VERSION ""

NS_ :

BS_:

BU_: CANOE BSM BSM2 CADM CVADAS ECM EPS ORC EVCU2

BO_ 2654552196 Distance_Point_Map_1: 64 CVADAS
 SG_ Point_Map_Cruising_Age_15 : 482|6@1+ (1,0) [0|63] ""  CANOE
 SG_ Point_Map_Cruising_Age_14 : 418|6@1+ (1,0) [0|63] ""  CANOE
 SG_ Point_Map_Cruising_Age_13 : 354|6@1+ (1,0) [0|63] ""  CANOE
 SG_ Point_Map_Cruising_Age_12 : 290|6@1+ (1,0) [0|63] ""  CANOE
 SG_ Point_Map_Cruising_Age_11 : 226|6@1+ (1,0) [0|63] ""  CANOE
 SG_ Point_Map_Cruising_Age_10 : 162|6@1+ (1,0) [0|63] ""  CANOE
 SG_ Point_Map_Cruising_Age_9 : 98|6@1+ (1,0) [0|63] ""  CANOE
 SG_ Point_Map_Cruising_Age_8 : 34|6@1+ (1,0) [0|63] ""  CANOE
 SG_ Point_Map_Reserved_8 : 56|8@1+ (1,0) [0|255] ""  CANOE
 SG_ Point_Map_Age_8 : 48|8@1+ (1,0) [0|255] ""  CANOE
 SG_ Point_Map_Confidence_8 : 40|8@1+ (1,0) [0|255] ""  CANOE
 SG_ Point_Map_Height_8 : 32|2@1+ (1,0) [0|3] ""  CANOE
 SG_ Point_Map_Y_8 : 16|16@1- (1,0) [-32768|32767] ""  CANOE
 SG_ Point_Map_X_8 : 0|16@1- (1,0) [-32768|32767] ""  CANOE
 SG_ Point_Map_Reserved_15 : 504|8@1+ (1,0) [0|255] ""  CANOE
 SG_ Point_Map_Reserved_14 : 440|8@1+ (1,0) [0|255] ""  CANOE
 SG_ Point_Map_Reserved_13 : 376|8@1+ (1,0) [0|255] ""  CANOE
 SG_ Point_Map_Reserved_12 : 312|8@1+ (1,0) [0|255] ""  CANOE
 SG_ Point_Map_Reserved_11 : 248|8@1+ (1,0) [0|255] ""  CANOE
 SG_ Point_Map_Reserved_10 : 184|8@1+ (1,0) [0|255] ""  CANOE
 SG_ Point_Map_Reserved_9 : 120|8@1+ (1,0) [0|255] ""  CANOE
 SG_ Point_Map_Age_15 : 496|8@1+ (1,0) [0|255] ""  CANOE
 SG_ Point_Map_Confidence_15 : 488|8@1+ (1,0) [0|255] ""  CANOE
 SG_ Point_Map_Height_15 : 480|2@1+ (1,0) [0|3] ""  CANOE
 SG_ Point_Map_Y_15 : 464|16@1- (1,0) [-32768|32767] ""  CANOE
 SG_ Point_Map_X_15 : 448|16@1- (1,0) [-32768|32767] ""  CANOE
 SG_ Point_Map_Age_14 : 432|8@1+ (1,0) [0|255] ""  CANOE
 SG_ Point_Map_Confidence_14 : 424|8@1+ (1,0) [0|255] ""  CANOE
 SG_ Point_Map_Height_14 : 416|2@1+ (1,0) [0|3] ""  CANOE
 SG_ Point_Map_Y_14 : 400|16@1- (1,0) [-32768|32767] ""  CANOE
 SG_ Point_Map_X_14 : 384|16@1- (1,0) [-32768|32767] ""  CANOE
 SG_ Point_Map_Age_13 : 368|8@1+ (1,0) [0|255] ""  CANOE
 SG_ Point_Map_Confidence_13 : 360|8@1+ (1,0) [0|255] ""  CANOE
 SG_ Point_Map_Height_13 : 352|2@1+ (1,0) [0|3] ""  CANOE
 SG_ Point_Map_Y_13 : 336|16@1- (1,0) [-32768|32767] ""  CANOE
 SG_ Point_Map_X_13 : 320|16@1- (1,0) [-32768|32767] ""  CANOE
 SG_ Point_Map_Age_12 : 304|8@1+ (1,0) [0|255] ""  CANOE
 SG_ Point_Map_Confidence_12 : 296|8@1+ (1,0) [0|255] ""  CANOE
 SG_ Point_Map_Height_12 : 288|2@1+ (1,0) [0|3] ""  CANOE
 SG_ Point_Map_Y_12 : 272|16@1- (1,0) [-32768|32767] ""  CANOE
 SG_ Point_Map_X_12 : 256|16@1- (1,0) [-32768|32767] ""  CANOE
 SG_ Point_Map_Age_11 : 240|8@1+ (1,0) [0|255] ""  CANOE
 SG_ Point_Map_Confidence_11 : 232|8@1+ (1,0) [0|255] ""  CANOE
 SG_ Point_Map_Height_11 : 224|2@1+ (1,0) [0|3] ""  CANOE
 SG_ Point_Map_Y_11 : 208|16@1- (1,0) [-32768|32767] ""  CANOE
 SG_ Point_Map_X_11 : 192|16@1- (1,0) [-32768|32767] ""  CANOE
 SG_ Point_Map_Age_10 : 176|8@1+ (1,0) [0|255] ""  CANOE
 SG_ Point_Map_Confidence_10 : 168|8@1+ (1,0) [0|255] ""  CANOE
 SG_ Point_Map_Height_10 : 160|2@1+ (1,0) [0|3] ""  CANOE
 SG_ Point_Map_Y_10 : 144|16@1- (1,0) [-32768|32767] ""  CANOE
 SG_ Point_Map_X_10 : 128|16@1- (1,0) [-32768|32767] ""  CANOE
 SG_ Point_Map_Age_9 : 112|8@1+ (1,0) [0|255] ""  CANOE
 SG_ Point_Map_Confidence_9 : 104|8@1+ (1,0) [0|255] ""  CANOE
 SG_ Point_Map_Height_9 : 96|2@1+ (1,0) [0|3] ""  CANOE
 SG_ Point_Map_Y_9 : 80|16@1- (1,0) [-32768|32767] ""  CANOE
 SG_ Point_Map_X_9 : 64|16@1- (1,0) [-32768|32767] ""  CANOE

BO_ 2654552195 Distance_Point_Map_0: 64 CVADAS
 SG_ Point_Map_Cruising_Age_7 : 482|6@1+ (1,0) [0|63] ""  CANOE
 SG_ Point_Map_Cruising_Age_6 : 418|6@1+ (1,0) [0|63] ""  CANOE
 SG_ Point_Map_Cruising_Age_5 : 354|6@1+ (1,0) [0|63] ""  CANOE
 SG_ Point_Map_Cruising_Age_4 : 290|6@1+ (1,0) [0|63] ""  CANOE
 SG_ Point_Map_Cruising_Age_3 : 226|6@1+ (1,0) [0|63] ""  CANOE
 SG_ Point_Map_Cruising_Age_2 : 162|6@1+ (1,0) [0|63] ""  CANOE
 SG_ Point_Map_Cruising_Age_1 : 98|6@1+ (1,0) [0|63] ""  CANOE
 SG_ Point_Map_Cruising_Age_0 : 34|6@1+ (1,0) [0|63] ""  CANOE
 SG_ Point_Map_Reserved_7 : 504|8@1+ (1,0) [0|255] ""  CANOE
 SG_ Point_Map_Reserved_6 : 440|8@1+ (1,0) [0|255] ""  CANOE
 SG_ Point_Map_Reserved_5 : 376|8@1+ (1,0) [0|255] ""  CANOE
 SG_ Point_Map_Reserved_4 : 312|8@1+ (1,0) [0|255] ""  CANOE
 SG_ Point_Map_Reserved_3 : 248|8@1+ (1,0) [0|255] ""  CANOE
 SG_ Point_Map_Reserved_2 : 184|8@1+ (1,0) [0|255] ""  CANOE
 SG_ Point_Map_Reserved_1 : 120|8@1+ (1,0) [0|255] ""  CANOE
 SG_ Point_Map_Reserved_0 : 56|8@1+ (1,0) [0|255] ""  CANOE
 SG_ Point_Map_Age_7 : 496|8@1+ (1,0) [0|255] ""  CANOE
 SG_ Point_Map_Confidence_7 : 488|8@1+ (1,0) [0|255] ""  CANOE
 SG_ Point_Map_Height_7 : 480|2@1+ (1,0) [0|3] ""  CANOE
 SG_ Point_Map_Y_7 : 464|16@1- (1,0) [-32768|32767] ""  CANOE
 SG_ Point_Map_X_7 : 448|16@1- (1,0) [-32768|32767] ""  CANOE
 SG_ Point_Map_Age_6 : 432|8@1+ (1,0) [0|255] ""  CANOE
 SG_ Point_Map_Confidence_6 : 424|8@1+ (1,0) [0|255] ""  CANOE
 SG_ Point_Map_Height_6 : 416|2@1+ (1,0) [0|3] ""  CANOE
 SG_ Point_Map_Y_6 : 400|16@1- (1,0) [-32768|32767] ""  CANOE
 SG_ Point_Map_X_6 : 384|16@1- (1,0) [-32768|32767] ""  CANOE
 SG_ Point_Map_Age_5 : 368|8@1+ (1,0) [0|255] ""  CANOE
 SG_ Point_Map_Confidence_5 : 360|8@1+ (1,0) [0|255] ""  CANOE
 SG_ Point_Map_Height_5 : 352|2@1+ (1,0) [0|3] ""  CANOE
 SG_ Point_Map_Y_5 : 336|16@1- (1,0) [-32768|32767] ""  CANOE
 SG_ Point_Map_X_5 : 320|16@1- (1,0) [-32768|32767] ""  CANOE
 SG_ Point_Map_Age_4 : 304|8@1+ (1,0) [0|255] ""  CANOE
 SG_ Point_Map_Confidence_4 : 296|8@1+ (1,0) [0|255] ""  CANOE
 SG_ Point_Map_Height_4 : 288|2@1+ (1,0) [0|3] ""  CANOE
 SG_ Point_Map_Y_4 : 272|16@1- (1,0) [-32768|32767] ""  CANOE
 SG_ Point_Map_X_4 : 256|16@1- (1,0) [-32768|32767] ""  CANOE
 SG_ Point_Map_Age_3 : 240|8@1+ (1,0) [0|255] ""  CANOE
 SG_ Point_Map_Confidence_3 : 232|8@1+ (1,0) [0|255] ""  CANOE
 SG_ Point_Map_Height_3 : 224|2@1+ (1,0) [0|3] ""  CANOE
 SG_ Point_Map_Y_3 : 208|16@1- (1,0) [-32768|32767] ""  CANOE
 SG_ Point_Map_X_3 : 192|16@1- (1,0) [-32768|32767] ""  CANOE
 SG_ Point_Map_Age_2 : 176|8@1+ (1,0) [0|255] ""  CANOE
 SG_ Point_Map_Confidence_2 : 168|8@1+ (1,0) [0|255] ""  CANOE
 SG_ Point_Map_Height_2 : 160|2@1+ (1,0) [0|3] ""  CANOE
 SG_ Point_Map_Y_2 : 144|16@1- (1,0) [-32768|32767] ""  CANOE
 SG_ Point_Map_X_2 : 128|16@1- (1,0) [-32768|32767] ""  CANOE
 SG_ Point_Map_Age_1 : 112|8@1+ (1,0) [0|255] ""  CANOE
 SG_ Point_Map_Confidence_1 : 104|8@1+ (1,0) [0|255] ""  CANOE
 SG_ Point_Map_Height_1 : 96|2@1+ (1,0) [0|3] ""  CANOE
 SG_ Point_Map_Y_1 : 80|16@1- (1,0) [-32768|32767] ""  CANOE
 SG_ Point_Map_X_1 : 64|16@1- (1,0) [-32768|32767] ""  CANOE
 SG_ Point_Map_Age_0 : 48|8@1+ (1,0) [0|255] ""  CANOE
 SG_ Point_Map_Confidence_0 : 40|8@1+ (1,0) [0|255] ""  CANOE
 SG_ Point_Map_Height_0 : 32|2@1+ (1,0) [0|3] ""  CANOE
 SG_ Point_Map_Y_0 : 16|16@1- (1,0) [-32768|32767] ""  CANOE
 SG_ Point_Map_X_0 : 0|16@1- (1,0) [-32768|32767] ""  CANOE

BO_ 2654552194 DebugModelOutput: 64 CVADAS
 SG_ IeAP_cm_RearRightMinXDist_KPI : 176|12@1+ (1,0) [0|2000] "cm"  CANOE
 SG_ IeAP_cm_RearRightMinXDist : 160|12@1+ (1,0) [0|2000] "cm"  CANOE
 SG_ IeAP_cm_RearLeftMinXDist_KPI : 144|12@1+ (1,0) [0|2000] "cm"  CANOE
 SG_ IeAP_cm_RearLeftMinXDist : 128|12@1+ (1,0) [0|2000] "cm"  CANOE
 SG_ IeAP_cm_RearCenterMinXDist_KPI : 112|12@1+ (1,0) [0|2000] "cm"  CANOE
 SG_ IeAP_cm_RearCenterMinXDist : 96|12@1+ (1,0) [0|2000] "cm"  CANOE
 SG_ IeAP_cm_FrntRightMinXDist_KPI : 80|12@1+ (1,0) [0|2000] "cm"  CANOE
 SG_ IeAP_cm_FrntRightMinXDist : 64|12@1+ (1,0) [0|2000] "cm"  CANOE
 SG_ IeAP_cm_FrntLeftMinXDist_KPI : 48|12@1+ (1,0) [0|2000] "cm"  CANOE
 SG_ IeAP_cm_FrntLeftMinXDist : 32|12@1+ (1,0) [0|2000] "cm"  CANOE
 SG_ IeAP_cm_FrntCenterMinXDist_KPI : 16|12@1+ (1,0) [0|2000] "cm"  CANOE
 SG_ IeAP_cm_FrntCenterMinXDist : 0|12@1+ (1,0) [0|2000] "cm"  CANOE

BO_ 2654814232 DebugModelOutput_Feature_KPI_Tx: 64 CVADAS
 SG_ IeAP_cm_RearRightMinXDist_KPI : 60|12@1+ (1,0) [0|2000] "cm"  CANOE
 SG_ IeAP_cm_RearLeftMinXDist_KPI : 48|12@1+ (1,0) [0|2000] "cm"  CANOE
 SG_ IeAP_cm_RearCenterMinXDist_KPI : 36|12@1+ (1,0) [0|2000] "cm"  CANOE
 SG_ IeAP_cm_FrntRightMinXDist_KPI : 24|12@1+ (1,0) [0|2000] "cm"  CANOE
 SG_ IeAP_cm_FrntLeftMinXDist_KPI : 12|12@1+ (1,0) [0|2000] "cm"  CANOE
 SG_ IeAP_cm_FrntCenterMinXDist_KPI : 0|12@1+ (1,0) [0|2000] "cm"  CANOE

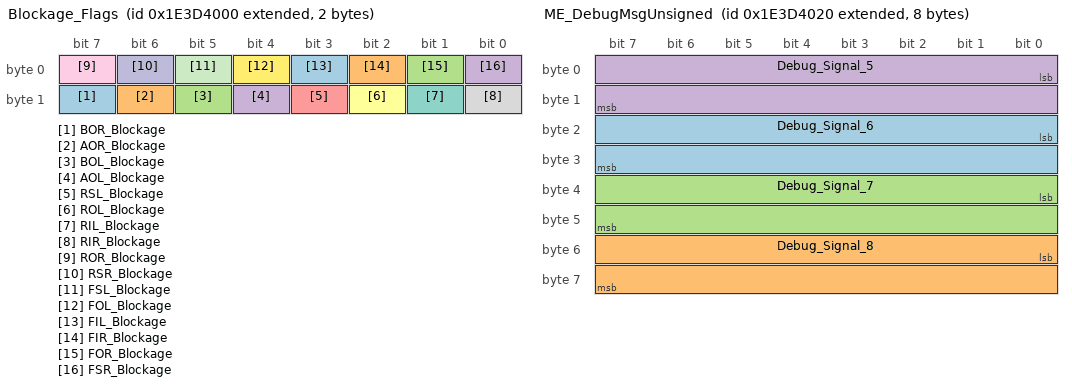
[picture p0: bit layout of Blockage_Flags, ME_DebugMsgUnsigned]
BO_ 2654814208 Blockage_Flags: 2 CVADAS
 SG_ BOR_Blockage : 15|1@1+ (1,0) [0|1] ""  CANOE
 SG_ AOR_Blockage : 14|1@1+ (1,0) [0|1] ""  CANOE
 SG_ BOL_Blockage : 13|1@1+ (1,0) [0|1] ""  CANOE
 SG_ AOL_Blockage : 12|1@1+ (1,0) [0|1] ""  CANOE
 SG_ RSL_Blockage : 11|1@1+ (1,0) [0|1] ""  CANOE
 SG_ ROL_Blockage : 10|1@1+ (1,0) [0|1] ""  CANOE
 SG_ RIL_Blockage : 9|1@1+ (1,0) [0|1] ""  CANOE
 SG_ RIR_Blockage : 8|1@1+ (1,0) [0|1] ""  CANOE
 SG_ ROR_Blockage : 7|1@1+ (1,0) [0|1] ""  CANOE
 SG_ RSR_Blockage : 6|1@1+ (1,0) [0|1] ""  CANOE
 SG_ FSL_Blockage : 5|1@1+ (1,0) [0|1] ""  CANOE
 SG_ FOL_Blockage : 4|1@1+ (1,0) [0|1] ""  CANOE
 SG_ FIL_Blockage : 3|1@1+ (1,0) [0|1] ""  CANOE
 SG_ FIR_Blockage : 2|1@1+ (1,0) [0|1] ""  CANOE
 SG_ FOR_Blockage : 1|1@1+ (1,0) [0|1] ""  CANOE
 SG_ FSR_Blockage : 0|1@1+ (1,0) [0|1] ""  CANOE

BO_ 2654552193 FODDebug: 64 CVADAS
 SG_ cntrCvpamFdData1_u16 : 160|16@1+ (1,0) [0|65535] ""  CANOE
 SG_ crcCvpamFdData1_u8 : 152|8@1+ (1,0) [0|255] ""  CANOE
 SG_ msgcntrCvpamFdData1_u8 : 144|8@1+ (1,0) [0|255] ""  CANOE
 SG_ macCvpamFdData1_u64 : 80|64@1+ (1,0) [0|1.84467440737096E+019] ""  CANOE
 SG_ obj_Pos_Longi : 48|32@1- (1,0) [-3.4E+038|3.4E+038] ""  CANOE
 SG_ obj_Pos_Lat : 16|32@1- (1,0) [-3.4E+038|3.4E+038] ""  CANOE
 SG_ objConf_e : 8|2@1+ (1,0) [0|3] ""  CANOE
 SG_ FrontSensorDetHealth_e : 0|2@1+ (1,0) [0|3] ""  CANOE

BO_ 2654552192 THADebugInfo2: 64 CVADAS
 SG_ MeTHA_px_CplrPntY : 214|32@1- (1,0) [0|1280] ""  CANOE
 SG_ MeTHA_px_CplrPntX : 182|32@1- (1,0) [0|1920] ""  CANOE
 SG_ MeTHA_px_HitchPntY : 150|32@1- (1,0) [0|1280] ""  CANOE
 SG_ MeTHA_px_HitchPntX : 118|32@1- (1,0) [0|1920] ""  CANOE
 SG_ MeTHA_pct_CplrTrckConf : 110|8@1+ (1,0) [0|100] ""  CANOE
 SG_ MeTHA_pct_CplrDetConf : 102|8@1+ (1,0) [0|100] ""  CANOE
 SG_ MeTHA_px_HitchCplrPixDiffLat : 70|32@1- (1,0) [0|1920] ""  CANOE
 SG_ MeTHA_px_HitchCplrPixDiffLong : 38|32@1- (1,0) [0|1280] ""  CANOE
 SG_ MeTHA_deg_CplrAng : 6|32@1- (0.5,0) [0|180] ""  CANOE
 SG_ MeTHA_e_CplrDetctStatus : 3|3@1+ (1,0) [0|2] ""  CANOE
 SG_ MeTHA_e_HitchDetctStatus : 0|3@1+ (1,0) [0|2] ""  CANOE

BO_ 2654552185 THADebugInfo1: 64 CVADAS
 SG_ MeTHA_deg_RoadWhlAng : 36|32@1- (0.001,0) [-180|180] ""  CANOE
 SG_ MeTHA_b_THAAbortStatus : 18|1@1+ (1,0) [0|1] ""  CANOE
 SG_ MeTHA_b_UsrCplrSelCnfm : 17|1@1+ (1,0) [0|1] ""  CANOE
 SG_ MeTHA_b_UsrHitchCnfm : 16|1@1+ (1,0) [0|1] ""  CANOE
 SG_ MeTHA_e_THAStateInfo : 28|8@1+ (1,0) [0|10] ""  CANOE
 SG_ MeTHA_e_RearBrkSupprInfo : 14|2@1+ (1,0) [0|2] ""  CANOE
 SG_ MeTHA_e_ScreenRequest : 20|8@1+ (1,0) [0|25] ""  CANOE
 SG_ MeTHA_b_EnblRearParkAsstTrg : 13|1@1+ (1,0) [0|1] ""  CANOE
 SG_ MeTHA_b_TrlrCplrStatus : 19|1@1+ (1,0) [0|1] ""  CANOE
 SG_ IeTHA_e_PamChimeTyp : 5|8@1+ (1,0) [0|15] ""  CANOE
 SG_ IeTHA_b_ChimeActvRhf : 3|1@1+ (1,0) [0|1] ""  CANOE
 SG_ IeTHA_b_ChimeActvLhf : 4|1@1+ (1,0) [0|1] ""  CANOE
 SG_ IeTHA_e_PamVol : 0|3@1+ (1,0) [0|3] ""  CANOE

BO_ 2654552184 LMD_LaneLinesDebug_1: 64 CVADAS
 SG_ LMD_m_Line_2_End_Range : 368|32@1- (0.5,0) [-25|38.5] ""  CANOE
 SG_ LMD_m_Line_2_Start_Range : 336|32@1- (0.5,0) [-25|38.5] ""  CANOE
 SG_ LMD_rad_Line_2_Heading : 304|32@1- (0.000976562,0) [-0.357|0.6420234375] ""  CANOE
 SG_ LMD_m_Line_2_Offset : 272|32@1- (0.01,0) [-5|5.23] ""  CANOE
 SG_ LMD_e_Line_2_Type : 72|8@1+ (1,0) [0|15] ""  CANOE
 SG_ LMD_pct_Line_2_Confidence : 240|32@1- (0.1,0) [0|1.5] ""  CANOE
 SG_ LMD_px_Line_2_Curvature : 208|32@1- (9.77E-007,0) [-0.032|0.032027695] ""  CANOE
 SG_ LMD_m_Line_1_End_Range : 176|32@1- (0.5,0) [-25|38.5] ""  CANOE
 SG_ LMD_m_Line_1_Start_Range : 144|32@1- (0.5,0) [-25|38.5] ""  CANOE
 SG_ LMD_rad_Line_1_Heading : 112|32@1- (0.000976562,0) [-0.357|0.6420234375] ""  CANOE
 SG_ LMD_m_Line_1_Offset : 80|32@1- (0.01,0) [-5|5.23] ""  CANOE
 SG_ LMD_e_Line_1_Type : 64|8@1+ (1,0) [0|15] ""  CANOE
 SG_ LMD_px_Line_1_Curvature : 32|32@1- (9.77E-007,0) [-0.032|0.032027695] ""  CANOE
 SG_ LMD_pct_Line_1_Confidence : 0|32@1- (0.1,0) [0|1.5] ""  CANOE

BO_ 2654552183 MOT_Obj_8_9: 64 CVADAS
 SG_ MOT_ObjectDimensions_1_9 : 368|32@1- (0.0001,0) [3.4E-038|3.4E+038] ""  CANOE
 SG_ MOT_ObjectDimensions_0_9 : 336|32@1- (0.0001,0) [3.4E-038|3.4E+038] ""  CANOE
 SG_ MOT_ObjVelY_9 : 304|32@1- (0.0001,0) [3.4E-038|3.4E+038] ""  CANOE
 SG_ MOT_ObjVelX_9 : 272|32@1- (0.0001,0) [3.4E-038|3.4E+038] ""  CANOE
 SG_ MOT_ClosestPntDist_1_9 : 240|32@1- (0.0001,0) [3.4E-038|3.4E+038] ""  CANOE
 SG_ MOT_ClosestPntDist_0_9 : 208|32@1- (0.0001,0) [3.4E-038|3.4E+038] ""  CANOE
 SG_ MOT_ObjectDimensions_1_8 : 176|32@1- (0.0001,0) [3.4E-038|3.4E+038] ""  CANOE
 SG_ MOT_ObjectDimensions_0_8 : 144|32@1- (0.0001,0) [3.4E-038|3.4E+038] ""  CANOE
 SG_ MOT_ObjVelY_8 : 112|32@1- (0.0001,0) [3.4E-038|3.4E+038] ""  CANOE
 SG_ MOT_ObjVelX_8 : 80|32@1- (0.0001,0) [3.4E-038|3.4E+038] ""  CANOE
 SG_ MOT_ClosestPntDist_1_8 : 48|32@1- (0.0001,0) [3.4E-038|3.4E+038] ""  CANOE
 SG_ MOT_ClosestPntDist_0_8 : 16|32@1- (0.0001,0) [3.4E-038|3.4E+038] ""  CANOE
 SG_ MOT_ObjValid_9 : 1|1@1+ (1,0) [0|1] ""  CANOE
 SG_ MOT_ObjValid_8 : 0|1@1+ (1,0) [0|1] ""  CANOE

BO_ 2654552182 MOT_Obj_6_7: 64 CVADAS
 SG_ MOT_ObjectDimensions_1_7 : 368|32@1- (0.0001,0) [3.4E-038|3.4E+038] ""  CANOE
 SG_ MOT_ObjectDimensions_0_7 : 336|32@1- (0.0001,0) [3.4E-038|3.4E+038] ""  CANOE
 SG_ MOT_ObjVelY_7 : 304|32@1- (0.0001,0) [3.4E-038|3.4E+038] ""  CANOE
 SG_ MOT_ObjVelX_7 : 272|32@1- (0.0001,0) [3.4E-038|3.4E+038] ""  CANOE
 SG_ MOT_ClosestPntDist_1_7 : 240|32@1- (0.0001,0) [3.4E-038|3.4E+038] ""  CANOE
 SG_ MOT_ClosestPntDist_0_7 : 208|32@1- (0.0001,0) [3.4E-038|3.4E+038] ""  CANOE
 SG_ MOT_ObjectDimensions_1_6 : 176|32@1- (0.0001,0) [3.4E-038|3.4E+038] ""  CANOE
 SG_ MOT_ObjectDimensions_0_6 : 144|32@1- (0.0001,0) [3.4E-038|3.4E+038] ""  CANOE
 SG_ MOT_ObjVelY_6 : 112|32@1- (0.0001,0) [3.4E-038|3.4E+038] ""  CANOE
 SG_ MOT_ObjVelX_6 : 80|32@1- (0.0001,0) [3.4E-038|3.4E+038] ""  CANOE
 SG_ MOT_ClosestPntDist_1_6 : 48|32@1- (0.0001,0) [3.4E-038|3.4E+038] ""  CANOE
 SG_ MOT_ClosestPntDist_0_6 : 16|32@1- (0.0001,0) [3.4E-038|3.4E+038] ""  CANOE
 SG_ MOT_ObjValid_7 : 1|1@1+ (1,0) [0|1] ""  CANOE
 SG_ MOT_ObjValid_6 : 0|1@1+ (1,0) [0|1] ""  CANOE

BO_ 2654552181 MOT_Obj_4_5: 64 CVADAS
 SG_ MOT_ObjectDimensions_1_5 : 368|32@1- (0.0001,0) [3.4E-038|3.4E+038] ""  CANOE
 SG_ MOT_ObjectDimensions_0_5 : 336|32@1- (0.0001,0) [3.4E-038|3.4E+038] ""  CANOE
 SG_ MOT_ObjVelY_5 : 304|32@1- (0.0001,0) [3.4E-038|3.4E+038] ""  CANOE
 SG_ MOT_ObjVelX_5 : 272|32@1- (0.0001,0) [3.4E-038|3.4E+038] ""  CANOE
 SG_ MOT_ClosestPntDist_1_5 : 240|32@1- (0.0001,0) [3.4E-038|3.4E+038] ""  CANOE
 SG_ MOT_ClosestPntDist_0_5 : 208|32@1- (0.0001,0) [3.4E-038|3.4E+038] ""  CANOE
 SG_ MOT_ObjectDimensions_1_4 : 176|32@1- (0.0001,0) [3.4E-038|3.4E+038] ""  CANOE
 SG_ MOT_ObjectDimensions_0_4 : 144|32@1- (0.0001,0) [3.4E-038|3.4E+038] ""  CANOE
 SG_ MOT_ObjVelY_4 : 112|32@1- (0.0001,0) [3.4E-038|3.4E+038] ""  CANOE
 SG_ MOT_ObjVelX_4 : 80|32@1- (0.0001,0) [3.4E-038|3.4E+038] ""  CANOE
 SG_ MOT_ClosestPntDist_1_4 : 48|32@1- (0.0001,0) [3.4E-038|3.4E+038] ""  CANOE
 SG_ MOT_ClosestPntDist_0_4 : 16|32@1- (0.0001,0) [3.4E-038|3.4E+038] ""  CANOE
 SG_ MOT_ObjValid_5 : 1|1@1+ (1,0) [0|1] ""  CANOE
 SG_ MOT_ObjValid_4 : 0|1@1+ (1,0) [0|1] ""  CANOE

BO_ 2654552180 MOT_Obj_2_3: 64 CVADAS
 SG_ MOT_ObjectDimensions_1_3 : 368|32@1- (0.0001,0) [3.4E-038|3.4E+038] ""  CANOE
 SG_ MOT_ObjectDimensions_0_3 : 336|32@1- (0.0001,0) [3.4E-038|3.4E+038] ""  CANOE
 SG_ MOT_ObjVelY_3 : 304|32@1- (0.0001,0) [3.4E-038|3.4E+038] ""  CANOE
 SG_ MOT_ObjVelX_3 : 272|32@1- (0.0001,0) [3.4E-038|3.4E+038] ""  CANOE
 SG_ MOT_ClosestPntDist_1_3 : 240|32@1- (0.0001,0) [3.4E-038|3.4E+038] ""  CANOE
 SG_ MOT_ClosestPntDist_0_3 : 208|32@1- (0.0001,0) [3.4E-038|3.4E+038] ""  CANOE
 SG_ MOT_ObjectDimensions_1_2 : 176|32@1- (0.0001,0) [3.4E-038|3.4E+038] ""  CANOE
 SG_ MOT_ObjectDimensions_0_2 : 144|32@1- (0.0001,0) [3.4E-038|3.4E+038] ""  CANOE
 SG_ MOT_ObjVelY_2 : 112|32@1- (0.0001,0) [3.4E-038|3.4E+038] ""  CANOE
 SG_ MOT_ObjVelX_2 : 80|32@1- (0.0001,0) [3.4E-038|3.4E+038] ""  CANOE
 SG_ MOT_ClosestPntDist_1_2 : 48|32@1- (0.0001,0) [3.4E-038|3.4E+038] ""  CANOE
 SG_ MOT_ClosestPntDist_0_2 : 16|32@1- (0.0001,0) [3.4E-038|3.4E+038] ""  CANOE
 SG_ MOT_ObjValid_3 : 1|1@1+ (1,0) [0|1] ""  CANOE
 SG_ MOT_ObjValid_2 : 0|1@1+ (1,0) [0|1] ""  CANOE

BO_ 2654552179 MOT_Obj_0_1: 64 CVADAS
 SG_ MOT_ObjValid_1 : 385|1@1+ (1,0) [0|1] ""  CANOE
 SG_ MOT_ObjValid_0 : 384|1@1+ (1,0) [0|1] ""  CANOE
 SG_ MOT_ObjectDimensions_1_1 : 352|32@1- (0.0001,0) [3.4E-038|3.4E+038] ""  CANOE
 SG_ MOT_ObjectDimensions_0_1 : 320|32@1- (0.0001,0) [3.4E-038|3.4E+038] ""  CANOE
 SG_ MOT_ObjVelY_1 : 288|32@1- (0.0001,0) [3.4E-038|3.4E+038] ""  CANOE
 SG_ MOT_ObjVelX_1 : 256|32@1- (0.0001,0) [3.4E-038|3.4E+038] ""  CANOE
 SG_ MOT_ClosestPntDist_1_1 : 224|32@1- (0.0001,0) [3.4E-038|3.4E+038] ""  CANOE
 SG_ MOT_ClosestPntDist_0_1 : 192|32@1- (0.0001,0) [3.4E-038|3.4E+038] ""  CANOE
 SG_ MOT_ObjectDimensions_1_0 : 160|32@1- (0.0001,0) [3.4E-038|3.4E+038] ""  CANOE
 SG_ MOT_ObjectDimensions_0_0 : 128|32@1- (0.0001,0) [3.4E-038|3.4E+038] ""  CANOE
 SG_ MOT_ObjVelY_0 : 96|32@1- (0.0001,0) [3.4E-038|3.4E+038] ""  CANOE
 SG_ MOT_ObjVelX_0 : 64|32@1- (0.0001,0) [3.4E-038|3.4E+038] ""  CANOE
 SG_ MOT_ClosestPntDist_1_0 : 32|32@1- (0.0001,0) [3.4E-038|3.4E+038] ""  CANOE
 SG_ MOT_ClosestPntDist_0_0 : 0|32@1- (0.0001,0) [3.4E-038|3.4E+038] ""  CANOE

BO_ 2654552178 Debug_FPA_HMI_InfoToVC: 64 CVADAS
 SG_ perpParkDirectionSel : 296|2@1+ (1,0) [0|2] ""  CANOE
 SG_ parkExtSideSel : 288|2@1+ (1,0) [0|2] ""  CANOE
 SG_ slotSide : 280|2@1+ (1,0) [0|2] ""  CANOE
 SG_ parkingDirection : 272|2@1+ (1,0) [0|2] ""  CANOE
 SG_ parkingSlotType : 264|3@1+ (1,0) [0|7] ""  CANOE
 SG_ IsBackSftbtnSel : 259|1@1+ (1,0) [0|1] ""  CANOE
 SG_ IsSlotSel : 258|1@1+ (1,0) [0|1] ""  CANOE
 SG_ IsExitSftBtnSel : 257|1@1+ (1,0) [0|1] ""  CANOE
 SG_ IsParkSftBtnSel : 256|1@1+ (1,0) [0|1] ""  CANOE
 SG_ MaAP_m_ParkSpot4RearStreetY : 224|32@1- (0.0001,0) [-15|15] ""  CANOE
 SG_ MaAP_m_ParkSpot4RearStreetX : 192|32@1- (0.0001,0) [-15|15] ""  CANOE
 SG_ MaAP_m_ParkSpot3RearBorderY : 160|32@1- (0.0001,0) [-15|15] ""  CANOE
 SG_ MaAP_m_ParkSpot3RearBorderX : 128|32@1- (0.0001,0) [-15|15] ""  CANOE
 SG_ MaAP_m_ParkSpot2FrntBorderY : 96|32@1- (0.0001,0) [-15|15] ""  CANOE
 SG_ MaAP_m_ParkSpot2FrntBorderX : 64|32@1- (0.0001,0) [-15|15] ""  CANOE
 SG_ MaAP_m_ParkSpot1FrntStreetY : 32|32@1- (0.0001,0) [-15|15] ""  CANOE
 SG_ MaAP_m_ParkSpot1FrntStreetX : 0|32@1- (0.0001,0) [-15|15] ""  CANOE

BO_ 2654552177 Debug_NFCD_Obj_5_9: 64 CVADAS
 SG_ IeVBII_nfcd_MinDisToCollisionObj : 336|32@1- (0.0001,0) [-15|15] ""  CANOE
 SG_ NFCD_ObjValid_9 : 68|1@1+ (1,0) [0|1] ""  CANOE
 SG_ NFCD_DistanceToClosestPoint_1_9 : 304|32@1- (0.0001,0) [-15|15] ""  CANOE
 SG_ NFCD_DistanceToClosestPoint_0_9 : 272|32@1- (0.0001,0) [-15|15] ""  CANOE
 SG_ NFCD_ObjValid_8 : 67|1@1+ (1,0) [0|1] ""  CANOE
 SG_ NFCD_DistanceToClosestPoint_1_8 : 240|32@1- (0.0001,0) [-15|15] ""  CANOE
 SG_ NFCD_DistanceToClosestPoint_0_8 : 208|32@1- (0.0001,0) [-15|15] ""  CANOE
 SG_ NFCD_ObjValid_7 : 66|1@1+ (1,0) [0|1] ""  CANOE
 SG_ NFCD_DistanceToClosestPoint_1_7 : 176|32@1- (0.0001,0) [-15|15] ""  CANOE
 SG_ NFCD_DistanceToClosestPoint_0_7 : 144|32@1- (0.0001,0) [-15|15] ""  CANOE
 SG_ NFCD_ObjValid_6 : 65|1@1+ (1,0) [0|1] ""  CANOE
 SG_ NFCD_DistanceToClosestPoint_1_6 : 112|32@1- (0.0001,0) [-15|15] ""  CANOE
 SG_ NFCD_DistanceToClosestPoint_0_6 : 80|32@1- (0.0001,0) [-15|15] ""  CANOE
 SG_ NFCD_ObjValid_5 : 64|1@1+ (1,0) [0|1] ""  CANOE
 SG_ NFCD_DistanceToClosestPoint_1_5 : 32|32@1- (0.0001,0) [-15|15] ""  CANOE
 SG_ NFCD_DistanceToClosestPoint_0_5 : 0|32@1- (0.0001,0) [-15|15] ""  CANOE

BO_ 2654552176 Debug_NFCD_Obj_0_4: 64 CVADAS
 SG_ NFCD_DistanceToClosestPoint_1_4 : 296|32@1- (0.0001,0) [-15|15] ""  CANOE
 SG_ NFCD_DistanceToClosestPoint_0_4 : 264|32@1- (0.0001,0) [-15|15] ""  CANOE
 SG_ NFCD_ObjValid_4 : 68|1@1+ (1,0) [0|1] ""  CANOE
 SG_ NFCD_ObjValid_3 : 67|1@1+ (1,0) [0|1] ""  CANOE
 SG_ NFCD_DistanceToClosestPoint_1_3 : 232|32@1- (0.0001,0) [-15|15] ""  CANOE
 SG_ NFCD_DistanceToClosestPoint_0_3 : 200|32@1- (0.0001,0) [-15|15] ""  CANOE
 SG_ NFCD_ObjValid_2 : 66|1@1+ (1,0) [0|1] ""  CANOE
 SG_ NFCD_DistanceToClosestPoint_1_2 : 168|32@1- (0.0001,0) [-15|15] ""  CANOE
 SG_ NFCD_DistanceToClosestPoint_0_2 : 136|32@1- (0.0001,0) [-15|15] ""  CANOE
 SG_ NFCD_ObjValid_1 : 65|1@1+ (1,0) [0|1] ""  CANOE
 SG_ NFCD_DistanceToClosestPoint_1_1 : 104|32@1- (0.0001,0) [-15|15] ""  CANOE
 SG_ NFCD_DistanceToClosestPoint_0_1 : 72|32@1- (0.0001,0) [-15|15] ""  CANOE
 SG_ NFCD_ObjValid_0 : 64|1@1+ (1,0) [0|1] ""  CANOE
 SG_ NFCD_DistanceToClosestPoint_1_0 : 32|32@1- (0.0001,0) [-15|15] ""  CANOE
 SG_ NFCD_DistanceToClosestPoint_0_0 : 0|32@1- (0.0001,0) [-15|15] ""  CANOE

BO_ 2654552169 Debug_AP_Variables: 64 CVADAS
 SG_ IeAutoPark_e_AlgoState : 344|3@1+ (1,0) [0|4] ""  CANOE
 SG_ IeAP_e_AutoParkStatus : 331|3@1+ (1,0) [0|6] ""  CANOE
 SG_ MeAP_e_ParkAssistStatus : 336|3@1+ (1,0) [0|4] ""  CANOE
 SG_ MeAP_e_Park_state : 299|32@1- (1,0) [-32768|32768] ""  CANOE
 SG_ MeAP_a_ThrtlCmd : 267|32@1- (0.0001,0) [3.4E-038|3.4E+038] ""  CANOE
 SG_ MeAP_a_BrkCmd : 235|32@1- (0.0001,0) [3.4E-038|3.4E+038] ""  CANOE
 SG_ MeAP_deg_StrCmd : 203|32@1- (0.0001,0) [3.4E-038|3.4E+038] ""  CANOE
 SG_ MeAP_b_PPPADisable : 202|1@1+ (1,0) [0|1] ""  CANOE
 SG_ MeAP_b_PPPADefEng : 201|1@1+ (1,0) [0|1] ""  CANOE
 SG_ MeAP_b_PPPAActv4LOW : 200|1@1+ (1,0) [0|1] ""  CANOE
 SG_ MeAP_b_PPPAActvTrlr : 199|1@1+ (1,0) [0|1] ""  CANOE
 SG_ MeAP_b_PARBDisable : 198|1@1+ (1,0) [0|1] ""  CANOE
 SG_ MeAP_b_PARBActv4LOW : 197|1@1+ (1,0) [0|1] ""  CANOE
 SG_ MeAP_b_PARBActvTrlr : 196|1@1+ (1,0) [0|1] ""  CANOE
 SG_ MeAP_b_RPAVolDefMed : 195|1@1+ (1,0) [0|1] ""  CANOE
 SG_ MeAP_b_FPAVolDefMed : 194|1@1+ (1,0) [0|1] ""  CANOE
 SG_ MeAP_b_PAVolDefMed : 193|1@1+ (1,0) [0|1] ""  CANOE
 SG_ MeAP_b_RPAActvTrlr : 192|1@1+ (1,0) [0|1] ""  CANOE
 SG_ MeAP_b_RPADisable : 191|1@1+ (1,0) [0|1] ""  CANOE
 SG_ MeAP_b_FPADisable : 190|1@1+ (1,0) [0|1] ""  CANOE
 SG_ MeAP_b_FeatureEnbl : 189|1@1+ (1,0) [0|1] ""  CANOE
 SG_ MeAP_b_VehCndSts : 188|1@1+ (1,0) [0|1] ""  CANOE
 SG_ IeAP_b_MnvPosOk : 187|1@1+ (1,0) [0|1] ""  CANOE
 SG_ MeAP_b_SteerActionReq : 186|1@1+ (1,0) [0|1] ""  CANOE
 SG_ MeAP_b_PosMet : 185|1@1+ (1,0) [0|1] ""  CANOE
 SG_ MeAP_b_ManeuverSuccess : 184|1@1+ (1,0) [0|1] ""  CANOE
 SG_ MeAP_b_ManeuverAbort : 183|1@1+ (1,0) [0|1] ""  CANOE
 SG_ MeAP_b_BSMHandshakeActv : 182|1@1+ (1,0) [0|1] ""  CANOE
 SG_ MeAP_b_StandStill : 181|1@1+ (1,0) [0|1] ""  CANOE
 SG_ MeAP_b_DriverOverride : 180|1@1+ (1,0) [0|1] ""  CANOE
 SG_ MeAP_b_APInitSts : 179|1@1+ (1,0) [0|1] ""  CANOE
 SG_ MeAP_b_SeekSpdExceedTimeout : 178|1@1+ (1,0) [0|1] ""  CANOE
 SG_ MeAP_b_PausedPressBtnTimeout : 177|1@1+ (1,0) [0|1] ""  CANOE
 SG_ MeAP_b_ObjInPathTimeout : 176|1@1+ (1,0) [0|1] ""  CANOE
 SG_ MeAP_b_CamHandshakeTimeout : 175|1@1+ (1,0) [0|1] ""  CANOE
 SG_ MeAP_b_GearShiftWaitTimeout : 174|1@1+ (1,0) [0|1] ""  CANOE
 SG_ MeAP_b_EPSInterfaceTimeout : 173|1@1+ (1,0) [0|1] ""  CANOE
 SG_ MeAP_b_BSMInterfaceTimeout : 172|1@1+ (1,0) [0|1] ""  CANOE
 SG_ MeAP_b_VCOpPaused : 171|1@1+ (1,0) [0|1] ""  CANOE
 SG_ MeAP_b_RPAwithBrkStatus : 170|1@1+ (1,0) [0|1] ""  CANOE
 SG_ MeAP_b_RPAStatus : 169|1@1+ (1,0) [0|1] ""  CANOE
 SG_ MeAP_b_FPAStatus : 168|1@1+ (1,0) [0|1] ""  CANOE
 SG_ IeAP_e_AbortCon : 160|8@1+ (1,0) [0|255] ""  CANOE
 SG_ IeAP_cnt_CurrentVehSweep : 152|8@1+ (1,0) [0|255] ""  CANOE
 SG_ MeAP_e_PP_state : 144|8@1- (1,0) [-128|127] ""  CANOE
 SG_ MeAP_cm_RearRightMinXDist : 128|16@1- (1,0) [-32768|32768] ""  CANOE
 SG_ MeAP_cm_RearLeftMinXDist : 112|16@1- (1,0) [-32768|32768] ""  CANOE
 SG_ MeAP_cm_RearCenterMinXDist : 96|16@1- (1,0) [-32768|32768] ""  CANOE
 SG_ MeAP_cm_FrntRightMinXDist : 80|16@1- (1,0) [-32768|32768] ""  CANOE
 SG_ MeAP_cm_FrntLeftMinXDist : 64|16@1- (1,0) [-32768|32768] ""  CANOE
 SG_ MeAP_cm_FrntCenterMinXDist : 48|16@1- (1,0) [-32768|32768] ""  CANOE
 SG_ MeAP_cnt_TransDebugVar_Copy_1 : 32|16@1- (1,0) [-32768|32768] ""  CANOE
 SG_ MeAP_cnt_TransDebugVar : 16|16@1+ (1,0) [0|512] ""  CANOE
 SG_ MeAP_cnt_StateDebugVar : 0|16@1+ (1,0) [0|512] ""  CANOE

BO_ 2654552168 TRSC_FID_DebugMessage: 64 CVADAS
 SG_ m_QM_FID_TRSC_ASCMDef : 40|8@1+ (1,0) [0|255] ""  CANOE
 SG_ m_QM_FID_TRSC_LIMITED_DefView : 32|8@1+ (1,0) [0|255] ""  CANOE
 SG_ m_QM_FID_TRSC_CAM_CAL_ABORT : 24|8@1+ (1,0) [0|255] ""  CANOE
 SG_ m_QM_FID_TRSC_LIMITED_View : 16|8@1+ (1,0) [0|255] ""  CANOE
 SG_ m_QM_FID_TRSC_DISABLED : 8|8@1+ (1,0) [0|255] ""  CANOE

BO_ 2654552167 TRSC_Detection_DebugMessage: 64 CVADAS
 SG_ Trailer_tracking_confidence : 95|32@1- (1,0) [0|100] ""  CANOE
 SG_ Trailer_Recognition_Confidence : 127|32@1- (1,0) [0|100] ""  CANOE
 SG_ OBTLRecalibrate : 48|1@1+ (1,0) [0|1] ""  CANOE
 SG_ Presentinfo : 49|3@1+ (1,0) [0|2] ""  CANOE
 SG_ RecognitionInfo : 52|1@1+ (1,0) [0|1] ""  CANOE
 SG_ trailerCalibrationDelay : 47|1@1+ (1,0) [0|1] ""  CANOE
 SG_ trailerCalibrationCount : 70|11@1+ (1,0) [0|10] ""  CANOE
 SG_ TrailerCalFailInfo : 53|3@1+ (1,0) [0|2] ""  CANOE
 SG_ Trailercalinfo : 56|3@1+ (1,0) [0|2] ""  CANOE
 SG_ turnaroundSubState : 59|3@1+ (1,0) [0|2] ""  CANOE
 SG_ calibrationCompleted : 39|1@1+ (1,0) [0|1] ""  CANOE
 SG_ JackknifeThrAngle : 159|32@1- (0.01,0) [-110|110] "deg"  CANOE
 SG_ JackknifeAngle : 191|32@1- (0.01,0) [-110|110] "deg"  CANOE
 SG_ hitchLength : 223|32@1- (0.01,0) [1000|2500] "mm"  CANOE
 SG_ curState : 62|8@1+ (1,0) [0|7] ""  CANOE
 SG_ CurrentTrailer_ID : 40|7@1+ (1,0) [0|6] ""  CANOE
 SG_ calibrationSubState : 36|3@1+ (1,0) [0|2] ""  CANOE
 SG_ TADAngleRate : 255|32@1- (0.01,0) [-110|110] "deg"  CANOE
 SG_ TrailerAngleSign : 32|4@1+ (1,0) [0|3] ""  CANOE
 SG_ trailerAngle : 0|32@1- (0.01,0) [-110|110] "deg"  CANOE

BO_ 2654552166 TRSC_Debug_Message3: 64 CVADAS
 SG_ ReservedSignal2 : 344|32@1- (1,0) [-3.403E+038|3.40282347E+038] ""  CANOE
 SG_ ReservedSignal1 : 312|32@1- (1,0) [-3.403E+038|3.40282347E+038] ""  CANOE
 SG_ MeTRSC_deg_TADAngleSMVC : 280|32@1- (1,0) [-110|110] ""  CANOE
 SG_ MeTRSC_e_TrlrCalInfoSMVC : 272|4@1+ (1,0) [0|2] ""  CANOE
 SG_ MeTRSC_b_OTBLReset : 264|8@1+ (1,0) [0|1] ""  CANOE
 SG_ MeTRSC_deg_StrCMD : 232|32@1- (0.1,0) [-720|720] "deg"  CANOE
 SG_ MeTRSC_b_TBLComputationDone : 224|8@1+ (1,0) [0|1] ""  CANOE
 SG_ MeTRSC_M_SteeringTorqInfo : 186|32@1- (0.1,0) [-8|791.21875] "NM"  CANOE
 SG_ MeTRSC_e_TrlrPrsntInfoCAN : 149|4@1+ (1,0) [0|3] ""  CANOE
 SG_ MeTRSC_b_TrlrRevSteeringStsInfo : 148|1@1+ (1,0) [0|1] ""  CANOE
 SG_ MeTRSC_b_TRSCSwitchPressed : 147|1@1+ (1,0) [0|1] ""  CANOE
 SG_ MeTRSC_b_OBTLRecalibrate : 185|1@1+ (1,0) [0|1] ""  CANOE
 SG_ MeSVS_e_DispView2Info : 66|16@1+ (1,0) [0|15] ""  CANOE
 SG_ MeTRSC_deg_KnobAngle : 153|32@1- (1,0) [-110|110] "deg"  CANOE
 SG_ MeTRSC_b_MoreCamSoftButtEnbl : 146|1@1+ (1,0) [0|1] ""  CANOE
 SG_ MeTRSC_deg_DetJackKnifeAngle : 114|32@1- (0.01,0) [-110|110] "deg"  CANOE
 SG_ MeTRSC_m_DetTrailerBeamLen : 82|32@1- (0.01,0) [1|20] "m"  CANOE
 SG_ MeTRSC_deg_DetJackknifeThrAngle : 34|32@1- (0.01,0) [-110|110] "deg"  CANOE
 SG_ MeTRSC_b_TrlrCalibPopInfo : 33|1@1+ (1,0) [0|1] ""  CANOE
 SG_ MeTRSC_b_TrlrCalibDelayInfo : 32|1@1+ (1,0) [0|1] ""  CANOE
 SG_ MeTRSC_cnt_TrlrCalibFailCntInfo : 0|32@1+ (1,0) [0|10] "count"  CANOE

BO_ 2654552165 TRSC_Debug_Message2: 64 CVADAS
 SG_ IeTRSC_e_TRSCAbortReas : 400|22@1+ (1,0) [0|21] ""  CANOE
 SG_ MeTRSC_e_TRSCStat : 384|8@1+ (1,0) [0|21] ""  CANOE
 SG_ IeTRSC_e_TrlrAngGrapOverSts : 352|22@1+ (1,0) [0|21] ""  CANOE
 SG_ IeTRSC_e_TRSCUnavailReas : 320|21@1+ (1,0) [0|20] ""  CANOE
 SG_ IeTRSC_e_CamBlockSts : 188|4@1+ (1,0) [0|3] ""  CANOE
 SG_ IeTRSC_kph_VehSpeedVSOSig : 288|32@1- (0.01,0) [-90|90] "deg"  CANOE
 SG_ IeTRSC_M_TRSCStrTrq : 256|32@1- (0.01,0) [-90|90] "deg"  CANOE
 SG_ IeTRSC_deg_JackknifeThrAngle : 224|32@1- (0.01,0) [-90|90] "deg"  CANOE
 SG_ IeTRSC_deg_TADAngle : 192|32@1- (0.01,0) [-90|90] "deg"  CANOE
 SG_ IeTRSC_deg_TrlrAngKnob : 156|32@1- (0.01,0) [-90|90] "deg"  CANOE
 SG_ IeTRSC_e_TrlrRecogInfo : 152|4@1+ (1,0) [0|3] ""  CANOE
 SG_ IeTRSC_e_TRSKMSts : 148|3@1+ (1,0) [0|2] ""  CANOE
 SG_ IeTRSC_e_TRSKMCenBtnSts : 144|4@1+ (1,0) [0|3] ""  CANOE
 SG_ IeTRSC_e_TRSKMBtnSts : 91|4@1+ (1,0) [0|3] ""  CANOE
 SG_ IeTRSC_e_TrailerID : 136|6@1+ (1,0) [0|5] ""  CANOE
 SG_ IeTRSC_e_GearShiftSts : 128|8@1+ (1,0) [0|7] ""  CANOE
 SG_ IeTRSC_deg_FrntWhlAng : 96|32@1- (0.1,0) [-40|40] "deg"  CANOE
 SG_ IeTRSC_e_TrlrPrsntSts : 88|3@1+ (1,0) [0|2] ""  CANOE
 SG_ IeTRSC_e_TrlrPrsntFailReas : 84|3@1+ (1,0) [0|2] ""  CANOE
 SG_ IeTRSC_e_TrlrCalibSts : 13|3@1+ (1,0) [0|2] ""  CANOE
 SG_ IeTRSC_e_TrlrCalibManState : 80|4@1+ (1,0) [0|3] ""  CANOE
 SG_ IeTRSC_e_TrlrCalibFailReas : 8|5@1+ (1,0) [0|4] ""  CANOE
 SG_ IeTRSC_cnt_TrlrCalibPassCntCurr : 64|16@1+ (1,0) [0|65535] "count"  CANOE
 SG_ IeTRSC_cnt_TrlrCalibPassCnt : 48|16@1+ (1,0) [0|65535] "count"  CANOE
 SG_ IeTRSC_cnt_TrlrCalibFailCntCurr : 32|16@1+ (1,0) [0|65535] "count"  CANOE
 SG_ IeTRSC_cnt_TrlrCalibFailCnt : 16|16@1+ (1,0) [0|65535] "count"  CANOE
 SG_ IeTRSC_cnt_KnobPos : 0|8@1+ (1,0) [0|255] "count"  CANOE

BO_ 2654552164 Debug_EOLCalib_Data_2: 64 CVADAS
 SG_ Roll_f32_EOL_Right : 352|32@1- (0.0001,0) [3.4E-038|3.4E+038] ""  CANOE
 SG_ Pitch_f32_EOL_Right : 320|32@1- (0.0001,0) [3.4E-038|3.4E+038] ""  CANOE
 SG_ Yaw_f32_EOL_Right : 288|32@1- (0.0001,0) [3.4E-038|3.4E+038] ""  CANOE
 SG_ Z_f32_EOL_Right : 256|32@1- (0.0001,0) [3.4E-038|3.4E+038] ""  CANOE
 SG_ Y_f32_EOL_Right : 224|32@1- (0.0001,0) [3.4E-038|3.4E+038] ""  CANOE
 SG_ X_f32_EOL_Right : 192|32@1- (0.0001,0) [3.4E-038|3.4E+038] ""  CANOE
 SG_ Pitch_f32_EOL_Rear : 160|32@1- (0.0001,0) [3.4E-038|3.4E+038] ""  CANOE
 SG_ Roll_f32_EOL_Rear : 128|32@1- (0.0001,0) [3.4E-038|3.4E+038] ""  CANOE
 SG_ Yaw_f32_EOL_Rear : 96|32@1- (0.0001,0) [3.4E-038|3.4E+038] ""  CANOE
 SG_ Z_f32_EOL_Rear : 64|32@1- (0.0001,0) [3.4E-038|3.4E+038] ""  CANOE
 SG_ Y_f32_EOL_Rear : 32|32@1- (0.0001,0) [3.4E-038|3.4E+038] ""  CANOE
 SG_ X_f32_EOL_Rear : 0|32@1- (0.0001,0) [3.4E-038|3.4E+038] ""  CANOE

BO_ 2654552163 Debug_CurrentCalib_Data_2: 64 CVADAS
 SG_ Z_f32_Current_Right : 352|32@1- (0.0001,0) [3.4E-038|3.4E+038] ""  CANOE
 SG_ Z_f32_Current_Rear : 320|32@1- (0.0001,0) [3.4E-038|3.4E+038] ""  CANOE
 SG_ Pitch_f32_Current_Right : 288|32@1- (0.0001,0) [3.4E-038|3.4E+038] ""  CANOE
 SG_ Pitch_f32_Current_Rear : 256|32@1- (0.0001,0) [3.4E-038|3.4E+038] ""  CANOE
 SG_ Roll_f32_Current_Right : 224|32@1- (0.0001,0) [3.4E-038|3.4E+038] ""  CANOE
 SG_ Roll_f32_Current_Rear : 192|32@1- (0.0001,0) [3.4E-038|3.4E+038] ""  CANOE
 SG_ Yaw_f32_Current_Right : 160|32@1- (0.0001,0) [3.4E-038|3.4E+038] ""  CANOE
 SG_ Yaw_f32_Current_Rear : 128|32@1- (0.0001,0) [3.4E-038|3.4E+038] ""  CANOE
 SG_ Y_f32_Current_Right : 96|32@1- (0.0001,0) [3.4E-038|3.4E+038] ""  CANOE
 SG_ Y_f32_Current_Rear : 64|32@1- (0.0001,0) [3.4E-038|3.4E+038] ""  CANOE
 SG_ X_f32_Current_Right : 32|32@1- (0.0001,0) [3.4E-038|3.4E+038] ""  CANOE
 SG_ X_f32_Current_Rear : 0|32@1- (0.0001,0) [3.4E-038|3.4E+038] ""  CANOE

BO_ 2654552162 Debug_FeatureCollection: 64 CVADAS
 SG_ InvalidFeatures_Right_u32 : 352|32@1+ (1,0) [0|4294967295] ""  CANOE
 SG_ IgnoredFeatures_Right_u32 : 320|32@1+ (1,0) [0|4294967295] ""  CANOE
 SG_ ValidFeatures_Right_u32 : 288|32@1+ (1,0) [0|4294967295] ""  CANOE
 SG_ InvalidFeatures_Rear_u32 : 256|32@1+ (1,0) [0|4294967295] ""  CANOE
 SG_ IgnoredFeatures_Rear_u32 : 224|32@1+ (1,0) [0|4294967295] ""  CANOE
 SG_ ValidFeatures_Rear_u32 : 192|32@1+ (1,0) [0|4294967295] ""  CANOE
 SG_ InvalidFeatures_Left_u32 : 160|32@1+ (1,0) [0|4294967295] ""  CANOE
 SG_ IgnoredFeatures_Left_u32 : 128|32@1+ (1,0) [0|4294967295] ""  CANOE
 SG_ ValidFeatures_Left_u32 : 96|32@1+ (1,0) [0|4294967295] ""  CANOE
 SG_ InvalidFeatures_Front_u32 : 64|32@1+ (1,0) [0|4294967295] ""  CANOE
 SG_ IgnoredFeatures_Front_u32 : 32|32@1+ (1,0) [0|4294967295] ""  CANOE
 SG_ ValidFeatures_Front_u32 : 0|32@1+ (1,0) [0|4294967295] ""  CANOE

BO_ 2654552161 Debug_TargetData: 64 CVADAS
 SG_ TargetDetectRightRear_Right_s8 : 208|8@1- (1,0) [-128|127] ""  CANOE
 SG_ TargetDetectRightFront_Right_s8 : 200|8@1- (1,0) [-128|127] ""  CANOE
 SG_ TargetDetectLeftRear_Right_s8 : 192|8@1- (1,0) [-128|127] ""  CANOE
 SG_ TargetDetectLeftFront_Right_s8 : 184|8@1- (1,0) [-128|127] ""  CANOE
 SG_ TargetLimitRear_Right_s8 : 176|8@1- (1,0) [-128|127] ""  CANOE
 SG_ TargetLimitFront_Right_s8 : 168|8@1- (1,0) [-128|127] ""  CANOE
 SG_ TargetInit_Right_s8 : 160|8@1- (1,0) [-128|127] ""  CANOE
 SG_ TargetDetectRightRear_Rear_s8 : 152|8@1- (1,0) [-128|127] ""  CANOE
 SG_ TargetDetectRightFront_Rear_s8 : 144|8@1- (1,0) [-128|127] ""  CANOE
 SG_ TargetDetectLeftRear_Rear_s8 : 136|8@1- (1,0) [-128|127] ""  CANOE
 SG_ TargetDetectLeftFront_Rear_s8 : 128|8@1- (1,0) [-128|127] ""  CANOE
 SG_ TargetLimitRear_Rear_s8 : 120|8@1- (1,0) [-128|127] ""  CANOE
 SG_ TargetLimitFront_Rear_s8 : 112|8@1- (1,0) [-128|127] ""  CANOE
 SG_ TargetInit_Rear_s8 : 104|8@1- (1,0) [-128|127] ""  CANOE
 SG_ TargetDetectRightRear_Left_s8 : 96|8@1- (1,0) [-128|127] ""  CANOE
 SG_ TargetDetectRightFront_Left_s8 : 88|8@1- (1,0) [-128|127] ""  CANOE
 SG_ TargetDetectLeftFront_Left_s8 : 80|8@1- (1,0) [-128|127] ""  CANOE
 SG_ TargetLimitRear_Left_s8 : 72|8@1- (1,0) [-128|127] ""  CANOE
 SG_ TargetLimitFront_Left_s8 : 64|8@1- (1,0) [-128|127] ""  CANOE
 SG_ TargetInit_Left_s8 : 56|8@1- (1,0) [-128|127] ""  CANOE
 SG_ TargetDetectRightRear_Front_s8 : 48|8@1- (1,0) [-128|127] ""  CANOE
 SG_ TargetDetectRightFront_Front_s8 : 40|8@1- (1,0) [-128|127] ""  CANOE
 SG_ TargetDetectLeftRear_Front_s8 : 32|8@1- (1,0) [-128|127] ""  CANOE
 SG_ TargetDetectLeftFront_Front_s8 : 24|8@1- (1,0) [-128|127] ""  CANOE
 SG_ TargetLimitRear_Front_s8 : 16|8@1- (1,0) [-128|127] ""  CANOE
 SG_ TargetLimitFront_Front_s8 : 8|8@1- (1,0) [-128|127] ""  CANOE
 SG_ TargetInit_Front_s8 : 0|8@1- (1,0) [-128|127] ""  CANOE

BO_ 2654552160 Debug_OCCalib_Data: 64 CVADAS
 SG_ Z_f32_Current_Rear : 448|32@1- (0.0001,0) [3.4E-038|3.4E+038] ""  CANOE
 SG_ Y_f32_Current_Rear : 416|32@1- (0.0001,0) [3.4E-038|3.4E+038] ""  CANOE
 SG_ X_f32_Current_Rear : 384|32@1- (0.0001,0) [3.4E-038|3.4E+038] ""  CANOE
 SG_ Pitch_f32_OC_Right : 352|32@1- (0.0001,0) [3.4E-038|3.4E+038] ""  CANOE
 SG_ Roll_f32_OC_Right : 320|32@1- (0.0001,0) [3.4E-038|3.4E+038] ""  CANOE
 SG_ Yaw_f32_OC_Right : 288|32@1- (0.0001,0) [3.4E-038|3.4E+038] ""  CANOE
 SG_ Pitch_f32_OC_Rear : 256|32@1- (0.0001,0) [3.4E-038|3.4E+038] ""  CANOE
 SG_ Roll_f32_OC_Rear : 224|32@1- (0.0001,0) [3.4E-038|3.4E+038] ""  CANOE
 SG_ Yaw_f32_OC_Rear : 192|32@1- (0.0001,0) [3.4E-038|3.4E+038] ""  CANOE
 SG_ Pitch_f32_OC_Left : 160|32@1- (0.0001,0) [3.4E-038|3.4E+038] ""  CANOE
 SG_ Roll_f32_OC_Left : 128|32@1- (0.0001,0) [3.4E-038|3.4E+038] ""  CANOE
 SG_ Yaw_f32_OC_Left : 96|32@1- (0.0001,0) [3.4E-038|3.4E+038] ""  CANOE
 SG_ Pitch_f32_OC_Front : 64|32@1- (0.0001,0) [3.4E-038|3.4E+038] ""  CANOE
 SG_ Roll_f32_OC_Front : 32|32@1- (0.0001,0) [3.4E-038|3.4E+038] ""  CANOE
 SG_ Yaw_f32_OC_Front : 0|32@1- (0.0001,0) [3.4E-038|3.4E+038] ""  CANOE

BO_ 2654552153 Debug_SCCalib_Data: 64 CVADAS
 SG_ Pitch_f32_SC_Right : 352|32@1- (0.0001,0) [3.4E-038|3.4E+038] ""  CANOE
 SG_ Roll_f32_SC_Right : 320|32@1- (0.0001,0) [3.4E-038|3.4E+038] ""  CANOE
 SG_ Yaw_f32_SC_Right : 288|32@1- (0.0001,0) [3.4E-038|3.4E+038] ""  CANOE
 SG_ Pitch_f32_SC_Rear : 256|32@1- (0.0001,0) [3.4E-038|3.4E+038] ""  CANOE
 SG_ Roll_f32_SC_Rear : 224|32@1- (0.0001,0) [3.4E-038|3.4E+038] ""  CANOE
 SG_ Yaw_f32_SC_Rear : 192|32@1- (0.0001,0) [3.4E-038|3.4E+038] ""  CANOE
 SG_ Pitch_f32_SC_Left : 160|32@1- (0.0001,0) [3.4E-038|3.4E+038] ""  CANOE
 SG_ Roll_f32_SC_Left : 128|32@1- (0.0001,0) [3.4E-038|3.4E+038] ""  CANOE
 SG_ Yaw_f32_SC_Left : 96|32@1- (0.0001,0) [3.4E-038|3.4E+038] ""  CANOE
 SG_ Pitch_f32_SC_Front : 64|32@1- (0.0001,0) [3.4E-038|3.4E+038] ""  CANOE
 SG_ Roll_f32_SC_Front : 32|32@1- (0.0001,0) [3.4E-038|3.4E+038] ""  CANOE
 SG_ Yaw_f32_SC_Front : 0|32@1- (0.0001,0) [3.4E-038|3.4E+038] ""  CANOE

BO_ 2654552152 Debug_EOLCalib_Data_1: 64 CVADAS
 SG_ Pitch_f32_EOL_Left : 352|32@1- (0.0001,0) [3.4E-038|3.4E+038] ""  CANOE
 SG_ Roll_f32_EOL_Left : 320|32@1- (0.0001,0) [3.4E-038|3.4E+038] ""  CANOE
 SG_ Yaw_f32_EOL_Left : 288|32@1- (0.0001,0) [3.4E-038|3.4E+038] ""  CANOE
 SG_ Z_f32_EOL_Left : 256|32@1- (0.0001,0) [3.4E-038|3.4E+038] ""  CANOE
 SG_ Y_f32_EOL_Left : 224|32@1- (0.0001,0) [3.4E-038|3.4E+038] ""  CANOE
 SG_ X_f32_EOL_Left : 192|32@1- (0.0001,0) [3.4E-038|3.4E+038] ""  CANOE
 SG_ Pitch_f32_EOL_Front : 160|32@1- (0.0001,0) [3.4E-038|3.4E+038] ""  CANOE
 SG_ Roll_f32_EOL_Front : 128|32@1- (0.0001,0) [3.4E-038|3.4E+038] ""  CANOE
 SG_ Yaw_f32_EOL_Front : 96|32@1- (0.0001,0) [3.4E-038|3.4E+038] ""  CANOE
 SG_ Z_f32_EOL_Front : 64|32@1- (0.0001,0) [3.4E-038|3.4E+038] ""  CANOE
 SG_ Y_f32_EOL_Front : 32|32@1- (0.0001,0) [3.4E-038|3.4E+038] ""  CANOE
 SG_ X_f32_EOL_Front : 0|32@1- (0.0001,0) [3.4E-038|3.4E+038] ""  CANOE

BO_ 2654552151 TRSC_Debug_Message1: 64 CVADAS
 SG_ ReservedTRSCSig2 : 464|32@1- (1,0) [-3.40282E+038|3.40282347E+038] ""  CANOE
 SG_ ReservedTRSCSig1 : 432|32@1- (1,0) [-3.40282E+038|3.40282347E+038] ""  CANOE
 SG_ MeTRSC_cnt_TRSCAliveCounter : 416|16@1+ (1,0) [0|65535] ""  CANOE
 SG_ MeTRSC_s_TRSCTimeTaken : 400|16@1+ (1,0) [0|65535] ""  CANOE
 SG_ MeTRSC_s_TRSCPeriodicity : 384|16@1- (1,0) [0|65535] "msec"  CANOE
 SG_ IeTRSC_pct_TrlrRecogConf : 349|32@1- (0.1,0) [0|100] "pct"  CANOE
 SG_ IeTRSC_pct_TrlrTrackConf : 285|32@1- (0.1,0) [0|100] "pct"  CANOE
 SG_ MeTRSC_m_HitchLength : 0|32@1- (0.01,0) [1000|2500] "mm"  CANOE
 SG_ IeTRSC_m_TrlrWhlBaseEff : 317|32@1- (0.01,0) [0|15000] "mm"  CANOE
 SG_ IeTRSC_pct_TrlrDetConf : 253|32@1- (0.1,0) [0|100] "pct"  CANOE
 SG_ MeTRSC_deg_JackKnifeAngle : 221|32@1- (0.01,0) [-110|110] "deg"  CANOE
 SG_ MeTRSC_m_TrailerBeamLen : 92|32@1- (0.01,0) [1|20] "m"  CANOE
 SG_ MeTRSC_e_TrlrAngSign : 76|1@1+ (1,0) [0|2] ""  CANOE
 SG_ MeTRSC_e_TrlrPrsntInfo : 81|1@1+ (1,0) [0|3] ""  CANOE
 SG_ MeTRSC_e_TrlrRecogInfo : 75|1@1+ (1,0) [0|1] ""  CANOE
 SG_ MeTRSC_e_TrlrCalInfo : 80|1@1+ (1,0) [0|1] ""  CANOE
 SG_ MeSVS_b_MoreCamReqSts : 220|1@1+ (1,0) [0|1] ""  CANOE
 SG_ MeTRSC_deg_JackknifeThrAngle : 188|32@1- (0.1,0) [-110|110] "deg"  CANOE
 SG_ MeTRSC_deg_TADAngleRate : 156|32@1- (0.1,0) [-110|110] "deg/sec"  CANOE
 SG_ MeTRSC_deg_MaxAllowedTADAngle : 124|32@1- (0.1,0) [-110|110] "deg"  CANOE
 SG_ MeTRSC_e_TrailerID : 85|7@1+ (1,0) [0|6] ""  CANOE
 SG_ MeTRSC_e_CalFail : 82|3@1+ (1,0) [0|2] ""  CANOE
 SG_ MeTRSC_e_TADCalibrationSubstate : 72|3@1+ (1,0) [0|2] ""  CANOE
 SG_ MeTRSC_e_TurnAroundSubState : 77|3@1+ (1,0) [0|2] ""  CANOE
 SG_ MeTRSC_e_TADState : 64|8@1+ (1,0) [0|7] ""  CANOE
 SG_ MeTRSC_deg_TADAngle : 32|32@1- (0.01,0) [-110|110] "deg"  CANOE

BO_ 2654552150 Debug_HMI_Internal_Data: 16 CVADAS
 SG_ LastViewBeforeTestPattern_e : 88|8@1+ (1,0) [0|25] ""  CANOE
 SG_ Prev_DisplayedViewByAcore_e : 80|8@1+ (1,0) [0|25] ""  CANOE
 SG_ Curr_DisplayedViewByAcore_e : 72|8@1+ (1,0) [0|25] ""  CANOE
 SG_ Prev_RequestedViewByHmiM_e : 64|8@1+ (1,0) [0|25] ""  CANOE
 SG_ Curr_RequestedViewByHmiM_e : 56|8@1+ (1,0) [0|25] ""  CANOE
 SG_ Prev_SystemState_e : 48|8@1+ (1,0) [0|2] ""  CANOE
 SG_ Curr_SystemState_e : 40|8@1+ (1,0) [0|2] ""  CANOE
 SG_ M_FFClatch_e : 32|8@1+ (1,0) [0|1] ""  CANOE
 SG_ M_BURV_Memory_e : 24|8@1+ (1,0) [0|1] ""  CANOE
 SG_ FRONT_TOP_BTN_PRESSED_b : 20|1@1+ (1,0) [0|1] ""  CANOE
 SG_ REAR_TOP_BTN_PRESSED_b : 19|1@1+ (1,0) [0|1] ""  CANOE
 SG_ MAGNIFIER_BTN_PRESSED_b : 18|1@1+ (1,0) [0|1] ""  CANOE
 SG_ X_BTN_PRESSED_b : 17|1@1+ (1,0) [0|1] ""  CANOE
 SG_ OFFROAD_ABSNT_MC_BTN_PRESSED_b : 16|1@1+ (1,0) [0|1] ""  CANOE
 SG_ OFFROAD_PRSNT_MC_BTN_PRESSED_b : 15|1@1+ (1,0) [0|1] ""  CANOE
 SG_ OFFRD_ABSNT_AUXCAM_BTN_PRESSED_b : 14|1@1+ (1,0) [0|1] ""  CANOE
 SG_ OFFRD_PRSNT_AUXCAM_BTN_PRESSED_b : 13|1@1+ (1,0) [0|1] ""  CANOE
 SG_ RVCONLY_BTN_PRESSED_b : 12|1@1+ (1,0) [0|1] ""  CANOE
 SG_ FFCV_BTN_PRESSED_b : 11|1@1+ (1,0) [0|1] ""  CANOE
 SG_ FRONT_CROSS_BTN_PRESSED_b : 10|1@1+ (1,0) [0|1] ""  CANOE
 SG_ REAR_CROSS_BTN_PRESSED_b : 9|1@1+ (1,0) [0|1] ""  CANOE
 SG_ IgnoreVehicleOffSpeed : 8|1@1+ (1,0) [0|1] ""  CANOE
 SG_ ZoomFactor_u8 : 0|8@1+ (1,0) [0|255] ""  CANOE

BO_ 2654552149 Debug_HMI_Input_Data: 64 CVADAS
 SG_ tchScrnStatus_e : 216|8@1+ (1,0) [0|7] ""  CANOE
 SG_ View_Error_e : 208|8@1+ (1,0) [0|0] ""  CANOE
 SG_ DynOvl_Error_e : 200|8@1+ (1,0) [0|0] ""  CANOE
 SG_ SoftBtn_Error_e : 192|8@1+ (1,0) [0|0] ""  CANOE
 SG_ ImageDefeat_Error_e : 184|8@1+ (1,0) [0|0] ""  CANOE
 SG_ tgwDispStatus_e : 176|8@1+ (1,0) [0|0] ""  CANOE
 SG_ CameraDisplaySts2_e : 168|8@1+ (1,0) [0|0] ""  CANOE
 SG_ prndStatus_e : 160|8@1+ (1,0) [0|0] ""  CANOE
 SG_ transEquipped_e : 152|8@1+ (1,0) [0|0] ""  CANOE
 SG_ ignitionStatus_e : 144|8@1+ (1,0) [0|0] ""  CANOE
 SG_ trscStat_e : 136|8@1+ (1,0) [0|0] ""  CANOE
 SG_ NetCfg_TRSCM_e : 128|8@1+ (1,0) [0|0] ""  CANOE
 SG_ revGear_e : 120|8@1+ (1,0) [0|0] ""  CANOE
 SG_ lrwsST_e : 112|8@1+ (1,0) [0|0] ""  CANOE
 SG_ GW_C_I6_timeout_b : 109|1@1+ (1,0) [0|1] ""  CANOE
 SG_ SVC_Delay_Feature_b : 108|1@1+ (1,0) [0|1] ""  CANOE
 SG_ SVC_FFCV_Gridlines_Feature_b : 107|1@1+ (1,0) [0|1] ""  CANOE
 SG_ SVC_Static_Gridlines_Feature_b : 106|1@1+ (1,0) [0|1] ""  CANOE
 SG_ SVC_Dynamic_Gridlines_Feature_b : 105|1@1+ (1,0) [0|1] ""  CANOE
 SG_ TopVideoBlanked_b : 104|1@1+ (1,0) [0|1] ""  CANOE
 SG_ LanguageSelection_u8 : 96|8@1+ (1,0) [0|255] ""  CANOE
 SG_ vehicleLine_e : 88|8@1+ (1,0) [0|255] ""  CANOE
 SG_ tchScrnCoord_s_Y_u16 : 80|8@1+ (1,0) [0|255] ""  CANOE
 SG_ tchScrnCoord_s_X_u16 : 72|8@1+ (1,0) [0|255] ""  CANOE
 SG_ CAM_NA_Bitfield_u8 : 64|8@1+ (1,0) [0|255] ""  CANOE
 SG_ vehicleSpeed_f32 : 32|32@1- (1,0) [3.4E-038|3.4E+038] ""  CANOE
 SG_ steeringWheelAngle_f32 : 0|32@1- (1,0) [3.4E-038|3.4E+038] ""  CANOE

BO_ 2654552148 Debug_HMI_Trailer_Views_Data: 64 CVADAS
 SG_ TrailerCalibrationStatus : 264|8@1+ (1,0) [0|2] ""  CANOE
 SG_ TrscStatus : 256|8@1+ (1,0) [0|7] ""  CANOE
 SG_ JackKnifeAngle : 224|32@1- (1,0) [3.4E-038|3.4E+038] ""  CANOE
 SG_ TrailerAngleSign : 136|8@1+ (1,0) [0|1] ""  CANOE
 SG_ Prev_TRG_Stat : 128|8@1+ (1,0) [0|3] ""  CANOE
 SG_ Curr_TRG_Stat : 120|8@1+ (1,0) [0|3] ""  CANOE
 SG_ ItbmTrailerStatus : 216|8@1+ (1,0) [0|255] ""  CANOE
 SG_ TrailerConnectionStatus : 80|8@1+ (1,0) [0|255] ""  CANOE
 SG_ TrailerWheelBase : 208|8@1+ (1,0) [0|255] ""  CANOE
 SG_ KnobAngle : 176|32@1- (1,0) [3.4E-038|3.4E+038] ""  CANOE
 SG_ MaxTadAngle : 144|32@1- (1,0) [3.4E-038|3.4E+038] ""  CANOE
 SG_ TadAngle : 88|32@1- (1,0) [3.4E-038|3.4E+038] ""  CANOE
 SG_ STM_v_TRGAUTO_BTN_PRESSED_b : 31|1@1+ (1,0) [0|1] ""  CANOE
 SG_ STM_v_TRGRIGHT_BTN_PRESSED_b : 30|1@1+ (1,0) [0|1] ""  CANOE
 SG_ STM_v_TRGLEFT_BTN_PRESSED_b : 29|1@1+ (1,0) [0|1] ""  CANOE
 SG_ M_Progress_Bar_Percentage : 72|8@1+ (1,0) [0|255] ""  CANOE
 SG_ M_Maneuver_Initial_Run : 64|8@1+ (1,0) [0|255] ""  CANOE
 SG_ M_Progress_Bar_Distance : 56|8@1+ (1,0) [0|255] ""  CANOE
 SG_ M_Cplr_Htch_Distance : 48|8@1+ (1,0) [0|255] ""  CANOE
 SG_ M_CPLR_POS_Y_u : 40|8@1+ (1,0) [0|255] ""  CANOE
 SG_ M_CPLR_POS_X_u : 32|8@1+ (1,0) [0|255] ""  CANOE
 SG_ M_THA_SFT_BTN_PRESSED_b : 28|1@1+ (1,0) [0|1] ""  CANOE
 SG_ M_START_BTN_PRESSED_b : 24|1@1+ (1,0) [0|1] ""  CANOE
 SG_ M_CONFIRM_BTN_PRESSED_b : 25|1@1+ (1,0) [0|1] ""  CANOE
 SG_ M_VIEW_SCRN_TCH_STS_b : 26|1@1+ (1,0) [0|1] ""  CANOE
 SG_ M_VIEW_ZOOM_STS_b : 27|1@1+ (1,0) [0|1] ""  CANOE
 SG_ M_Current_THA_State_On_Screen : 16|8@1+ (1,0) [0|255] ""  CANOE
 SG_ M_Current_THA_State_On_Zync : 8|8@1+ (1,0) [0|255] ""  CANOE
 SG_ M_Requested_THA_State : 0|8@1+ (1,0) [0|255] ""  CANOE

BO_ 2654552147 HMI_Curr_Displayed_ProxiConfig: 16 CVADAS
 SG_ MePRX_b_TRSCPresence : 70|1@1+ (1,0) [0|1] ""  CANOE
 SG_ MePRX_b_TRGPresence : 69|1@1+ (1,0) [0|1] ""  CANOE
 SG_ MePRX_b_CanNode27 : 68|1@1+ (1,0) [0|1] ""  CANOE
 SG_ MePRX_b_CANNode95 : 67|1@1+ (1,0) [0|1] ""  CANOE
 SG_ MePRX_b_AuxTrlrCam : 66|1@1+ (1,0) [0|1] ""  CANOE
 SG_ MePRX_b_FrwFacingCam : 65|1@1+ (1,0) [0|1] ""  CANOE
 SG_ MePRX_b_SurroundViewCamera : 64|1@1+ (1,0) [0|1] ""  CANOE
 SG_ MePRX_e_AutonomyLvl : 56|8@1+ (1,0) [0|255] ""  CANOE
 SG_ MePRX_e_PAMTunSet : 48|8@1+ (1,0) [0|255] ""  CANOE
 SG_ MePRX_e_MirrorType : 40|8@1+ (1,0) [0|255] ""  CANOE
 SG_ MePRX_e_RadDispType : 32|8@1+ (1,0) [0|255] ""  CANOE
 SG_ MePRX_e_SteerRatRackPinionType : 24|8@1+ (1,0) [0|255] ""  CANOE
 SG_ MePRX_e_Wheelbase : 16|8@1+ (1,0) [0|255] ""  CANOE
 SG_ MePRX_e_VehLineCfg : 8|8@1+ (1,0) [0|255] ""  CANOE
 SG_ MePRX_e_VariantID : 0|8@1+ (1,0) [0|255] ""  CANOE

BO_ 2654552146 HMI_Curr_Requested_ProxiConfig: 16 CVADAS
 SG_ MePRX_b_TRSCPresence : 112|1@1+ (1,0) [0|1] ""  CANOE
 SG_ MePRX_b_TRGPresence : 104|1@1+ (1,0) [0|1] ""  CANOE
 SG_ MePRX_b_CanNode27 : 96|1@1+ (1,0) [0|1] ""  CANOE
 SG_ MePRX_b_CANNode95 : 88|1@1+ (1,0) [0|1] ""  CANOE
 SG_ MePRX_b_AuxTrlrCam : 80|1@1+ (1,0) [0|1] ""  CANOE
 SG_ MePRX_b_FrwFacingCam : 72|1@1+ (1,0) [0|1] ""  CANOE
 SG_ MePRX_b_SurroundViewCamera : 64|1@1+ (1,0) [0|1] ""  CANOE
 SG_ MePRX_e_AutonomyLvl : 56|8@1+ (1,0) [0|255] ""  CANOE
 SG_ MePRX_e_PAMTunSet : 48|8@1+ (1,0) [0|255] ""  CANOE
 SG_ MePRX_e_MirrorType : 40|8@1+ (1,0) [0|255] ""  CANOE
 SG_ MePRX_e_RadDispType : 32|8@1+ (1,0) [0|255] ""  CANOE
 SG_ MePRX_e_SteerRatRackPinionType : 24|8@1+ (1,0) [0|255] ""  CANOE
 SG_ MePRX_e_Wheelbase : 16|8@1+ (1,0) [0|255] ""  CANOE
 SG_ MePRX_e_VehLineCfg : 8|8@1+ (1,0) [0|255] ""  CANOE
 SG_ MePRX_e_VariantID : 0|8@1+ (1,0) [0|255] ""  CANOE

BO_ 2654552145 HMI_Curr_Displayed_Overlays: 16 CVADAS
 SG_ Frameset1AndTopFrontText_b : 111|1@1+ (1,0) [0|1] ""  CANOE
 SG_ Frameset1AndTopRearText_b : 110|1@1+ (1,0) [0|1] ""  CANOE
 SG_ Frameset2AndFrontCrossText_b : 109|1@1+ (1,0) [0|1] ""  CANOE
 SG_ Frameset2AndRearCrossText_b : 108|1@1+ (1,0) [0|1] ""  CANOE
 SG_ MoreCamsIconFullScreenNoSelect_b : 107|1@1+ (1,0) [0|1] ""  CANOE
 SG_ TopRearButtonNoSelect_b : 106|1@1+ (1,0) [0|1] ""  CANOE
 SG_ TopRearButtonSelect_b : 105|1@1+ (1,0) [0|1] ""  CANOE
 SG_ RearCrossButtonNoSelect_b : 104|1@1+ (1,0) [0|1] ""  CANOE
 SG_ RearCrossButtonSelect_b : 103|1@1+ (1,0) [0|1] ""  CANOE
 SG_ FrontCrossButtonNoSelect_b : 102|1@1+ (1,0) [0|1] ""  CANOE
 SG_ FrontCrossButtonSelect_b : 101|1@1+ (1,0) [0|1] ""  CANOE
 SG_ TopFrontButtonSelect_b : 100|1@1+ (1,0) [0|1] ""  CANOE
 SG_ TopFrontButtonNoSelect_b : 99|1@1+ (1,0) [0|1] ""  CANOE
 SG_ BackupRearCamButtonSelect_b : 98|1@1+ (1,0) [0|1] ""  CANOE
 SG_ BackupRearCamButtonNoSelect_b : 97|1@1+ (1,0) [0|1] ""  CANOE
 SG_ FrontFaceCamButtonSelect_b : 96|1@1+ (1,0) [0|1] ""  CANOE
 SG_ FrontFaceCamButtonNoSelect_b : 95|1@1+ (1,0) [0|1] ""  CANOE
 SG_ FrontTireTracks_b : 94|1@1+ (1,0) [0|1] ""  CANOE
 SG_ AuxCamButton1Select_b : 93|1@1+ (1,0) [0|1] ""  CANOE
 SG_ AuxCamButton1NoSelect_b : 92|1@1+ (1,0) [0|1] ""  CANOE
 SG_ AuxCamButton2Select_b : 91|1@1+ (1,0) [0|1] ""  CANOE
 SG_ AuxCamButton2NoSelect_b : 90|1@1+ (1,0) [0|1] ""  CANOE
 SG_ MoreCamsButton1Select_b : 89|1@1+ (1,0) [0|1] ""  CANOE
 SG_ MoreCamsButton1NoSelect_b : 88|1@1+ (1,0) [0|1] ""  CANOE
 SG_ MoreCamsButton2Select_b : 87|1@1+ (1,0) [0|1] ""  CANOE
 SG_ MoreCamsButton2NoSelect_b : 86|1@1+ (1,0) [0|1] ""  CANOE
 SG_ RearViewDynamics_b : 85|1@1+ (1,0) [0|1] ""  CANOE
 SG_ TopViewRearDynamics_b : 84|1@1+ (1,0) [0|1] ""  CANOE
 SG_ FrontViewDynamics_b : 83|1@1+ (1,0) [0|1] ""  CANOE
 SG_ TopViewFrontDynamics_b : 82|1@1+ (1,0) [0|1] ""  CANOE
 SG_ XIcon_b : 81|1@1+ (1,0) [0|1] ""  CANOE
 SG_ ZoomButtonDisable_b : 80|1@1+ (1,0) [0|1] ""  CANOE
 SG_ ZoomMinusIcon_b : 79|1@1+ (1,0) [0|1] ""  CANOE
 SG_ ZoomPlusIcon_b : 78|1@1+ (1,0) [0|1] ""  CANOE
 SG_ LeftDoorFrontOpen_Icon_b : 77|1@1+ (1,0) [0|1] ""  CANOE
 SG_ LeftDoorRearOpen_Icon_b : 76|1@1+ (1,0) [0|1] ""  CANOE
 SG_ RightDoorFrontOpen_Icon_b : 75|1@1+ (1,0) [0|1] ""  CANOE
 SG_ RightDoorRearOpen_Icon_b : 74|1@1+ (1,0) [0|1] ""  CANOE
 SG_ BackDoorOpen_Icon_b : 73|1@1+ (1,0) [0|1] ""  CANOE
 SG_ FrontCam_NA_b : 72|1@1+ (1,0) [0|1] ""  CANOE
 SG_ LeftCam_NA_b : 71|1@1+ (1,0) [0|1] ""  CANOE
 SG_ BackCam_NA_b : 70|1@1+ (1,0) [0|1] ""  CANOE
 SG_ RightCam_NA_b : 69|1@1+ (1,0) [0|1] ""  CANOE
 SG_ TopViewBlack_b : 68|1@1+ (1,0) [0|1] ""  CANOE
 SG_ LeftDoorFrontClose_Icon_b : 67|1@1+ (1,0) [0|1] ""  CANOE
 SG_ LeftDoorRearClose_Icon_b : 66|1@1+ (1,0) [0|1] ""  CANOE
 SG_ RightDoorFrontClose_Icon_b : 65|1@1+ (1,0) [0|1] ""  CANOE
 SG_ RightDoorRearClose_Icon_b : 64|1@1+ (1,0) [0|1] ""  CANOE
 SG_ Reserved13_b : 63|1@1+ (1,0) [0|1] ""  CANOE
 SG_ PDC_RearCenter_Yellow_b : 62|1@1+ (1,0) [0|1] ""  CANOE
 SG_ PDC_RearCenter_Red_b : 61|1@1+ (1,0) [0|1] ""  CANOE
 SG_ Reserved12_b : 60|1@1+ (1,0) [0|1] ""  CANOE
 SG_ PDC_RearRight_Yellow_b : 59|1@1+ (1,0) [0|1] ""  CANOE
 SG_ PDC_RearRight_Red_b : 58|1@1+ (1,0) [0|1] ""  CANOE
 SG_ Reserved11_b : 57|1@1+ (1,0) [0|1] ""  CANOE
 SG_ PDC_FrontLeft_Yellow_b : 56|1@1+ (1,0) [0|1] ""  CANOE
 SG_ PDC_FrontLeft_Red_b : 55|1@1+ (1,0) [0|1] ""  CANOE
 SG_ Reserved10_b : 54|1@1+ (1,0) [0|1] ""  CANOE
 SG_ PDC_FrontCenter_Yellow_b : 53|1@1+ (1,0) [0|1] ""  CANOE
 SG_ PDC_FrontCenter_Red_b : 52|1@1+ (1,0) [0|1] ""  CANOE
 SG_ Reserved09_b : 51|1@1+ (1,0) [0|1] ""  CANOE
 SG_ PDC_FrontRight_Yellow_b : 50|1@1+ (1,0) [0|1] ""  CANOE
 SG_ PDC_FrontRight_Red_b : 49|1@1+ (1,0) [0|1] ""  CANOE
 SG_ Reserved08_b : 48|1@1+ (1,0) [0|1] ""  CANOE
 SG_ PDC_RearLeft_Yellow_b : 47|1@1+ (1,0) [0|1] ""  CANOE
 SG_ PDC_RearLeft_Red_b : 46|1@1+ (1,0) [0|1] ""  CANOE
 SG_ SrvLayout_b : 45|1@1+ (1,0) [0|1] ""  CANOE
 SG_ SrvStAngIndOk_b : 44|1@1+ (1,0) [0|1] ""  CANOE
 SG_ SrvStAngIndNok_b : 43|1@1+ (1,0) [0|1] ""  CANOE
 SG_ SrvSpOmIndOk_b : 42|1@1+ (1,0) [0|1] ""  CANOE
 SG_ SrvSpOmIndNok_b : 41|1@1+ (1,0) [0|1] ""  CANOE
 SG_ SrvChkIndRun_b : 40|1@1+ (1,0) [0|1] ""  CANOE
 SG_ SrvChkIndOk_b : 39|1@1+ (1,0) [0|1] ""  CANOE
 SG_ SrvChkIndNok_b : 38|1@1+ (1,0) [0|1] ""  CANOE
 SG_ SrvChkIndCondNok_b : 37|1@1+ (1,0) [0|1] ""  CANOE
 SG_ SrvCamIndFrOk_b : 36|1@1+ (1,0) [0|1] ""  CANOE
 SG_ SrvCamIndFrNok_b : 35|1@1+ (1,0) [0|1] ""  CANOE
 SG_ SrvCamIndFrPend_b : 34|1@1+ (1,0) [0|1] ""  CANOE
 SG_ SrvCamIndFrNone_b : 33|1@1+ (1,0) [0|1] ""  CANOE
 SG_ SrvCamIndLeOk_b : 32|1@1+ (1,0) [0|1] ""  CANOE
 SG_ SrvCamIndLeNok_b : 31|1@1+ (1,0) [0|1] ""  CANOE
 SG_ SrvCamIndLePend_b : 30|1@1+ (1,0) [0|1] ""  CANOE
 SG_ SrvCamIndLeNone_b : 29|1@1+ (1,0) [0|1] ""  CANOE
 SG_ SrvCamIndBaOk_b : 28|1@1+ (1,0) [0|1] ""  CANOE
 SG_ SrvCamIndBaNok_b : 27|1@1+ (1,0) [0|1] ""  CANOE
 SG_ SrvCamIndBaPend_b : 26|1@1+ (1,0) [0|1] ""  CANOE
 SG_ SrvCamIndBaNone_b : 25|1@1+ (1,0) [0|1] ""  CANOE
 SG_ SrvCamIndRiOk_b : 24|1@1+ (1,0) [0|1] ""  CANOE
 SG_ SrvCamIndRiNok_b : 23|1@1+ (1,0) [0|1] ""  CANOE
 SG_ SrvCamIndRiPend_b : 22|1@1+ (1,0) [0|1] ""  CANOE
 SG_ SrvCamIndRiNone_b : 21|1@1+ (1,0) [0|1] ""  CANOE
 SG_ SrvPrgBar0Per_b : 20|1@1+ (1,0) [0|1] ""  CANOE
 SG_ SrvPrgBar20Per_b : 19|1@1+ (1,0) [0|1] ""  CANOE
 SG_ SrvPrgBar40Per_b : 18|1@1+ (1,0) [0|1] ""  CANOE
 SG_ SrvPrgBar60Per_b : 17|1@1+ (1,0) [0|1] ""  CANOE
 SG_ SrvPrgBar80Per_b : 16|1@1+ (1,0) [0|1] ""  CANOE
 SG_ SrvPrgBar100Per_b : 15|1@1+ (1,0) [0|1] ""  CANOE
 SG_ TrscOvl : 14|1@1+ (1,0) [0|1] ""  CANOE
 SG_ TrscJackKnifeOrange : 13|1@1+ (1,0) [0|1] ""  CANOE
 SG_ TrscJackKnifeRed : 12|1@1+ (1,0) [0|1] ""  CANOE
 SG_ TrscTrailerRed : 11|1@1+ (1,0) [0|1] ""  CANOE
 SG_ THATriangleOverlay : 10|1@1+ (1,0) [0|1] ""  CANOE
 SG_ THACouplerBulletIcon : 9|1@1+ (1,0) [0|1] ""  CANOE
 SG_ THAButtonGrey : 8|1@1+ (1,0) [0|1] ""  CANOE
 SG_ THAButtonSelectable : 7|1@1+ (1,0) [0|1] ""  CANOE
 SG_ THAConfirmButton : 6|1@1+ (1,0) [0|1] ""  CANOE
 SG_ THAStartButton : 5|1@1+ (1,0) [0|1] ""  CANOE
 SG_ THAProgressBar : 4|1@1+ (1,0) [0|1] ""  CANOE
 SG_ Reserved3_b : 3|1@1+ (1,0) [0|1] ""  CANOE
 SG_ Reserved2_b : 2|1@1+ (1,0) [0|1] ""  CANOE
 SG_ Reserved1_b : 1|1@1+ (1,0) [0|1] ""  CANOE
 SG_ Reserved0_b : 0|1@1+ (1,0) [0|1] ""  CANOE

BO_ 2654552144 HMI_Curr_Requested_Overlays: 16 CVADAS
 SG_ Frameset1AndTopFrontText_b : 111|1@1+ (1,0) [0|1] ""  CANOE
 SG_ Frameset1AndTopRearText_b : 110|1@1+ (1,0) [0|1] ""  CANOE
 SG_ Frameset2AndFrontCrossText_b : 109|1@1+ (1,0) [0|1] ""  CANOE
 SG_ Frameset2AndRearCrossText_b : 108|1@1+ (1,0) [0|1] ""  CANOE
 SG_ MoreCamsIconFullScreenNoSelect_b : 107|1@1+ (1,0) [0|1] ""  CANOE
 SG_ TopRearButtonNoSelect_b : 106|1@1+ (1,0) [0|1] ""  CANOE
 SG_ TopRearButtonSelect_b : 105|1@1+ (1,0) [0|1] ""  CANOE
 SG_ RearCrossButtonNoSelect_b : 104|1@1+ (1,0) [0|1] ""  CANOE
 SG_ RearCrossButtonSelect_b : 103|1@1+ (1,0) [0|1] ""  CANOE
 SG_ FrontCrossButtonNoSelect_b : 102|1@1+ (1,0) [0|1] ""  CANOE
 SG_ FrontCrossButtonSelect_b : 101|1@1+ (1,0) [0|1] ""  CANOE
 SG_ TopFrontButtonSelect_b : 100|1@1+ (1,0) [0|1] ""  CANOE
 SG_ TopFrontButtonNoSelect_b : 99|1@1+ (1,0) [0|1] ""  CANOE
 SG_ BackupRearCamButtonSelect_b : 98|1@1+ (1,0) [0|1] ""  CANOE
 SG_ BackupRearCamButtonNoSelect_b : 97|1@1+ (1,0) [0|1] ""  CANOE
 SG_ FrontFaceCamButtonSelect_b : 96|1@1+ (1,0) [0|1] ""  CANOE
 SG_ FrontFaceCamButtonNoSelect_b : 95|1@1+ (1,0) [0|1] ""  CANOE
 SG_ FrontTireTracks_b : 94|1@1+ (1,0) [0|1] ""  CANOE
 SG_ AuxCamButton1Select_b : 93|1@1+ (1,0) [0|1] ""  CANOE
 SG_ AuxCamButton1NoSelect_b : 92|1@1+ (1,0) [0|1] ""  CANOE
 SG_ AuxCamButton2Select_b : 91|1@1+ (1,0) [0|1] ""  CANOE
 SG_ AuxCamButton2NoSelect_b : 90|1@1+ (1,0) [0|1] ""  CANOE
 SG_ MoreCamsButton1Select_b : 89|1@1+ (1,0) [0|1] ""  CANOE
 SG_ MoreCamsButton1NoSelect_b : 88|1@1+ (1,0) [0|1] ""  CANOE
 SG_ MoreCamsButton2Select_b : 87|1@1+ (1,0) [0|1] ""  CANOE
 SG_ MoreCamsButton2NoSelect_b : 86|1@1+ (1,0) [0|1] ""  CANOE
 SG_ RearViewDynamics_b : 85|1@1+ (1,0) [0|1] ""  CANOE
 SG_ TopViewRearDynamics_b : 84|1@1+ (1,0) [0|1] ""  CANOE
 SG_ FrontViewDynamics_b : 83|1@1+ (1,0) [0|1] ""  CANOE
 SG_ TopViewFrontDynamics_b : 82|1@1+ (1,0) [0|1] ""  CANOE
 SG_ XIcon_b : 81|1@1+ (1,0) [0|1] ""  CANOE
 SG_ ZoomButtonDisable_b : 80|1@1+ (1,0) [0|1] ""  CANOE
 SG_ ZoomMinusIcon_b : 79|1@1+ (1,0) [0|1] ""  CANOE
 SG_ ZoomPlusIcon_b : 78|1@1+ (1,0) [0|1] ""  CANOE
 SG_ LeftDoorFrontOpen_Icon_b : 77|1@1+ (1,0) [0|1] ""  CANOE
 SG_ LeftDoorRearOpen_Icon_b : 76|1@1+ (1,0) [0|1] ""  CANOE
 SG_ RightDoorFrontOpen_Icon_b : 75|1@1+ (1,0) [0|1] ""  CANOE
 SG_ RightDoorRearOpen_Icon_b : 74|1@1+ (1,0) [0|1] ""  CANOE
 SG_ BackDoorOpen_Icon_b : 73|1@1+ (1,0) [0|1] ""  CANOE
 SG_ FrontCam_NA_b : 72|1@1+ (1,0) [0|1] ""  CANOE
 SG_ LeftCam_NA_b : 71|1@1+ (1,0) [0|1] ""  CANOE
 SG_ BackCam_NA_b : 70|1@1+ (1,0) [0|1] ""  CANOE
 SG_ RightCam_NA_b : 69|1@1+ (1,0) [0|1] ""  CANOE
 SG_ TopViewBlack_b : 68|1@1+ (1,0) [0|1] ""  CANOE
 SG_ LeftDoorFrontClose_Icon_b : 67|1@1+ (1,0) [0|1] ""  CANOE
 SG_ LeftDoorRearClose_Icon_b : 66|1@1+ (1,0) [0|1] ""  CANOE
 SG_ RightDoorFrontClose_Icon_b : 65|1@1+ (1,0) [0|1] ""  CANOE
 SG_ RightDoorRearClose_Icon_b : 64|1@1+ (1,0) [0|1] ""  CANOE
 SG_ Reserved13_b : 63|1@1+ (1,0) [0|1] ""  CANOE
 SG_ PDC_RearCenter_Yellow_b : 62|1@1+ (1,0) [0|1] ""  CANOE
 SG_ PDC_RearCenter_Red_b : 61|1@1+ (1,0) [0|1] ""  CANOE
 SG_ Reserved12_b : 60|1@1+ (1,0) [0|1] ""  CANOE
 SG_ PDC_RearRight_Yellow_b : 59|1@1+ (1,0) [0|1] ""  CANOE
 SG_ PDC_RearRight_Red_b : 58|1@1+ (1,0) [0|1] ""  CANOE
 SG_ Reserved11_b : 57|1@1+ (1,0) [0|1] ""  CANOE
 SG_ PDC_FrontLeft_Yellow_b : 56|1@1+ (1,0) [0|1] ""  CANOE
 SG_ PDC_FrontLeft_Red_b : 55|1@1+ (1,0) [0|1] ""  CANOE
 SG_ Reserved10_b : 54|1@1+ (1,0) [0|1] ""  CANOE
 SG_ PDC_FrontCenter_Yellow_b : 53|1@1+ (1,0) [0|1] ""  CANOE
 SG_ PDC_FrontCenter_Red_b : 52|1@1+ (1,0) [0|1] ""  CANOE
 SG_ Reserved09_b : 51|1@1+ (1,0) [0|1] ""  CANOE
 SG_ PDC_FrontRight_Yellow_b : 50|1@1+ (1,0) [0|1] ""  CANOE
 SG_ PDC_FrontRight_Red_b : 49|1@1+ (1,0) [0|1] ""  CANOE
 SG_ Reserved08_b : 48|1@1+ (1,0) [0|1] ""  CANOE
 SG_ PDC_RearLeft_Yellow_b : 47|1@1+ (1,0) [0|1] ""  CANOE
 SG_ PDC_RearLeft_Red_b : 46|1@1+ (1,0) [0|1] ""  CANOE
 SG_ SrvLayout_b : 45|1@1+ (1,0) [0|1] ""  CANOE
 SG_ SrvStAngIndOk_b : 44|1@1+ (1,0) [0|1] ""  CANOE
 SG_ SrvStAngIndNok_b : 43|1@1+ (1,0) [0|1] ""  CANOE
 SG_ SrvSpOmIndOk_b : 42|1@1+ (1,0) [0|1] ""  CANOE
 SG_ SrvSpOmIndNok_b : 41|1@1+ (1,0) [0|1] ""  CANOE
 SG_ SrvChkIndRun_b : 40|1@1+ (1,0) [0|1] ""  CANOE
 SG_ SrvChkIndOk_b : 39|1@1+ (1,0) [0|1] ""  CANOE
 SG_ SrvChkIndNok_b : 38|1@1+ (1,0) [0|1] ""  CANOE
 SG_ SrvChkIndCondNok_b : 37|1@1+ (1,0) [0|1] ""  CANOE
 SG_ SrvCamIndFrOk_b : 36|1@1+ (1,0) [0|1] ""  CANOE
 SG_ SrvCamIndFrNok_b : 35|1@1+ (1,0) [0|1] ""  CANOE
 SG_ SrvCamIndFrPend_b : 34|1@1+ (1,0) [0|1] ""  CANOE
 SG_ SrvCamIndFrNone_b : 33|1@1+ (1,0) [0|1] ""  CANOE
 SG_ SrvCamIndLeOk_b : 32|1@1+ (1,0) [0|1] ""  CANOE
 SG_ SrvCamIndLeNok_b : 31|1@1+ (1,0) [0|1] ""  CANOE
 SG_ SrvCamIndLePend_b : 30|1@1+ (1,0) [0|1] ""  CANOE
 SG_ SrvCamIndLeNone_b : 29|1@1+ (1,0) [0|1] ""  CANOE
 SG_ SrvCamIndBaOk_b : 28|1@1+ (1,0) [0|1] ""  CANOE
 SG_ SrvCamIndBaNok_b : 27|1@1+ (1,0) [0|1] ""  CANOE
 SG_ SrvCamIndBaPend_b : 26|1@1+ (1,0) [0|1] ""  CANOE
 SG_ SrvCamIndBaNone_b : 25|1@1+ (1,0) [0|1] ""  CANOE
 SG_ SrvCamIndRiOk_b : 24|1@1+ (1,0) [0|1] ""  CANOE
 SG_ SrvCamIndRiNok_b : 23|1@1+ (1,0) [0|1] ""  CANOE
 SG_ SrvCamIndRiPend_b : 22|1@1+ (1,0) [0|1] ""  CANOE
 SG_ SrvCamIndRiNone_b : 21|1@1+ (1,0) [0|1] ""  CANOE
 SG_ SrvPrgBar0Per_b : 20|1@1+ (1,0) [0|1] ""  CANOE
 SG_ SrvPrgBar20Per_b : 19|1@1+ (1,0) [0|1] ""  CANOE
 SG_ SrvPrgBar40Per_b : 18|1@1+ (1,0) [0|1] ""  CANOE
 SG_ SrvPrgBar60Per_b : 17|1@1+ (1,0) [0|1] ""  CANOE
 SG_ SrvPrgBar80Per_b : 16|1@1+ (1,0) [0|1] ""  CANOE
 SG_ SrvPrgBar100Per_b : 15|1@1+ (1,0) [0|1] ""  CANOE
 SG_ TrscOvl : 14|1@1+ (1,0) [0|1] ""  CANOE
 SG_ TrscJackKnifeOrange : 13|1@1+ (1,0) [0|1] ""  CANOE
 SG_ TrscJackKnifeRed : 12|1@1+ (1,0) [0|1] ""  CANOE
 SG_ TrscTrailerRed : 11|1@1+ (1,0) [0|1] ""  CANOE
 SG_ THATriangleOverlay : 10|1@1+ (1,0) [0|1] ""  CANOE
 SG_ THACouplerBulletIcon : 9|1@1+ (1,0) [0|1] ""  CANOE
 SG_ THAButtonGrey : 8|1@1+ (1,0) [0|1] ""  CANOE
 SG_ THAButtonSelectable : 7|1@1+ (1,0) [0|1] ""  CANOE
 SG_ THAConfirmButton : 6|1@1+ (1,0) [0|1] ""  CANOE
 SG_ THAStartButton : 5|1@1+ (1,0) [0|1] ""  CANOE
 SG_ THAProgressBar : 4|1@1+ (1,0) [0|1] ""  CANOE
 SG_ Reserved3_b : 3|1@1+ (1,0) [0|1] ""  CANOE
 SG_ Reserved2_b : 2|1@1+ (1,0) [0|1] ""  CANOE
 SG_ Reserved1_b : 1|1@1+ (1,0) [0|1] ""  CANOE
 SG_ Reserved0_b : 0|1@1+ (1,0) [0|1] ""  CANOE

BO_ 2654814240 ME_DebugMsgUnsigned: 8 CVADAS
 SG_ Debug_Signal_6 : 16|16@1+ (1,0) [0|0] ""  CANOE
 SG_ Debug_Signal_8 : 48|16@1+ (1,0) [0|0] ""  CANOE
 SG_ Debug_Signal_7 : 32|16@1+ (1,0) [0|0] ""  CANOE
 SG_ Debug_Signal_5 : 0|16@1+ (1,0) [0|0] ""  CANOE

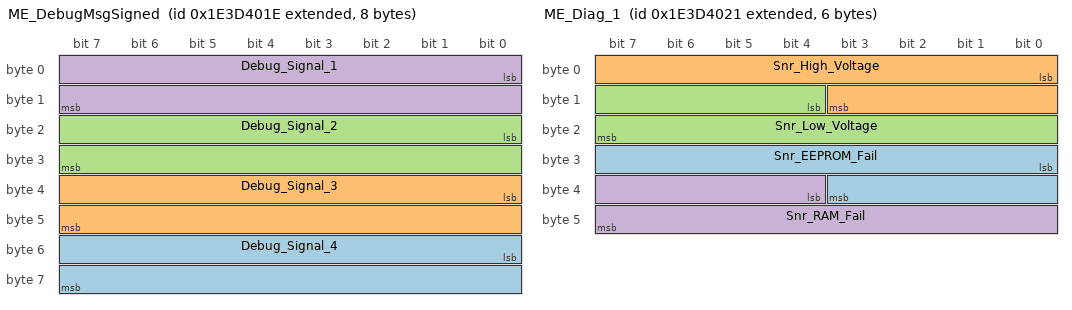
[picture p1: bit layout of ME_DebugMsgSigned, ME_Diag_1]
BO_ 2654814238 ME_DebugMsgSigned: 8 CVADAS
 SG_ Debug_Signal_4 : 48|16@1- (1,0) [0|0] ""  CANOE
 SG_ Debug_Signal_3 : 32|16@1- (1,0) [0|0] ""  CANOE
 SG_ Debug_Signal_2 : 16|16@1- (1,0) [0|0] ""  CANOE
 SG_ Debug_Signal_1 : 0|16@1- (1,0) [0|0] ""  CANOE

BO_ 2654814241 ME_Diag_1: 6 CVADAS
 SG_ Snr_EEPROM_Fail : 24|12@1+ (1,0) [0|0] ""  CANOE
 SG_ Snr_High_Voltage : 0|12@1+ (1,0) [0|0] ""  CANOE
 SG_ Snr_Low_Voltage : 12|12@1+ (1,0) [0|0] ""  CANOE
 SG_ Snr_RAM_Fail : 36|12@1+ (1,0) [0|0] ""  CANOE

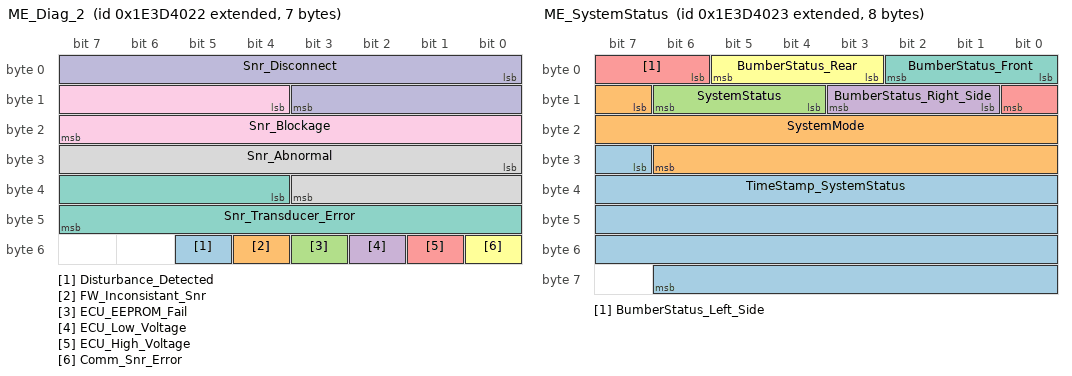
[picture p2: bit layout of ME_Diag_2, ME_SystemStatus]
BO_ 2654814242 ME_Diag_2: 7 CVADAS
 SG_ Disturbance_Detected : 53|1@1+ (1,0) [0|1] ""  CANOE
 SG_ FW_Inconsistant_Snr : 52|1@1+ (1,0) [0|1] ""  CANOE
 SG_ ECU_EEPROM_Fail : 51|1@1+ (1,0) [0|1] ""  CANOE
 SG_ ECU_Low_Voltage : 50|1@1+ (1,0) [0|1] ""  CANOE
 SG_ ECU_High_Voltage : 49|1@1+ (1,0) [0|1] ""  CANOE
 SG_ Comm_Snr_Error : 48|1@1+ (1,0) [0|1] ""  CANOE
 SG_ Snr_Transducer_Error : 36|12@1+ (1,0) [0|4095] ""  CANOE
 SG_ Snr_Abnormal : 24|12@1+ (1,0) [0|4095] ""  CANOE
 SG_ Snr_Blockage : 12|12@1+ (1,0) [0|4095] ""  CANOE
 SG_ Snr_Disconnect : 0|12@1+ (1,0) [0|4095] ""  CANOE

BO_ 2654814243 ME_SystemStatus: 8 CVADAS
 SG_ TimeStamp_SystemStatus : 31|32@1+ (1,0) [0|4294967295] "ms"  CANOE
 SG_ SystemMode : 15|16@1+ (1,0) [0|65535] ""  CANOE
 SG_ SystemStatus : 12|3@1+ (1,0) [0|7] ""  CANOE
 SG_ BumberStatus_Right_Side : 9|3@1+ (1,0) [0|7] ""  CANOE
 SG_ BumberStatus_Left_Side : 6|3@1+ (1,0) [0|7] ""  CANOE
 SG_ BumberStatus_Rear : 3|3@1+ (1,0) [0|7] ""  CANOE
 SG_ BumberStatus_Front : 0|3@1+ (1,0) [0|7] ""  CANOE

BO_ 2654552136 SetUSSParkingMode: 1 CANOE
 SG_ UssParkingModeSignal : 0|8@1+ (1,0) [0|0] ""  CVADAS

BO_ 2654814246 ME_Tester_SensorData_2: 8 CVADAS
 SG_ Tstr_SD_0_SystemStatus_Msg2 m0 : 8|56@1+ (1,0) [0|255] ""  CANOE
 SG_ Tstr_SD_1_SensorBlkgClrCounter m1 : 48|8@1+ (1,0) [0|255] ""  CANOE
 SG_ Tstr_SD_2_SensorBlkgClrCounter m2 : 48|8@1+ (1,0) [0|255] ""  CANOE
 SG_ Tstr_SD_3_SensorBlkgClrCounter m3 : 48|8@1+ (1,0) [0|255] ""  CANOE
 SG_ Tstr_SD_4_SensorBlkgClrCounter m4 : 48|8@1+ (1,0) [0|255] ""  CANOE
 SG_ Tstr_SD_5_SensorBlkgClrCounter m5 : 48|8@1+ (1,0) [0|255] ""  CANOE
 SG_ Tstr_SD_6_SensorBlkgClrCounter m6 : 48|8@1+ (1,0) [0|255] ""  CANOE
 SG_ Tstr_SD_7_SensorBlkgClrCounter m7 : 48|8@1+ (1,0) [0|255] ""  CANOE
 SG_ Tstr_SD_8_SensorBlkgClrCounter m8 : 48|8@1+ (1,0) [0|255] ""  CANOE
 SG_ Tstr_SD_9_SensorBlkgClrCounter m9 : 48|8@1+ (1,0) [0|255] ""  CANOE
 SG_ Tstr_SD_10_SensorBlkgClrCounter m10 : 48|8@1+ (1,0) [0|255] ""  CANOE
 SG_ Tstr_SD_11_SensorBlkgClrCounter m11 : 48|8@1+ (1,0) [0|255] ""  CANOE
 SG_ Tstr_SD_12_SensorBlkgClrCounter m12 : 48|8@1+ (1,0) [0|255] ""  CANOE
 SG_ Tstr_SD_13_SensorBlkgClrCounter m13 : 48|8@1+ (1,0) [0|255] ""  CANOE
 SG_ Tstr_SD_14_SensorBlkgClrCounter m14 : 48|8@1+ (1,0) [0|255] ""  CANOE
 SG_ Tstr_SD_15_SensorBlkgClrCounter m15 : 48|8@1+ (1,0) [0|255] ""  CANOE
 SG_ Tstr_SD_16_SensorBlkgClrCounter m16 : 48|8@1+ (1,0) [0|255] ""  CANOE
 SG_ Tstr_SD_1_SensorBlkgSetCounter m1 : 40|8@1+ (1,0) [0|255] ""  CANOE
 SG_ Tstr_SD_2_SensorBlkgSetCounter m2 : 40|8@1+ (1,0) [0|255] ""  CANOE
 SG_ Tstr_SD_3_SensorBlkgSetCounter m3 : 40|8@1+ (1,0) [0|255] ""  CANOE
 SG_ Tstr_SD_4_SensorBlkgSetCounter m4 : 40|8@1+ (1,0) [0|255] ""  CANOE
 SG_ Tstr_SD_5_SensorBlkgSetCounter m5 : 40|8@1+ (1,0) [0|255] ""  CANOE
 SG_ Tstr_SD_6_SensorBlkgSetCounter m6 : 40|8@1+ (1,0) [0|255] ""  CANOE
 SG_ Tstr_SD_7_SensorBlkgSetCounter m7 : 40|8@1+ (1,0) [0|255] ""  CANOE
 SG_ Tstr_SD_8_SensorBlkgSetCounter m8 : 40|8@1+ (1,0) [0|255] ""  CANOE
 SG_ Tstr_SD_9_SensorBlkgSetCounter m9 : 40|8@1+ (1,0) [0|255] ""  CANOE
 SG_ Tstr_SD_10_SensorBlkgSetCounter m10 : 40|8@1+ (1,0) [0|255] ""  CANOE
 SG_ Tstr_SD_11_SensorBlkgSetCounter m11 : 40|8@1+ (1,0) [0|255] ""  CANOE
 SG_ Tstr_SD_12_SensorBlkgSetCounter m12 : 40|8@1+ (1,0) [0|255] ""  CANOE
 SG_ Tstr_SD_13_SensorBlkgSetCounter m13 : 40|8@1+ (1,0) [0|255] ""  CANOE
 SG_ Tstr_SD_14_SensorBlkgSetCounter m14 : 40|8@1+ (1,0) [0|255] ""  CANOE
 SG_ Tstr_SD_15_SensorBlkgSetCounter m15 : 40|8@1+ (1,0) [0|255] ""  CANOE
 SG_ Tstr_SD_16_SensorBlkgSetCounter m16 : 40|8@1+ (1,0) [0|255] ""  CANOE
 SG_ Tstr_SD_16_SensorID m16 : 8|16@1+ (1,0) [0|65535] ""  CANOE
 SG_ Tstr_SD_15_SensorID m15 : 8|16@1+ (1,0) [0|65535] ""  CANOE
 SG_ Tstr_SD_14_SensorID m14 : 8|16@1+ (1,0) [0|65535] ""  CANOE
 SG_ Tstr_SD_13_SensorID m13 : 8|16@1+ (1,0) [0|65535] ""  CANOE
 SG_ Tstr_SD_1_SensorID m1 : 8|16@1+ (1,0) [0|65535] ""  CANOE
 SG_ Tstr_SD_2_SensorID m2 : 8|16@1+ (1,0) [0|65535] ""  CANOE
 SG_ Tstr_SD_3_SensorID m3 : 8|16@1+ (1,0) [0|65535] ""  CANOE
 SG_ Tstr_SD_4_SensorID m4 : 8|16@1+ (1,0) [0|65535] ""  CANOE
 SG_ Tstr_SD_5_SensorID m5 : 8|16@1+ (1,0) [0|65535] ""  CANOE
 SG_ Tstr_SD_6_SensorID m6 : 8|16@1+ (1,0) [0|65535] ""  CANOE
 SG_ Tstr_SD_7_SensorID m7 : 8|16@1+ (1,0) [0|65535] ""  CANOE
 SG_ Tstr_SD_8_SensorID m8 : 8|16@1+ (1,0) [0|65535] ""  CANOE
 SG_ Tstr_SD_9_SensorID m9 : 8|16@1+ (1,0) [0|65535] ""  CANOE
 SG_ Tstr_SD_10_SensorID m10 : 8|16@1+ (1,0) [0|65535] ""  CANOE
 SG_ Tstr_SD_11_SensorID m11 : 8|16@1+ (1,0) [0|65535] ""  CANOE
 SG_ Tstr_SD_12_SensorID m12 : 8|16@1+ (1,0) [0|65535] ""  CANOE
 SG_ Tstr_SD_16_SensorTemperature m16 : 24|16@1- (0.1,0) [-3276.8|3276.7] "C"  CANOE
 SG_ Tstr_SD_15_SensorTemperature m15 : 24|16@1- (0.1,0) [-3276.8|3276.7] "C"  CANOE
 SG_ Tstr_SD_14_SensorTemperature m14 : 24|16@1- (0.1,0) [-3276.8|3276.7] "C"  CANOE
 SG_ Tstr_SD_13_SensorTemperature m13 : 24|16@1- (0.1,0) [-3276.8|3276.7] "C"  CANOE
 SG_ Tstr_SD_7_SensorTemperature m7 : 24|16@1- (0.1,0) [-3276.8|3276.7] "C"  CANOE
 SG_ Tstr_SD_1_SensorTemperature m1 : 24|16@1- (0.1,0) [-3276.8|3276.7] "C"  CANOE
 SG_ Tstr_SD_2_SensorTemperature m2 : 24|16@1- (0.1,0) [-3276.8|3276.7] "C"  CANOE
 SG_ Tstr_SD_3_SensorTemperature m3 : 24|16@1- (0.1,0) [-3276.8|3276.7] "C"  CANOE
 SG_ Tstr_SD_4_SensorTemperature m4 : 24|16@1- (0.1,0) [-3276.8|3276.7] "C"  CANOE
 SG_ Tstr_SD_5_SensorTemperature m5 : 24|16@1- (0.1,0) [-3276.8|3276.7] "C"  CANOE
 SG_ Tstr_SD_6_SensorTemperature m6 : 24|16@1- (0.1,0) [-3276.8|3276.7] "C"  CANOE
 SG_ Tstr_SD_8_SensorTemperature m8 : 24|16@1- (0.1,0) [-3276.8|3276.7] "C"  CANOE
 SG_ Tstr_SD_9_SensorTemperature m9 : 24|16@1- (0.1,0) [-3276.8|3276.7] "C"  CANOE
 SG_ Tstr_SD_10_SensorTemperature m10 : 24|16@1- (0.1,0) [-3276.8|3276.7] "C"  CANOE
 SG_ Tstr_SD_11_SensorTemperature m11 : 24|16@1- (0.1,0) [-3276.8|3276.7] "C"  CANOE
 SG_ Tstr_SD_12_SensorTemperature m12 : 24|16@1- (0.1,0) [-3276.8|3276.7] "C"  CANOE
 SG_ Tstr_SD_DataIndex_Msg2 M : 0|8@1+ (1,0) [0|255] ""  CANOE

CM_ SG_ 2654552193 cntrCvpamFdData1_u16 "To analyze distance between ego vehicle(front axle) and detected vehicle";
CM_ SG_ 2654552193 crcCvpamFdData1_u8 "To analyze distance between ego vehicle(front axle) and detected vehicle";
CM_ SG_ 2654552193 msgcntrCvpamFdData1_u8 "To analyze distance between ego vehicle(front axle) and detected vehicle";
CM_ SG_ 2654552193 macCvpamFdData1_u64 "To analyze distance between ego vehicle(front axle) and detected vehicle";
CM_ SG_ 2654552193 obj_Pos_Longi "To analyze distance between ego vehicle(front axle) and detected vehicle";
CM_ SG_ 2654552193 obj_Pos_Lat "To analyze angle between ego vehicle(front axle) and detected vehicle";
CM_ SG_ 2654552168 m_QM_FID_TRSC_ASCMDef "FID TRSC ASCMDef";
CM_ SG_ 2654552168 m_QM_FID_TRSC_LIMITED_DefView "FID TRSC Limited DefView";
CM_ SG_ 2654552168 m_QM_FID_TRSC_CAM_CAL_ABORT "FID TRSC Camera Calibration Abort";
CM_ SG_ 2654552168 m_QM_FID_TRSC_LIMITED_View "FID TRSC Limited View";
CM_ SG_ 2654552168 m_QM_FID_TRSC_DISABLED "FID TRSC Disabled";
CM_ SG_ 2654552151 IeTRSC_pct_TrlrTrackConf "DID value of Trailer tracking confidence";
BA_DEF_ SG_  "GenSigStartValue" INT 0 2147483647;
BA_DEF_ SG_  "GenSigInactiveValue" INT 0 2147483647;
BA_DEF_ SG_  "GenSigSendType" ENUM  "NotUsed","OnWrite","OnWriteWithRepetition","OnChange","OnChangeWithRepetition","IfActive","IfActiveWithRepetition","NoSigSendType";
BA_DEF_ SG_  "GenSigTimeoutTime_BSM" INT 0 65535;
BA_DEF_ SG_  "GenSigTimeoutTime_BSM2" INT 0 65535;
BA_DEF_ SG_  "GenSigTimeoutTime_CADM" INT 0 65535;
BA_DEF_ SG_  "GenSigTimeoutTime_CVADAS" INT 0 65535;
BA_DEF_ SG_  "GenSigTimeoutTime_ECM" INT 0 65535;
BA_DEF_ SG_  "GenSigTimeoutTime_EPS" INT 0 65535;
BA_DEF_ SG_  "GenSigTimeoutTime_EVCU2" INT 0 65535;
BA_DEF_ SG_  "GenSigTimeoutTime_ORC" INT 0 65535;
BA_DEF_ BO_  "DiagRequest" ENUM  "No","Yes";
BA_DEF_ BO_  "Type" ENUM  "P","C","PE","COC","PE_Cntrl","E","E_Cntrl","OC","S","BAF","DC","EM","MM","ISO-TP","-";
BA_DEF_ BO_  "DiagResponse" ENUM  "No","Yes";
BA_DEF_ BO_  "NmMessage" ENUM  "No","Yes";
BA_DEF_ BO_  "GenMsgSendType" ENUM  "Cyclic","NotUsed","NotUsed","NotUsed","NotUsed","NotUsed","NotUsed","NotUsed","NoMsgSendType";
BA_DEF_ BO_  "GenMsgNrOfRepetition" INT 0 255;
BA_DEF_ BO_  "GenMsgILSupport" ENUM  "No","Yes";
BA_DEF_ BO_  "GenMsgCycleTimeFast" INT 0 65535;
BA_DEF_ BO_  "GenMsgCycleTime" INT 0 65535;
BA_DEF_ BO_  "GenMsgDelayTime" INT 0 65535;
BA_DEF_ BO_  "NmAsrMessage" ENUM  "No","Yes";
BA_DEF_ BO_  "DiagState" ENUM  "No","Yes";
BA_DEF_ BO_  "DiagConnection" HEX 0 65535;
BA_DEF_ BO_  "VFrameFormat" ENUM  "StandardCAN","ExtendedCAN","reserved","reserved","reserved","reserved","reserved","reserved","reserved","reserved","reserved","reserved","reserved","reserved","StandardCAN_FD","ExtendedCAN_FD";
BA_DEF_ BO_  "CANFD_BRS" INT 0 1;
BA_DEF_DEF_  "GenSigStartValue" 0;
BA_DEF_DEF_  "GenSigInactiveValue" 0;
BA_DEF_DEF_  "GenSigSendType" "NoSigSendType";
BA_DEF_DEF_  "GenSigTimeoutTime_BSM" 2500;
BA_DEF_DEF_  "GenSigTimeoutTime_BSM2" 2500;
BA_DEF_DEF_  "GenSigTimeoutTime_CADM" 2500;
BA_DEF_DEF_  "GenSigTimeoutTime_CVADAS" 2500;
BA_DEF_DEF_  "GenSigTimeoutTime_ECM" 2500;
BA_DEF_DEF_  "GenSigTimeoutTime_EPS" 2500;
BA_DEF_DEF_  "GenSigTimeoutTime_EVCU2" 2500;
BA_DEF_DEF_  "GenSigTimeoutTime_ORC" 2500;
BA_DEF_DEF_  "DiagRequest" "No";
BA_DEF_DEF_  "Type" "-";
BA_DEF_DEF_  "DiagResponse" "No";
BA_DEF_DEF_  "NmMessage" "No";
BA_DEF_DEF_  "GenMsgSendType" "NoMsgSendType";
BA_DEF_DEF_  "GenMsgNrOfRepetition" 0;
BA_DEF_DEF_  "GenMsgILSupport" "No";
BA_DEF_DEF_  "GenMsgCycleTimeFast" 0;
BA_DEF_DEF_  "GenMsgCycleTime" 0;
BA_DEF_DEF_  "GenMsgDelayTime" 0;
BA_DEF_DEF_  "NmAsrMessage" "No";
BA_DEF_DEF_  "DiagState" "No";
BA_DEF_DEF_  "DiagConnection" 0;
BA_DEF_DEF_  "VFrameFormat" "StandardCAN_FD";
BA_DEF_DEF_  "CANFD_BRS" 0;
BA_ "VFrameFormat" BO_ 2654552196 15;
BA_ "VFrameFormat" BO_ 2654552195 15;
BA_ "VFrameFormat" BO_ 2654552194 15;
BA_ "VFrameFormat" BO_ 2654814232 15;
BA_ "VFrameFormat" BO_ 2654814208 1;
BA_ "VFrameFormat" BO_ 2654552193 15;
BA_ "VFrameFormat" BO_ 2654552192 15;
BA_ "VFrameFormat" BO_ 2654552185 15;
BA_ "VFrameFormat" BO_ 2654552184 15;
BA_ "VFrameFormat" BO_ 2654552183 15;
BA_ "VFrameFormat" BO_ 2654552182 15;
BA_ "VFrameFormat" BO_ 2654552181 15;
BA_ "VFrameFormat" BO_ 2654552180 15;
BA_ "VFrameFormat" BO_ 2654552179 15;
BA_ "VFrameFormat" BO_ 2654552178 15;
BA_ "VFrameFormat" BO_ 2654552177 15;
BA_ "VFrameFormat" BO_ 2654552176 15;
BA_ "VFrameFormat" BO_ 2654552169 15;
BA_ "GenMsgCycleTime" BO_ 2654552168 1000;
BA_ "VFrameFormat" BO_ 2654552168 15;
BA_ "GenMsgCycleTime" BO_ 2654552167 1000;
BA_ "VFrameFormat" BO_ 2654552167 15;
BA_ "GenMsgCycleTime" BO_ 2654552166 1000;
BA_ "VFrameFormat" BO_ 2654552166 15;
BA_ "GenMsgCycleTime" BO_ 2654552165 1000;
BA_ "VFrameFormat" BO_ 2654552165 15;
BA_ "VFrameFormat" BO_ 2654552164 15;
BA_ "VFrameFormat" BO_ 2654552163 15;
BA_ "VFrameFormat" BO_ 2654552162 15;
BA_ "VFrameFormat" BO_ 2654552161 15;
BA_ "VFrameFormat" BO_ 2654552160 15;
BA_ "VFrameFormat" BO_ 2654552153 15;
BA_ "VFrameFormat" BO_ 2654552152 15;
BA_ "GenMsgCycleTime" BO_ 2654552151 1000;
BA_ "VFrameFormat" BO_ 2654552151 15;
BA_ "VFrameFormat" BO_ 2654552150 15;
BA_ "VFrameFormat" BO_ 2654552149 15;
BA_ "VFrameFormat" BO_ 2654552148 15;
BA_ "VFrameFormat" BO_ 2654552147 15;
BA_ "VFrameFormat" BO_ 2654552146 15;
BA_ "VFrameFormat" BO_ 2654552145 15;
BA_ "VFrameFormat" BO_ 2654552144 15;
BA_ "VFrameFormat" BO_ 2654814240 15;
BA_ "VFrameFormat" BO_ 2654814238 15;
BA_ "VFrameFormat" BO_ 2654814241 1;
BA_ "VFrameFormat" BO_ 2654814242 15;
BA_ "VFrameFormat" BO_ 2654814243 15;
BA_ "VFrameFormat" BO_ 2654552136 1;
BA_ "GenMsgSendType" BO_ 2654552136 0;
BA_ "GenMsgILSupport" BO_ 2654552136 1;
BA_ "GenMsgCycleTime" BO_ 2654552136 40;
BA_ "VFrameFormat" BO_ 2654814246 15;
BA_ "GenSigSendType" SG_ 2654552196 Point_Map_Cruising_Age_15 1;
BA_ "GenSigSendType" SG_ 2654552196 Point_Map_Cruising_Age_14 1;
BA_ "GenSigSendType" SG_ 2654552196 Point_Map_Cruising_Age_13 1;
BA_ "GenSigSendType" SG_ 2654552196 Point_Map_Cruising_Age_12 1;
BA_ "GenSigSendType" SG_ 2654552196 Point_Map_Cruising_Age_11 1;
BA_ "GenSigSendType" SG_ 2654552196 Point_Map_Cruising_Age_10 1;
BA_ "GenSigSendType" SG_ 2654552196 Point_Map_Cruising_Age_9 1;
BA_ "GenSigSendType" SG_ 2654552196 Point_Map_Cruising_Age_8 1;
BA_ "GenSigSendType" SG_ 2654552196 Point_Map_Reserved_8 1;
BA_ "GenSigSendType" SG_ 2654552196 Point_Map_Age_8 1;
BA_ "GenSigSendType" SG_ 2654552196 Point_Map_Confidence_8 1;
BA_ "GenSigSendType" SG_ 2654552196 Point_Map_Height_8 1;
BA_ "GenSigSendType" SG_ 2654552196 Point_Map_Y_8 1;
BA_ "GenSigSendType" SG_ 2654552196 Point_Map_X_8 1;
BA_ "GenSigSendType" SG_ 2654552196 Point_Map_Reserved_15 1;
BA_ "GenSigSendType" SG_ 2654552196 Point_Map_Reserved_14 1;
BA_ "GenSigSendType" SG_ 2654552196 Point_Map_Reserved_13 1;
BA_ "GenSigSendType" SG_ 2654552196 Point_Map_Reserved_12 1;
BA_ "GenSigSendType" SG_ 2654552196 Point_Map_Reserved_11 1;
BA_ "GenSigSendType" SG_ 2654552196 Point_Map_Reserved_10 1;
BA_ "GenSigSendType" SG_ 2654552196 Point_Map_Reserved_9 1;
BA_ "GenSigSendType" SG_ 2654552196 Point_Map_Age_15 1;
BA_ "GenSigSendType" SG_ 2654552196 Point_Map_Confidence_15 1;
BA_ "GenSigSendType" SG_ 2654552196 Point_Map_Height_15 1;
BA_ "GenSigSendType" SG_ 2654552196 Point_Map_Y_15 1;
BA_ "GenSigSendType" SG_ 2654552196 Point_Map_X_15 1;
BA_ "GenSigSendType" SG_ 2654552196 Point_Map_Age_14 1;
BA_ "GenSigSendType" SG_ 2654552196 Point_Map_Confidence_14 1;
BA_ "GenSigSendType" SG_ 2654552196 Point_Map_Height_14 1;
BA_ "GenSigSendType" SG_ 2654552196 Point_Map_Y_14 1;
BA_ "GenSigSendType" SG_ 2654552196 Point_Map_X_14 1;
BA_ "GenSigSendType" SG_ 2654552196 Point_Map_Age_13 1;
BA_ "GenSigSendType" SG_ 2654552196 Point_Map_Confidence_13 1;
BA_ "GenSigSendType" SG_ 2654552196 Point_Map_Height_13 1;
BA_ "GenSigSendType" SG_ 2654552196 Point_Map_Y_13 1;
BA_ "GenSigSendType" SG_ 2654552196 Point_Map_X_13 1;
BA_ "GenSigSendType" SG_ 2654552196 Point_Map_Age_12 1;
BA_ "GenSigSendType" SG_ 2654552196 Point_Map_Confidence_12 1;
BA_ "GenSigSendType" SG_ 2654552196 Point_Map_Height_12 1;
BA_ "GenSigSendType" SG_ 2654552196 Point_Map_Y_12 1;
BA_ "GenSigSendType" SG_ 2654552196 Point_Map_X_12 1;
BA_ "GenSigSendType" SG_ 2654552196 Point_Map_Age_11 1;
BA_ "GenSigSendType" SG_ 2654552196 Point_Map_Confidence_11 1;
BA_ "GenSigSendType" SG_ 2654552196 Point_Map_Height_11 1;
BA_ "GenSigSendType" SG_ 2654552196 Point_Map_Y_11 1;
BA_ "GenSigSendType" SG_ 2654552196 Point_Map_X_11 1;
BA_ "GenSigSendType" SG_ 2654552196 Point_Map_Age_10 1;
BA_ "GenSigSendType" SG_ 2654552196 Point_Map_Confidence_10 1;
BA_ "GenSigSendType" SG_ 2654552196 Point_Map_Height_10 1;
BA_ "GenSigSendType" SG_ 2654552196 Point_Map_Y_10 1;
BA_ "GenSigSendType" SG_ 2654552196 Point_Map_X_10 1;
BA_ "GenSigSendType" SG_ 2654552196 Point_Map_Age_9 1;
BA_ "GenSigSendType" SG_ 2654552196 Point_Map_Confidence_9 1;
BA_ "GenSigSendType" SG_ 2654552196 Point_Map_Height_9 1;
BA_ "GenSigSendType" SG_ 2654552196 Point_Map_Y_9 1;
BA_ "GenSigSendType" SG_ 2654552196 Point_Map_X_9 1;
BA_ "GenSigSendType" SG_ 2654552195 Point_Map_Cruising_Age_7 1;
BA_ "GenSigSendType" SG_ 2654552195 Point_Map_Cruising_Age_6 1;
BA_ "GenSigSendType" SG_ 2654552195 Point_Map_Cruising_Age_5 1;
BA_ "GenSigSendType" SG_ 2654552195 Point_Map_Cruising_Age_4 1;
BA_ "GenSigSendType" SG_ 2654552195 Point_Map_Cruising_Age_3 1;
BA_ "GenSigSendType" SG_ 2654552195 Point_Map_Cruising_Age_2 1;
BA_ "GenSigSendType" SG_ 2654552195 Point_Map_Cruising_Age_1 1;
BA_ "GenSigSendType" SG_ 2654552195 Point_Map_Cruising_Age_0 1;
BA_ "GenSigSendType" SG_ 2654552195 Point_Map_Reserved_7 1;
BA_ "GenSigSendType" SG_ 2654552195 Point_Map_Reserved_6 1;
BA_ "GenSigSendType" SG_ 2654552195 Point_Map_Reserved_5 1;
BA_ "GenSigSendType" SG_ 2654552195 Point_Map_Reserved_4 1;
BA_ "GenSigSendType" SG_ 2654552195 Point_Map_Reserved_3 1;
BA_ "GenSigSendType" SG_ 2654552195 Point_Map_Reserved_2 1;
BA_ "GenSigSendType" SG_ 2654552195 Point_Map_Reserved_1 1;
BA_ "GenSigSendType" SG_ 2654552195 Point_Map_Reserved_0 1;
BA_ "GenSigSendType" SG_ 2654552195 Point_Map_Age_7 1;
BA_ "GenSigSendType" SG_ 2654552195 Point_Map_Confidence_7 1;
BA_ "GenSigSendType" SG_ 2654552195 Point_Map_Height_7 1;
BA_ "GenSigSendType" SG_ 2654552195 Point_Map_Y_7 1;
BA_ "GenSigSendType" SG_ 2654552195 Point_Map_X_7 1;
BA_ "GenSigSendType" SG_ 2654552195 Point_Map_Age_6 1;
BA_ "GenSigSendType" SG_ 2654552195 Point_Map_Confidence_6 1;
BA_ "GenSigSendType" SG_ 2654552195 Point_Map_Height_6 1;
BA_ "GenSigSendType" SG_ 2654552195 Point_Map_Y_6 1;
BA_ "GenSigSendType" SG_ 2654552195 Point_Map_X_6 1;
BA_ "GenSigSendType" SG_ 2654552195 Point_Map_Age_5 1;
BA_ "GenSigSendType" SG_ 2654552195 Point_Map_Confidence_5 1;
BA_ "GenSigSendType" SG_ 2654552195 Point_Map_Height_5 1;
BA_ "GenSigSendType" SG_ 2654552195 Point_Map_Y_5 1;
BA_ "GenSigSendType" SG_ 2654552195 Point_Map_X_5 1;
BA_ "GenSigSendType" SG_ 2654552195 Point_Map_Age_4 1;
BA_ "GenSigSendType" SG_ 2654552195 Point_Map_Confidence_4 1;
BA_ "GenSigSendType" SG_ 2654552195 Point_Map_Height_4 1;
BA_ "GenSigSendType" SG_ 2654552195 Point_Map_Y_4 1;
BA_ "GenSigSendType" SG_ 2654552195 Point_Map_X_4 1;
BA_ "GenSigSendType" SG_ 2654552195 Point_Map_Age_3 1;
BA_ "GenSigSendType" SG_ 2654552195 Point_Map_Confidence_3 1;
BA_ "GenSigSendType" SG_ 2654552195 Point_Map_Height_3 1;
BA_ "GenSigSendType" SG_ 2654552195 Point_Map_Y_3 1;
BA_ "GenSigSendType" SG_ 2654552195 Point_Map_X_3 1;
BA_ "GenSigSendType" SG_ 2654552195 Point_Map_Age_2 1;
BA_ "GenSigSendType" SG_ 2654552195 Point_Map_Confidence_2 1;
BA_ "GenSigSendType" SG_ 2654552195 Point_Map_Height_2 1;
BA_ "GenSigSendType" SG_ 2654552195 Point_Map_Y_2 1;
BA_ "GenSigSendType" SG_ 2654552195 Point_Map_X_2 1;
BA_ "GenSigSendType" SG_ 2654552195 Point_Map_Age_1 1;
BA_ "GenSigSendType" SG_ 2654552195 Point_Map_Confidence_1 1;
BA_ "GenSigSendType" SG_ 2654552195 Point_Map_Height_1 1;
BA_ "GenSigSendType" SG_ 2654552195 Point_Map_Y_1 1;
BA_ "GenSigSendType" SG_ 2654552195 Point_Map_X_1 1;
BA_ "GenSigSendType" SG_ 2654552195 Point_Map_Age_0 1;
BA_ "GenSigSendType" SG_ 2654552195 Point_Map_Confidence_0 1;
BA_ "GenSigSendType" SG_ 2654552195 Point_Map_Height_0 1;
BA_ "GenSigSendType" SG_ 2654552195 Point_Map_Y_0 1;
BA_ "GenSigSendType" SG_ 2654552195 Point_Map_X_0 1;
BA_ "GenSigSendType" SG_ 2654552194 IeAP_cm_RearRightMinXDist_KPI 1;
BA_ "GenSigSendType" SG_ 2654552194 IeAP_cm_RearRightMinXDist 1;
BA_ "GenSigSendType" SG_ 2654552194 IeAP_cm_RearLeftMinXDist_KPI 1;
BA_ "GenSigSendType" SG_ 2654552194 IeAP_cm_RearLeftMinXDist 1;
BA_ "GenSigSendType" SG_ 2654552194 IeAP_cm_RearCenterMinXDist_KPI 1;
BA_ "GenSigSendType" SG_ 2654552194 IeAP_cm_RearCenterMinXDist 1;
BA_ "GenSigSendType" SG_ 2654552194 IeAP_cm_FrntRightMinXDist_KPI 1;
BA_ "GenSigSendType" SG_ 2654552194 IeAP_cm_FrntRightMinXDist 1;
BA_ "GenSigSendType" SG_ 2654552194 IeAP_cm_FrntLeftMinXDist_KPI 1;
BA_ "GenSigSendType" SG_ 2654552194 IeAP_cm_FrntLeftMinXDist 1;
BA_ "GenSigSendType" SG_ 2654552194 IeAP_cm_FrntCenterMinXDist_KPI 1;
BA_ "GenSigSendType" SG_ 2654552194 IeAP_cm_FrntCenterMinXDist 1;
BA_ "GenSigSendType" SG_ 2654814232 IeAP_cm_RearRightMinXDist_KPI 1;
BA_ "GenSigSendType" SG_ 2654814232 IeAP_cm_RearLeftMinXDist_KPI 1;
BA_ "GenSigSendType" SG_ 2654814232 IeAP_cm_RearCenterMinXDist_KPI 1;
BA_ "GenSigSendType" SG_ 2654814232 IeAP_cm_FrntRightMinXDist_KPI 1;
BA_ "GenSigSendType" SG_ 2654814232 IeAP_cm_FrntLeftMinXDist_KPI 1;
BA_ "GenSigSendType" SG_ 2654814232 IeAP_cm_FrntCenterMinXDist_KPI 1;
BA_ "GenSigSendType" SG_ 2654814208 BOR_Blockage 1;
BA_ "GenSigSendType" SG_ 2654814208 AOR_Blockage 1;
BA_ "GenSigSendType" SG_ 2654814208 BOL_Blockage 1;
BA_ "GenSigSendType" SG_ 2654814208 AOL_Blockage 1;
BA_ "GenSigSendType" SG_ 2654814208 RSL_Blockage 1;
BA_ "GenSigSendType" SG_ 2654814208 ROL_Blockage 1;
BA_ "GenSigSendType" SG_ 2654814208 RIL_Blockage 1;
BA_ "GenSigSendType" SG_ 2654814208 RIR_Blockage 1;
BA_ "GenSigSendType" SG_ 2654814208 ROR_Blockage 1;
BA_ "GenSigSendType" SG_ 2654814208 RSR_Blockage 1;
BA_ "GenSigSendType" SG_ 2654814208 FSL_Blockage 1;
BA_ "GenSigSendType" SG_ 2654814208 FOL_Blockage 1;
BA_ "GenSigSendType" SG_ 2654814208 FIL_Blockage 1;
BA_ "GenSigSendType" SG_ 2654814208 FIR_Blockage 1;
BA_ "GenSigSendType" SG_ 2654814208 FOR_Blockage 1;
BA_ "GenSigSendType" SG_ 2654814208 FSR_Blockage 1;
BA_ "GenSigSendType" SG_ 2654552193 cntrCvpamFdData1_u16 1;
BA_ "GenSigSendType" SG_ 2654552193 crcCvpamFdData1_u8 1;
BA_ "GenSigSendType" SG_ 2654552193 msgcntrCvpamFdData1_u8 1;
BA_ "GenSigSendType" SG_ 2654552193 macCvpamFdData1_u64 1;
BA_ "GenSigSendType" SG_ 2654552193 obj_Pos_Longi 1;
BA_ "GenSigSendType" SG_ 2654552193 obj_Pos_Lat 1;
BA_ "GenSigSendType" SG_ 2654552193 objConf_e 1;
BA_ "GenSigSendType" SG_ 2654552193 FrontSensorDetHealth_e 1;
BA_ "GenSigStartValue" SG_ 2654552192 MeTHA_px_CplrPntY 298;
BA_ "GenSigSendType" SG_ 2654552192 MeTHA_px_CplrPntY 1;
BA_ "GenSigStartValue" SG_ 2654552192 MeTHA_px_CplrPntX 327;
BA_ "GenSigSendType" SG_ 2654552192 MeTHA_px_CplrPntX 1;
BA_ "GenSigStartValue" SG_ 2654552192 MeTHA_px_HitchPntY 298;
BA_ "GenSigSendType" SG_ 2654552192 MeTHA_px_HitchPntY 1;
BA_ "GenSigStartValue" SG_ 2654552192 MeTHA_px_HitchPntX 327;
BA_ "GenSigSendType" SG_ 2654552192 MeTHA_px_HitchPntX 1;
BA_ "GenSigSendType" SG_ 2654552192 MeTHA_pct_CplrTrckConf 1;
BA_ "GenSigSendType" SG_ 2654552192 MeTHA_pct_CplrDetConf 1;
BA_ "GenSigSendType" SG_ 2654552192 MeTHA_px_HitchCplrPixDiffLat 1;
BA_ "GenSigSendType" SG_ 2654552192 MeTHA_px_HitchCplrPixDiffLong 1;
BA_ "GenSigSendType" SG_ 2654552192 MeTHA_deg_CplrAng 1;
BA_ "GenSigSendType" SG_ 2654552192 MeTHA_e_CplrDetctStatus 1;
BA_ "GenSigSendType" SG_ 2654552192 MeTHA_e_HitchDetctStatus 1;
BA_ "GenSigSendType" SG_ 2654552185 MeTHA_deg_RoadWhlAng 1;
BA_ "GenSigSendType" SG_ 2654552185 MeTHA_b_THAAbortStatus 1;
BA_ "GenSigSendType" SG_ 2654552185 MeTHA_b_UsrCplrSelCnfm 1;
BA_ "GenSigSendType" SG_ 2654552185 MeTHA_b_UsrHitchCnfm 1;
BA_ "GenSigSendType" SG_ 2654552185 MeTHA_e_THAStateInfo 1;
BA_ "GenSigSendType" SG_ 2654552185 MeTHA_e_RearBrkSupprInfo 1;
BA_ "GenSigSendType" SG_ 2654552185 MeTHA_e_ScreenRequest 1;
BA_ "GenSigSendType" SG_ 2654552185 MeTHA_b_EnblRearParkAsstTrg 1;
BA_ "GenSigSendType" SG_ 2654552185 MeTHA_b_TrlrCplrStatus 1;
BA_ "GenSigSendType" SG_ 2654552185 IeTHA_e_PamChimeTyp 1;
BA_ "GenSigSendType" SG_ 2654552185 IeTHA_b_ChimeActvRhf 1;
BA_ "GenSigSendType" SG_ 2654552185 IeTHA_b_ChimeActvLhf 1;
BA_ "GenSigSendType" SG_ 2654552185 IeTHA_e_PamVol 1;
BA_ "GenSigSendType" SG_ 2654552184 LMD_m_Line_2_End_Range 1;
BA_ "GenSigSendType" SG_ 2654552184 LMD_m_Line_2_Start_Range 1;
BA_ "GenSigSendType" SG_ 2654552184 LMD_rad_Line_2_Heading 1;
BA_ "GenSigSendType" SG_ 2654552184 LMD_m_Line_2_Offset 1;
BA_ "GenSigSendType" SG_ 2654552184 LMD_e_Line_2_Type 1;
BA_ "GenSigSendType" SG_ 2654552184 LMD_pct_Line_2_Confidence 1;
BA_ "GenSigSendType" SG_ 2654552184 LMD_px_Line_2_Curvature 1;
BA_ "GenSigSendType" SG_ 2654552184 LMD_m_Line_1_End_Range 1;
BA_ "GenSigSendType" SG_ 2654552184 LMD_m_Line_1_Start_Range 1;
BA_ "GenSigSendType" SG_ 2654552184 LMD_rad_Line_1_Heading 1;
BA_ "GenSigSendType" SG_ 2654552184 LMD_m_Line_1_Offset 1;
BA_ "GenSigSendType" SG_ 2654552184 LMD_e_Line_1_Type 1;
BA_ "GenSigSendType" SG_ 2654552184 LMD_px_Line_1_Curvature 1;
BA_ "GenSigSendType" SG_ 2654552184 LMD_pct_Line_1_Confidence 1;
BA_ "GenSigSendType" SG_ 2654552183 MOT_ObjectDimensions_1_9 1;
BA_ "GenSigSendType" SG_ 2654552183 MOT_ObjectDimensions_0_9 1;
BA_ "GenSigSendType" SG_ 2654552183 MOT_ObjVelY_9 1;
BA_ "GenSigSendType" SG_ 2654552183 MOT_ObjVelX_9 1;
BA_ "GenSigSendType" SG_ 2654552183 MOT_ClosestPntDist_1_9 1;
BA_ "GenSigSendType" SG_ 2654552183 MOT_ClosestPntDist_0_9 1;
BA_ "GenSigSendType" SG_ 2654552183 MOT_ObjectDimensions_1_8 1;
BA_ "GenSigSendType" SG_ 2654552183 MOT_ObjectDimensions_0_8 1;
BA_ "GenSigSendType" SG_ 2654552183 MOT_ObjVelY_8 1;
BA_ "GenSigSendType" SG_ 2654552183 MOT_ObjVelX_8 1;
BA_ "GenSigSendType" SG_ 2654552183 MOT_ClosestPntDist_1_8 1;
BA_ "GenSigSendType" SG_ 2654552183 MOT_ClosestPntDist_0_8 1;
BA_ "GenSigSendType" SG_ 2654552183 MOT_ObjValid_9 1;
BA_ "GenSigSendType" SG_ 2654552183 MOT_ObjValid_8 1;
BA_ "GenSigSendType" SG_ 2654552182 MOT_ObjectDimensions_1_7 1;
BA_ "GenSigSendType" SG_ 2654552182 MOT_ObjectDimensions_0_7 1;
BA_ "GenSigSendType" SG_ 2654552182 MOT_ObjVelY_7 1;
BA_ "GenSigSendType" SG_ 2654552182 MOT_ObjVelX_7 1;
BA_ "GenSigSendType" SG_ 2654552182 MOT_ClosestPntDist_1_7 1;
BA_ "GenSigSendType" SG_ 2654552182 MOT_ClosestPntDist_0_7 1;
BA_ "GenSigSendType" SG_ 2654552182 MOT_ObjectDimensions_1_6 1;
BA_ "GenSigSendType" SG_ 2654552182 MOT_ObjectDimensions_0_6 1;
BA_ "GenSigSendType" SG_ 2654552182 MOT_ObjVelY_6 1;
BA_ "GenSigSendType" SG_ 2654552182 MOT_ObjVelX_6 1;
BA_ "GenSigSendType" SG_ 2654552182 MOT_ClosestPntDist_1_6 1;
BA_ "GenSigSendType" SG_ 2654552182 MOT_ClosestPntDist_0_6 1;
BA_ "GenSigSendType" SG_ 2654552182 MOT_ObjValid_7 1;
BA_ "GenSigSendType" SG_ 2654552182 MOT_ObjValid_6 1;
BA_ "GenSigSendType" SG_ 2654552181 MOT_ObjectDimensions_1_5 1;
BA_ "GenSigSendType" SG_ 2654552181 MOT_ObjectDimensions_0_5 1;
BA_ "GenSigSendType" SG_ 2654552181 MOT_ObjVelY_5 1;
BA_ "GenSigSendType" SG_ 2654552181 MOT_ObjVelX_5 1;
BA_ "GenSigSendType" SG_ 2654552181 MOT_ClosestPntDist_1_5 1;
BA_ "GenSigSendType" SG_ 2654552181 MOT_ClosestPntDist_0_5 1;
BA_ "GenSigSendType" SG_ 2654552181 MOT_ObjectDimensions_1_4 1;
BA_ "GenSigSendType" SG_ 2654552181 MOT_ObjectDimensions_0_4 1;
BA_ "GenSigSendType" SG_ 2654552181 MOT_ObjVelY_4 1;
BA_ "GenSigSendType" SG_ 2654552181 MOT_ObjVelX_4 1;
BA_ "GenSigSendType" SG_ 2654552181 MOT_ClosestPntDist_1_4 1;
BA_ "GenSigSendType" SG_ 2654552181 MOT_ClosestPntDist_0_4 1;
BA_ "GenSigSendType" SG_ 2654552181 MOT_ObjValid_5 1;
BA_ "GenSigSendType" SG_ 2654552181 MOT_ObjValid_4 1;
BA_ "GenSigSendType" SG_ 2654552180 MOT_ObjectDimensions_1_3 1;
BA_ "GenSigSendType" SG_ 2654552180 MOT_ObjectDimensions_0_3 1;
BA_ "GenSigSendType" SG_ 2654552180 MOT_ObjVelY_3 1;
BA_ "GenSigSendType" SG_ 2654552180 MOT_ObjVelX_3 1;
BA_ "GenSigSendType" SG_ 2654552180 MOT_ClosestPntDist_1_3 1;
BA_ "GenSigSendType" SG_ 2654552180 MOT_ClosestPntDist_0_3 1;
BA_ "GenSigSendType" SG_ 2654552180 MOT_ObjectDimensions_1_2 1;
BA_ "GenSigSendType" SG_ 2654552180 MOT_ObjectDimensions_0_2 1;
BA_ "GenSigSendType" SG_ 2654552180 MOT_ObjVelY_2 1;
BA_ "GenSigSendType" SG_ 2654552180 MOT_ObjVelX_2 1;
BA_ "GenSigSendType" SG_ 2654552180 MOT_ClosestPntDist_1_2 1;
BA_ "GenSigSendType" SG_ 2654552180 MOT_ClosestPntDist_0_2 1;
BA_ "GenSigSendType" SG_ 2654552180 MOT_ObjValid_3 1;
BA_ "GenSigSendType" SG_ 2654552180 MOT_ObjValid_2 1;
BA_ "GenSigSendType" SG_ 2654552179 MOT_ObjValid_1 1;
BA_ "GenSigSendType" SG_ 2654552179 MOT_ObjValid_0 1;
BA_ "GenSigSendType" SG_ 2654552179 MOT_ObjectDimensions_1_1 1;
BA_ "GenSigSendType" SG_ 2654552179 MOT_ObjectDimensions_0_1 1;
BA_ "GenSigSendType" SG_ 2654552179 MOT_ObjVelY_1 1;
BA_ "GenSigSendType" SG_ 2654552179 MOT_ObjVelX_1 1;
BA_ "GenSigSendType" SG_ 2654552179 MOT_ClosestPntDist_1_1 1;
BA_ "GenSigSendType" SG_ 2654552179 MOT_ClosestPntDist_0_1 1;
BA_ "GenSigSendType" SG_ 2654552179 MOT_ObjectDimensions_1_0 1;
BA_ "GenSigSendType" SG_ 2654552179 MOT_ObjectDimensions_0_0 1;
BA_ "GenSigSendType" SG_ 2654552179 MOT_ObjVelY_0 1;
BA_ "GenSigSendType" SG_ 2654552179 MOT_ObjVelX_0 1;
BA_ "GenSigSendType" SG_ 2654552179 MOT_ClosestPntDist_1_0 1;
BA_ "GenSigSendType" SG_ 2654552179 MOT_ClosestPntDist_0_0 1;
BA_ "GenSigSendType" SG_ 2654552178 perpParkDirectionSel 1;
BA_ "GenSigSendType" SG_ 2654552178 parkExtSideSel 1;
BA_ "GenSigSendType" SG_ 2654552178 slotSide 1;
BA_ "GenSigSendType" SG_ 2654552178 parkingDirection 1;
BA_ "GenSigSendType" SG_ 2654552178 parkingSlotType 1;
BA_ "GenSigSendType" SG_ 2654552178 IsBackSftbtnSel 1;
BA_ "GenSigSendType" SG_ 2654552178 IsSlotSel 1;
BA_ "GenSigSendType" SG_ 2654552178 IsExitSftBtnSel 1;
BA_ "GenSigSendType" SG_ 2654552178 IsParkSftBtnSel 1;
BA_ "GenSigSendType" SG_ 2654552178 MaAP_m_ParkSpot4RearStreetY 1;
BA_ "GenSigSendType" SG_ 2654552178 MaAP_m_ParkSpot4RearStreetX 1;
BA_ "GenSigSendType" SG_ 2654552178 MaAP_m_ParkSpot3RearBorderY 1;
BA_ "GenSigSendType" SG_ 2654552178 MaAP_m_ParkSpot3RearBorderX 1;
BA_ "GenSigSendType" SG_ 2654552178 MaAP_m_ParkSpot2FrntBorderY 1;
BA_ "GenSigSendType" SG_ 2654552178 MaAP_m_ParkSpot2FrntBorderX 1;
BA_ "GenSigSendType" SG_ 2654552178 MaAP_m_ParkSpot1FrntStreetY 1;
BA_ "GenSigSendType" SG_ 2654552178 MaAP_m_ParkSpot1FrntStreetX 1;
BA_ "GenSigSendType" SG_ 2654552177 IeVBII_nfcd_MinDisToCollisionObj 1;
BA_ "GenSigSendType" SG_ 2654552177 NFCD_ObjValid_9 1;
BA_ "GenSigSendType" SG_ 2654552177 NFCD_DistanceToClosestPoint_1_9 1;
BA_ "GenSigSendType" SG_ 2654552177 NFCD_DistanceToClosestPoint_0_9 1;
BA_ "GenSigSendType" SG_ 2654552177 NFCD_ObjValid_8 1;
BA_ "GenSigSendType" SG_ 2654552177 NFCD_DistanceToClosestPoint_1_8 1;
BA_ "GenSigSendType" SG_ 2654552177 NFCD_DistanceToClosestPoint_0_8 1;
BA_ "GenSigSendType" SG_ 2654552177 NFCD_ObjValid_7 1;
BA_ "GenSigSendType" SG_ 2654552177 NFCD_DistanceToClosestPoint_1_7 1;
BA_ "GenSigSendType" SG_ 2654552177 NFCD_DistanceToClosestPoint_0_7 1;
BA_ "GenSigSendType" SG_ 2654552177 NFCD_ObjValid_6 1;
BA_ "GenSigSendType" SG_ 2654552177 NFCD_DistanceToClosestPoint_1_6 1;
BA_ "GenSigSendType" SG_ 2654552177 NFCD_DistanceToClosestPoint_0_6 1;
BA_ "GenSigSendType" SG_ 2654552177 NFCD_ObjValid_5 1;
BA_ "GenSigSendType" SG_ 2654552177 NFCD_DistanceToClosestPoint_1_5 1;
BA_ "GenSigSendType" SG_ 2654552177 NFCD_DistanceToClosestPoint_0_5 1;
BA_ "GenSigSendType" SG_ 2654552176 NFCD_DistanceToClosestPoint_1_4 1;
BA_ "GenSigSendType" SG_ 2654552176 NFCD_DistanceToClosestPoint_0_4 1;
BA_ "GenSigSendType" SG_ 2654552176 NFCD_ObjValid_4 1;
BA_ "GenSigSendType" SG_ 2654552176 NFCD_ObjValid_3 1;
BA_ "GenSigSendType" SG_ 2654552176 NFCD_DistanceToClosestPoint_1_3 1;
BA_ "GenSigSendType" SG_ 2654552176 NFCD_DistanceToClosestPoint_0_3 1;
BA_ "GenSigSendType" SG_ 2654552176 NFCD_ObjValid_2 1;
BA_ "GenSigSendType" SG_ 2654552176 NFCD_DistanceToClosestPoint_1_2 1;
BA_ "GenSigSendType" SG_ 2654552176 NFCD_DistanceToClosestPoint_0_2 1;
BA_ "GenSigSendType" SG_ 2654552176 NFCD_ObjValid_1 1;
BA_ "GenSigSendType" SG_ 2654552176 NFCD_DistanceToClosestPoint_1_1 1;
BA_ "GenSigSendType" SG_ 2654552176 NFCD_DistanceToClosestPoint_0_1 1;
BA_ "GenSigSendType" SG_ 2654552176 NFCD_ObjValid_0 1;
BA_ "GenSigSendType" SG_ 2654552176 NFCD_DistanceToClosestPoint_1_0 1;
BA_ "GenSigSendType" SG_ 2654552176 NFCD_DistanceToClosestPoint_0_0 1;
BA_ "GenSigSendType" SG_ 2654552169 IeAutoPark_e_AlgoState 1;
BA_ "GenSigSendType" SG_ 2654552169 IeAP_e_AutoParkStatus 1;
BA_ "GenSigSendType" SG_ 2654552169 MeAP_e_ParkAssistStatus 1;
BA_ "GenSigSendType" SG_ 2654552169 MeAP_e_Park_state 1;
BA_ "GenSigSendType" SG_ 2654552169 MeAP_a_ThrtlCmd 1;
BA_ "GenSigSendType" SG_ 2654552169 MeAP_a_BrkCmd 1;
BA_ "GenSigSendType" SG_ 2654552169 MeAP_deg_StrCmd 1;
BA_ "GenSigSendType" SG_ 2654552169 MeAP_b_PPPADisable 1;
BA_ "GenSigSendType" SG_ 2654552169 MeAP_b_PPPADefEng 1;
BA_ "GenSigSendType" SG_ 2654552169 MeAP_b_PPPAActv4LOW 1;
BA_ "GenSigSendType" SG_ 2654552169 MeAP_b_PPPAActvTrlr 1;
BA_ "GenSigSendType" SG_ 2654552169 MeAP_b_PARBDisable 1;
BA_ "GenSigSendType" SG_ 2654552169 MeAP_b_PARBActv4LOW 1;
BA_ "GenSigSendType" SG_ 2654552169 MeAP_b_PARBActvTrlr 1;
BA_ "GenSigSendType" SG_ 2654552169 MeAP_b_RPAVolDefMed 1;
BA_ "GenSigSendType" SG_ 2654552169 MeAP_b_FPAVolDefMed 1;
BA_ "GenSigSendType" SG_ 2654552169 MeAP_b_PAVolDefMed 1;
BA_ "GenSigSendType" SG_ 2654552169 MeAP_b_RPAActvTrlr 1;
BA_ "GenSigSendType" SG_ 2654552169 MeAP_b_RPADisable 1;
BA_ "GenSigSendType" SG_ 2654552169 MeAP_b_FPADisable 1;
BA_ "GenSigSendType" SG_ 2654552169 MeAP_b_FeatureEnbl 1;
BA_ "GenSigSendType" SG_ 2654552169 MeAP_b_VehCndSts 1;
BA_ "GenSigSendType" SG_ 2654552169 IeAP_b_MnvPosOk 1;
BA_ "GenSigSendType" SG_ 2654552169 MeAP_b_SteerActionReq 1;
BA_ "GenSigSendType" SG_ 2654552169 MeAP_b_PosMet 1;
BA_ "GenSigSendType" SG_ 2654552169 MeAP_b_ManeuverSuccess 1;
BA_ "GenSigSendType" SG_ 2654552169 MeAP_b_ManeuverAbort 1;
BA_ "GenSigSendType" SG_ 2654552169 MeAP_b_BSMHandshakeActv 1;
BA_ "GenSigSendType" SG_ 2654552169 MeAP_b_StandStill 1;
BA_ "GenSigSendType" SG_ 2654552169 MeAP_b_DriverOverride 1;
BA_ "GenSigSendType" SG_ 2654552169 MeAP_b_APInitSts 1;
BA_ "GenSigSendType" SG_ 2654552169 MeAP_b_SeekSpdExceedTimeout 1;
BA_ "GenSigSendType" SG_ 2654552169 MeAP_b_PausedPressBtnTimeout 1;
BA_ "GenSigSendType" SG_ 2654552169 MeAP_b_ObjInPathTimeout 1;
BA_ "GenSigSendType" SG_ 2654552169 MeAP_b_CamHandshakeTimeout 1;
BA_ "GenSigSendType" SG_ 2654552169 MeAP_b_GearShiftWaitTimeout 1;
BA_ "GenSigSendType" SG_ 2654552169 MeAP_b_EPSInterfaceTimeout 1;
BA_ "GenSigSendType" SG_ 2654552169 MeAP_b_BSMInterfaceTimeout 1;
BA_ "GenSigSendType" SG_ 2654552169 MeAP_b_VCOpPaused 1;
BA_ "GenSigSendType" SG_ 2654552169 MeAP_b_RPAwithBrkStatus 1;
BA_ "GenSigSendType" SG_ 2654552169 MeAP_b_RPAStatus 1;
BA_ "GenSigSendType" SG_ 2654552169 MeAP_b_FPAStatus 1;
BA_ "GenSigSendType" SG_ 2654552169 IeAP_e_AbortCon 1;
BA_ "GenSigSendType" SG_ 2654552169 IeAP_cnt_CurrentVehSweep 1;
BA_ "GenSigSendType" SG_ 2654552169 MeAP_e_PP_state 1;
BA_ "GenSigSendType" SG_ 2654552169 MeAP_cm_RearRightMinXDist 1;
BA_ "GenSigSendType" SG_ 2654552169 MeAP_cm_RearLeftMinXDist 1;
BA_ "GenSigSendType" SG_ 2654552169 MeAP_cm_RearCenterMinXDist 1;
BA_ "GenSigSendType" SG_ 2654552169 MeAP_cm_FrntRightMinXDist 1;
BA_ "GenSigSendType" SG_ 2654552169 MeAP_cm_FrntLeftMinXDist 1;
BA_ "GenSigSendType" SG_ 2654552169 MeAP_cm_FrntCenterMinXDist 1;
BA_ "GenSigSendType" SG_ 2654552169 MeAP_cnt_TransDebugVar_Copy_1 1;
BA_ "GenSigSendType" SG_ 2654552169 MeAP_cnt_TransDebugVar 1;
BA_ "GenSigSendType" SG_ 2654552169 MeAP_cnt_StateDebugVar 1;
BA_ "GenSigSendType" SG_ 2654552168 m_QM_FID_TRSC_ASCMDef 1;
BA_ "GenSigSendType" SG_ 2654552168 m_QM_FID_TRSC_LIMITED_DefView 1;
BA_ "GenSigSendType" SG_ 2654552168 m_QM_FID_TRSC_CAM_CAL_ABORT 1;
BA_ "GenSigSendType" SG_ 2654552168 m_QM_FID_TRSC_LIMITED_View 1;
BA_ "GenSigSendType" SG_ 2654552168 m_QM_FID_TRSC_DISABLED 1;
BA_ "GenSigSendType" SG_ 2654552167 Trailer_tracking_confidence 1;
BA_ "GenSigSendType" SG_ 2654552167 Trailer_Recognition_Confidence 1;
BA_ "GenSigSendType" SG_ 2654552167 OBTLRecalibrate 1;
BA_ "GenSigSendType" SG_ 2654552167 Presentinfo 1;
BA_ "GenSigSendType" SG_ 2654552167 RecognitionInfo 1;
BA_ "GenSigSendType" SG_ 2654552167 trailerCalibrationDelay 1;
BA_ "GenSigSendType" SG_ 2654552167 trailerCalibrationCount 1;
BA_ "GenSigSendType" SG_ 2654552167 TrailerCalFailInfo 1;
BA_ "GenSigSendType" SG_ 2654552167 Trailercalinfo 1;
BA_ "GenSigStartValue" SG_ 2654552167 Trailercalinfo 2;
BA_ "GenSigSendType" SG_ 2654552167 turnaroundSubState 1;
BA_ "GenSigSendType" SG_ 2654552167 calibrationCompleted 1;
BA_ "GenSigSendType" SG_ 2654552167 JackknifeThrAngle 1;
BA_ "GenSigSendType" SG_ 2654552167 JackknifeAngle 1;
BA_ "GenSigSendType" SG_ 2654552167 hitchLength 1;
BA_ "GenSigStartValue" SG_ 2654552167 hitchLength 100000;
BA_ "GenSigSendType" SG_ 2654552167 curState 1;
BA_ "GenSigSendType" SG_ 2654552167 CurrentTrailer_ID 1;
BA_ "GenSigStartValue" SG_ 2654552167 CurrentTrailer_ID 6;
BA_ "GenSigSendType" SG_ 2654552167 calibrationSubState 1;
BA_ "GenSigSendType" SG_ 2654552167 TADAngleRate 1;
BA_ "GenSigSendType" SG_ 2654552167 TrailerAngleSign 1;
BA_ "GenSigStartValue" SG_ 2654552167 TrailerAngleSign 3;
BA_ "GenSigSendType" SG_ 2654552167 trailerAngle 1;
BA_ "GenSigSendType" SG_ 2654552166 MeTRSC_M_SteeringTorqInfo 1;
BA_ "GenSigSendType" SG_ 2654552166 MeTRSC_e_TrlrPrsntInfoCAN 1;
BA_ "GenSigSendType" SG_ 2654552166 MeTRSC_b_TrlrRevSteeringStsInfo 1;
BA_ "GenSigSendType" SG_ 2654552166 MeTRSC_b_TRSCSwitchPressed 1;
BA_ "GenSigSendType" SG_ 2654552166 MeTRSC_b_OBTLRecalibrate 1;
BA_ "GenSigSendType" SG_ 2654552166 MeSVS_e_DispView2Info 1;
BA_ "GenSigSendType" SG_ 2654552166 MeTRSC_deg_KnobAngle 1;
BA_ "GenSigSendType" SG_ 2654552166 MeTRSC_b_MoreCamSoftButtEnbl 1;
BA_ "GenSigStartValue" SG_ 2654552166 MeTRSC_deg_DetJackKnifeAngle 5300;
BA_ "GenSigSendType" SG_ 2654552166 MeTRSC_deg_DetJackKnifeAngle 1;
BA_ "GenSigStartValue" SG_ 2654552166 MeTRSC_m_DetTrailerBeamLen 100;
BA_ "GenSigSendType" SG_ 2654552166 MeTRSC_m_DetTrailerBeamLen 1;
BA_ "GenSigStartValue" SG_ 2654552166 MeTRSC_deg_DetJackknifeThrAngle 5300;
BA_ "GenSigSendType" SG_ 2654552166 MeTRSC_deg_DetJackknifeThrAngle 1;
BA_ "GenSigStartValue" SG_ 2654552166 MeTRSC_b_TrlrCalibPopInfo 1;
BA_ "GenSigSendType" SG_ 2654552166 MeTRSC_b_TrlrCalibPopInfo 1;
BA_ "GenSigSendType" SG_ 2654552166 MeTRSC_b_TrlrCalibDelayInfo 1;
BA_ "GenSigSendType" SG_ 2654552166 MeTRSC_cnt_TrlrCalibFailCntInfo 1;
BA_ "GenSigSendType" SG_ 2654552165 IeTRSC_e_TRSCAbortReas 1;
BA_ "GenSigSendType" SG_ 2654552165 MeTRSC_e_TRSCStat 1;
BA_ "GenSigSendType" SG_ 2654552165 IeTRSC_e_TrlrAngGrapOverSts 1;
BA_ "GenSigSendType" SG_ 2654552165 IeTRSC_e_TRSCUnavailReas 1;
BA_ "GenSigSendType" SG_ 2654552165 IeTRSC_e_CamBlockSts 1;
BA_ "GenSigSendType" SG_ 2654552165 IeTRSC_kph_VehSpeedVSOSig 1;
BA_ "GenSigSendType" SG_ 2654552165 IeTRSC_M_TRSCStrTrq 1;
BA_ "GenSigSendType" SG_ 2654552165 IeTRSC_deg_JackknifeThrAngle 1;
BA_ "GenSigSendType" SG_ 2654552165 IeTRSC_deg_TADAngle 1;
BA_ "GenSigSendType" SG_ 2654552165 IeTRSC_deg_TrlrAngKnob 1;
BA_ "GenSigSendType" SG_ 2654552165 IeTRSC_e_TrlrRecogInfo 1;
BA_ "GenSigSendType" SG_ 2654552165 IeTRSC_e_TRSKMSts 1;
BA_ "GenSigSendType" SG_ 2654552165 IeTRSC_e_TRSKMCenBtnSts 1;
BA_ "GenSigSendType" SG_ 2654552165 IeTRSC_e_TRSKMBtnSts 1;
BA_ "GenSigSendType" SG_ 2654552165 IeTRSC_e_TrailerID 1;
BA_ "GenSigSendType" SG_ 2654552165 IeTRSC_e_GearShiftSts 1;
BA_ "GenSigSendType" SG_ 2654552165 IeTRSC_deg_FrntWhlAng 1;
BA_ "GenSigSendType" SG_ 2654552165 IeTRSC_e_TrlrPrsntSts 1;
BA_ "GenSigSendType" SG_ 2654552165 IeTRSC_e_TrlrPrsntFailReas 1;
BA_ "GenSigSendType" SG_ 2654552165 IeTRSC_e_TrlrCalibSts 1;
BA_ "GenSigSendType" SG_ 2654552165 IeTRSC_e_TrlrCalibManState 1;
BA_ "GenSigSendType" SG_ 2654552165 IeTRSC_e_TrlrCalibFailReas 1;
BA_ "GenSigSendType" SG_ 2654552165 IeTRSC_cnt_TrlrCalibPassCntCurr 1;
BA_ "GenSigSendType" SG_ 2654552165 IeTRSC_cnt_TrlrCalibPassCnt 1;
BA_ "GenSigSendType" SG_ 2654552165 IeTRSC_cnt_TrlrCalibFailCntCurr 1;
BA_ "GenSigSendType" SG_ 2654552165 IeTRSC_cnt_TrlrCalibFailCnt 1;
BA_ "GenSigSendType" SG_ 2654552165 IeTRSC_cnt_KnobPos 1;
BA_ "GenSigSendType" SG_ 2654552164 Roll_f32_EOL_Right 1;
BA_ "GenSigSendType" SG_ 2654552164 Pitch_f32_EOL_Right 1;
BA_ "GenSigSendType" SG_ 2654552164 Yaw_f32_EOL_Right 1;
BA_ "GenSigSendType" SG_ 2654552164 Z_f32_EOL_Right 1;
BA_ "GenSigSendType" SG_ 2654552164 Y_f32_EOL_Right 1;
BA_ "GenSigSendType" SG_ 2654552164 X_f32_EOL_Right 1;
BA_ "GenSigSendType" SG_ 2654552164 Pitch_f32_EOL_Rear 1;
BA_ "GenSigSendType" SG_ 2654552164 Roll_f32_EOL_Rear 1;
BA_ "GenSigSendType" SG_ 2654552164 Yaw_f32_EOL_Rear 1;
BA_ "GenSigSendType" SG_ 2654552164 Z_f32_EOL_Rear 1;
BA_ "GenSigSendType" SG_ 2654552164 Y_f32_EOL_Rear 1;
BA_ "GenSigSendType" SG_ 2654552164 X_f32_EOL_Rear 1;
BA_ "GenSigSendType" SG_ 2654552163 Z_f32_Current_Right 1;
BA_ "GenSigSendType" SG_ 2654552163 Z_f32_Current_Rear 1;
BA_ "GenSigSendType" SG_ 2654552163 Pitch_f32_Current_Right 1;
BA_ "GenSigSendType" SG_ 2654552163 Pitch_f32_Current_Rear 1;
BA_ "GenSigSendType" SG_ 2654552163 Roll_f32_Current_Right 1;
BA_ "GenSigSendType" SG_ 2654552163 Roll_f32_Current_Rear 1;
BA_ "GenSigSendType" SG_ 2654552163 Yaw_f32_Current_Right 1;
BA_ "GenSigSendType" SG_ 2654552163 Yaw_f32_Current_Rear 1;
BA_ "GenSigSendType" SG_ 2654552163 Y_f32_Current_Right 1;
BA_ "GenSigSendType" SG_ 2654552163 Y_f32_Current_Rear 1;
BA_ "GenSigSendType" SG_ 2654552163 X_f32_Current_Right 1;
BA_ "GenSigSendType" SG_ 2654552163 X_f32_Current_Rear 1;
BA_ "GenSigSendType" SG_ 2654552162 InvalidFeatures_Right_u32 1;
BA_ "GenSigSendType" SG_ 2654552162 IgnoredFeatures_Right_u32 1;
BA_ "GenSigSendType" SG_ 2654552162 ValidFeatures_Right_u32 1;
BA_ "GenSigSendType" SG_ 2654552162 InvalidFeatures_Rear_u32 1;
BA_ "GenSigSendType" SG_ 2654552162 IgnoredFeatures_Rear_u32 1;
BA_ "GenSigSendType" SG_ 2654552162 ValidFeatures_Rear_u32 1;
BA_ "GenSigSendType" SG_ 2654552162 InvalidFeatures_Left_u32 1;
BA_ "GenSigSendType" SG_ 2654552162 IgnoredFeatures_Left_u32 1;
BA_ "GenSigSendType" SG_ 2654552162 ValidFeatures_Left_u32 1;
BA_ "GenSigSendType" SG_ 2654552162 InvalidFeatures_Front_u32 1;
BA_ "GenSigSendType" SG_ 2654552162 IgnoredFeatures_Front_u32 1;
BA_ "GenSigSendType" SG_ 2654552162 ValidFeatures_Front_u32 1;
BA_ "GenSigSendType" SG_ 2654552161 TargetDetectRightRear_Right_s8 1;
BA_ "GenSigSendType" SG_ 2654552161 TargetDetectRightFront_Right_s8 1;
BA_ "GenSigSendType" SG_ 2654552161 TargetDetectLeftRear_Right_s8 1;
BA_ "GenSigSendType" SG_ 2654552161 TargetDetectLeftFront_Right_s8 1;
BA_ "GenSigSendType" SG_ 2654552161 TargetLimitRear_Right_s8 1;
BA_ "GenSigSendType" SG_ 2654552161 TargetLimitFront_Right_s8 1;
BA_ "GenSigSendType" SG_ 2654552161 TargetInit_Right_s8 1;
BA_ "GenSigSendType" SG_ 2654552161 TargetDetectRightRear_Rear_s8 1;
BA_ "GenSigSendType" SG_ 2654552161 TargetDetectRightFront_Rear_s8 1;
BA_ "GenSigSendType" SG_ 2654552161 TargetDetectLeftRear_Rear_s8 1;
BA_ "GenSigSendType" SG_ 2654552161 TargetDetectLeftFront_Rear_s8 1;
BA_ "GenSigSendType" SG_ 2654552161 TargetLimitRear_Rear_s8 1;
BA_ "GenSigSendType" SG_ 2654552161 TargetLimitFront_Rear_s8 1;
BA_ "GenSigSendType" SG_ 2654552161 TargetInit_Rear_s8 1;
BA_ "GenSigSendType" SG_ 2654552161 TargetDetectRightRear_Left_s8 1;
BA_ "GenSigSendType" SG_ 2654552161 TargetDetectRightFront_Left_s8 1;
BA_ "GenSigSendType" SG_ 2654552161 TargetDetectLeftFront_Left_s8 1;
BA_ "GenSigSendType" SG_ 2654552161 TargetLimitRear_Left_s8 1;
BA_ "GenSigSendType" SG_ 2654552161 TargetLimitFront_Left_s8 1;
BA_ "GenSigSendType" SG_ 2654552161 TargetInit_Left_s8 1;
BA_ "GenSigSendType" SG_ 2654552161 TargetDetectRightRear_Front_s8 1;
BA_ "GenSigSendType" SG_ 2654552161 TargetDetectRightFront_Front_s8 1;
BA_ "GenSigSendType" SG_ 2654552161 TargetDetectLeftRear_Front_s8 1;
BA_ "GenSigSendType" SG_ 2654552161 TargetDetectLeftFront_Front_s8 1;
BA_ "GenSigSendType" SG_ 2654552161 TargetLimitRear_Front_s8 1;
BA_ "GenSigSendType" SG_ 2654552161 TargetLimitFront_Front_s8 1;
BA_ "GenSigSendType" SG_ 2654552161 TargetInit_Front_s8 1;
BA_ "GenSigSendType" SG_ 2654552160 Z_f32_Current_Rear 1;
BA_ "GenSigSendType" SG_ 2654552160 Y_f32_Current_Rear 1;
BA_ "GenSigSendType" SG_ 2654552160 X_f32_Current_Rear 1;
BA_ "GenSigSendType" SG_ 2654552160 Pitch_f32_OC_Right 1;
BA_ "GenSigSendType" SG_ 2654552160 Roll_f32_OC_Right 1;
BA_ "GenSigSendType" SG_ 2654552160 Yaw_f32_OC_Right 1;
BA_ "GenSigSendType" SG_ 2654552160 Pitch_f32_OC_Rear 1;
BA_ "GenSigSendType" SG_ 2654552160 Roll_f32_OC_Rear 1;
BA_ "GenSigSendType" SG_ 2654552160 Yaw_f32_OC_Rear 1;
BA_ "GenSigSendType" SG_ 2654552160 Pitch_f32_OC_Left 1;
BA_ "GenSigSendType" SG_ 2654552160 Roll_f32_OC_Left 1;
BA_ "GenSigSendType" SG_ 2654552160 Yaw_f32_OC_Left 1;
BA_ "GenSigSendType" SG_ 2654552160 Pitch_f32_OC_Front 1;
BA_ "GenSigSendType" SG_ 2654552160 Roll_f32_OC_Front 1;
BA_ "GenSigSendType" SG_ 2654552160 Yaw_f32_OC_Front 1;
BA_ "GenSigSendType" SG_ 2654552153 Pitch_f32_SC_Right 1;
BA_ "GenSigSendType" SG_ 2654552153 Roll_f32_SC_Right 1;
BA_ "GenSigSendType" SG_ 2654552153 Yaw_f32_SC_Right 1;
BA_ "GenSigSendType" SG_ 2654552153 Pitch_f32_SC_Rear 1;
BA_ "GenSigSendType" SG_ 2654552153 Roll_f32_SC_Rear 1;
BA_ "GenSigSendType" SG_ 2654552153 Yaw_f32_SC_Rear 1;
BA_ "GenSigSendType" SG_ 2654552153 Pitch_f32_SC_Left 1;
BA_ "GenSigSendType" SG_ 2654552153 Roll_f32_SC_Left 1;
BA_ "GenSigSendType" SG_ 2654552153 Yaw_f32_SC_Left 1;
BA_ "GenSigSendType" SG_ 2654552153 Pitch_f32_SC_Front 1;
BA_ "GenSigSendType" SG_ 2654552153 Roll_f32_SC_Front 1;
BA_ "GenSigSendType" SG_ 2654552153 Yaw_f32_SC_Front 1;
BA_ "GenSigSendType" SG_ 2654552152 Pitch_f32_EOL_Left 1;
BA_ "GenSigSendType" SG_ 2654552152 Roll_f32_EOL_Left 1;
BA_ "GenSigSendType" SG_ 2654552152 Yaw_f32_EOL_Left 1;
BA_ "GenSigSendType" SG_ 2654552152 Z_f32_EOL_Left 1;
BA_ "GenSigSendType" SG_ 2654552152 Y_f32_EOL_Left 1;
BA_ "GenSigSendType" SG_ 2654552152 X_f32_EOL_Left 1;
BA_ "GenSigSendType" SG_ 2654552152 Pitch_f32_EOL_Front 1;
BA_ "GenSigSendType" SG_ 2654552152 Roll_f32_EOL_Front 1;
BA_ "GenSigSendType" SG_ 2654552152 Yaw_f32_EOL_Front 1;
BA_ "GenSigSendType" SG_ 2654552152 Z_f32_EOL_Front 1;
BA_ "GenSigSendType" SG_ 2654552152 Y_f32_EOL_Front 1;
BA_ "GenSigSendType" SG_ 2654552152 X_f32_EOL_Front 1;
BA_ "GenSigSendType" SG_ 2654552151 IeTRSC_pct_TrlrRecogConf 1;
BA_ "GenSigSendType" SG_ 2654552151 IeTRSC_pct_TrlrTrackConf 1;
BA_ "GenSigStartValue" SG_ 2654552151 MeTRSC_m_HitchLength 100000;
BA_ "GenSigSendType" SG_ 2654552151 MeTRSC_m_HitchLength 1;
BA_ "GenSigSendType" SG_ 2654552151 IeTRSC_m_TrlrWhlBaseEff 1;
BA_ "GenSigSendType" SG_ 2654552151 IeTRSC_pct_TrlrDetConf 1;
BA_ "GenSigStartValue" SG_ 2654552151 MeTRSC_deg_JackKnifeAngle 5300;
BA_ "GenSigSendType" SG_ 2654552151 MeTRSC_deg_JackKnifeAngle 1;
BA_ "GenSigStartValue" SG_ 2654552151 MeTRSC_m_TrailerBeamLen 100;
BA_ "GenSigSendType" SG_ 2654552151 MeTRSC_m_TrailerBeamLen 1;
BA_ "GenSigSendType" SG_ 2654552151 MeTRSC_e_TrlrAngSign 1;
BA_ "GenSigSendType" SG_ 2654552151 MeTRSC_e_TrlrPrsntInfo 1;
BA_ "GenSigSendType" SG_ 2654552151 MeTRSC_e_TrlrRecogInfo 1;
BA_ "GenSigSendType" SG_ 2654552151 MeTRSC_e_TrlrCalInfo 1;
BA_ "GenSigSendType" SG_ 2654552151 MeSVS_b_MoreCamReqSts 1;
BA_ "GenSigStartValue" SG_ 2654552151 MeTRSC_deg_JackknifeThrAngle 530;
BA_ "GenSigSendType" SG_ 2654552151 MeTRSC_deg_JackknifeThrAngle 1;
BA_ "GenSigSendType" SG_ 2654552151 MeTRSC_deg_TADAngleRate 1;
BA_ "GenSigSendType" SG_ 2654552151 MeTRSC_deg_MaxAllowedTADAngle 1;
BA_ "GenSigStartValue" SG_ 2654552151 MeTRSC_e_TrailerID 6;
BA_ "GenSigSendType" SG_ 2654552151 MeTRSC_e_TrailerID 1;
BA_ "GenSigSendType" SG_ 2654552151 MeTRSC_e_CalFail 1;
BA_ "GenSigSendType" SG_ 2654552151 MeTRSC_e_TADCalibrationSubstate 1;
BA_ "GenSigSendType" SG_ 2654552151 MeTRSC_e_TurnAroundSubState 1;
BA_ "GenSigSendType" SG_ 2654552151 MeTRSC_e_TADState 1;
BA_ "GenSigSendType" SG_ 2654552151 MeTRSC_deg_TADAngle 1;
BA_ "GenSigSendType" SG_ 2654552150 LastViewBeforeTestPattern_e 1;
BA_ "GenSigSendType" SG_ 2654552150 Prev_DisplayedViewByAcore_e 1;
BA_ "GenSigSendType" SG_ 2654552150 Curr_DisplayedViewByAcore_e 1;
BA_ "GenSigSendType" SG_ 2654552150 Prev_RequestedViewByHmiM_e 1;
BA_ "GenSigSendType" SG_ 2654552150 Curr_RequestedViewByHmiM_e 1;
BA_ "GenSigSendType" SG_ 2654552150 Prev_SystemState_e 1;
BA_ "GenSigSendType" SG_ 2654552150 Curr_SystemState_e 1;
BA_ "GenSigSendType" SG_ 2654552150 M_FFClatch_e 1;
BA_ "GenSigSendType" SG_ 2654552150 M_BURV_Memory_e 1;
BA_ "GenSigSendType" SG_ 2654552150 FRONT_TOP_BTN_PRESSED_b 1;
BA_ "GenSigSendType" SG_ 2654552150 REAR_TOP_BTN_PRESSED_b 1;
BA_ "GenSigSendType" SG_ 2654552150 MAGNIFIER_BTN_PRESSED_b 1;
BA_ "GenSigSendType" SG_ 2654552150 X_BTN_PRESSED_b 1;
BA_ "GenSigSendType" SG_ 2654552150 OFFROAD_ABSNT_MC_BTN_PRESSED_b 1;
BA_ "GenSigSendType" SG_ 2654552150 OFFROAD_PRSNT_MC_BTN_PRESSED_b 1;
BA_ "GenSigSendType" SG_ 2654552150 OFFRD_ABSNT_AUXCAM_BTN_PRESSED_b 1;
BA_ "GenSigSendType" SG_ 2654552150 OFFRD_PRSNT_AUXCAM_BTN_PRESSED_b 1;
BA_ "GenSigSendType" SG_ 2654552150 RVCONLY_BTN_PRESSED_b 1;
BA_ "GenSigSendType" SG_ 2654552150 FFCV_BTN_PRESSED_b 1;
BA_ "GenSigSendType" SG_ 2654552150 FRONT_CROSS_BTN_PRESSED_b 1;
BA_ "GenSigSendType" SG_ 2654552150 REAR_CROSS_BTN_PRESSED_b 1;
BA_ "GenSigSendType" SG_ 2654552150 IgnoreVehicleOffSpeed 1;
BA_ "GenSigSendType" SG_ 2654552150 ZoomFactor_u8 1;
BA_ "GenSigSendType" SG_ 2654552149 tchScrnStatus_e 1;
BA_ "GenSigSendType" SG_ 2654552149 View_Error_e 1;
BA_ "GenSigSendType" SG_ 2654552149 DynOvl_Error_e 1;
BA_ "GenSigSendType" SG_ 2654552149 SoftBtn_Error_e 1;
BA_ "GenSigSendType" SG_ 2654552149 ImageDefeat_Error_e 1;
BA_ "GenSigSendType" SG_ 2654552149 tgwDispStatus_e 1;
BA_ "GenSigSendType" SG_ 2654552149 CameraDisplaySts2_e 1;
BA_ "GenSigSendType" SG_ 2654552149 prndStatus_e 1;
BA_ "GenSigSendType" SG_ 2654552149 transEquipped_e 1;
BA_ "GenSigSendType" SG_ 2654552149 ignitionStatus_e 1;
BA_ "GenSigSendType" SG_ 2654552149 trscStat_e 1;
BA_ "GenSigSendType" SG_ 2654552149 NetCfg_TRSCM_e 1;
BA_ "GenSigSendType" SG_ 2654552149 revGear_e 1;
BA_ "GenSigSendType" SG_ 2654552149 lrwsST_e 1;
BA_ "GenSigStartValue" SG_ 2654552149 GW_C_I6_timeout_b 1;
BA_ "GenSigSendType" SG_ 2654552149 GW_C_I6_timeout_b 1;
BA_ "GenSigStartValue" SG_ 2654552149 SVC_Delay_Feature_b 1;
BA_ "GenSigSendType" SG_ 2654552149 SVC_Delay_Feature_b 1;
BA_ "GenSigStartValue" SG_ 2654552149 SVC_FFCV_Gridlines_Feature_b 1;
BA_ "GenSigSendType" SG_ 2654552149 SVC_FFCV_Gridlines_Feature_b 1;
BA_ "GenSigStartValue" SG_ 2654552149 SVC_Static_Gridlines_Feature_b 1;
BA_ "GenSigSendType" SG_ 2654552149 SVC_Static_Gridlines_Feature_b 1;
BA_ "GenSigStartValue" SG_ 2654552149 SVC_Dynamic_Gridlines_Feature_b 1;
BA_ "GenSigSendType" SG_ 2654552149 SVC_Dynamic_Gridlines_Feature_b 1;
BA_ "GenSigStartValue" SG_ 2654552149 TopVideoBlanked_b 1;
BA_ "GenSigSendType" SG_ 2654552149 TopVideoBlanked_b 1;
BA_ "GenSigSendType" SG_ 2654552149 LanguageSelection_u8 1;
BA_ "GenSigSendType" SG_ 2654552149 vehicleLine_e 1;
BA_ "GenSigSendType" SG_ 2654552149 tchScrnCoord_s_Y_u16 1;
BA_ "GenSigSendType" SG_ 2654552149 tchScrnCoord_s_X_u16 1;
BA_ "GenSigSendType" SG_ 2654552149 CAM_NA_Bitfield_u8 1;
BA_ "GenSigSendType" SG_ 2654552149 vehicleSpeed_f32 1;
BA_ "GenSigSendType" SG_ 2654552149 steeringWheelAngle_f32 1;
BA_ "GenSigSendType" SG_ 2654552148 TrailerCalibrationStatus 1;
BA_ "GenSigSendType" SG_ 2654552148 TrscStatus 1;
BA_ "GenSigSendType" SG_ 2654552148 JackKnifeAngle 1;
BA_ "GenSigSendType" SG_ 2654552148 TrailerAngleSign 1;
BA_ "GenSigSendType" SG_ 2654552148 Prev_TRG_Stat 1;
BA_ "GenSigSendType" SG_ 2654552148 Curr_TRG_Stat 1;
BA_ "GenSigSendType" SG_ 2654552148 ItbmTrailerStatus 1;
BA_ "GenSigSendType" SG_ 2654552148 TrailerConnectionStatus 1;
BA_ "GenSigSendType" SG_ 2654552148 TrailerWheelBase 1;
BA_ "GenSigSendType" SG_ 2654552148 KnobAngle 1;
BA_ "GenSigSendType" SG_ 2654552148 MaxTadAngle 1;
BA_ "GenSigSendType" SG_ 2654552148 TadAngle 1;
BA_ "GenSigSendType" SG_ 2654552148 STM_v_TRGAUTO_BTN_PRESSED_b 1;
BA_ "GenSigSendType" SG_ 2654552148 STM_v_TRGRIGHT_BTN_PRESSED_b 1;
BA_ "GenSigSendType" SG_ 2654552148 STM_v_TRGLEFT_BTN_PRESSED_b 1;
BA_ "GenSigSendType" SG_ 2654552148 M_Progress_Bar_Percentage 1;
BA_ "GenSigSendType" SG_ 2654552148 M_Maneuver_Initial_Run 1;
BA_ "GenSigSendType" SG_ 2654552148 M_Progress_Bar_Distance 1;
BA_ "GenSigSendType" SG_ 2654552148 M_Cplr_Htch_Distance 1;
BA_ "GenSigSendType" SG_ 2654552148 M_CPLR_POS_Y_u 1;
BA_ "GenSigSendType" SG_ 2654552148 M_CPLR_POS_X_u 1;
BA_ "GenSigSendType" SG_ 2654552148 M_THA_SFT_BTN_PRESSED_b 1;
BA_ "GenSigSendType" SG_ 2654552148 M_START_BTN_PRESSED_b 1;
BA_ "GenSigSendType" SG_ 2654552148 M_CONFIRM_BTN_PRESSED_b 1;
BA_ "GenSigSendType" SG_ 2654552148 M_VIEW_SCRN_TCH_STS_b 1;
BA_ "GenSigSendType" SG_ 2654552148 M_VIEW_ZOOM_STS_b 1;
BA_ "GenSigSendType" SG_ 2654552148 M_Current_THA_State_On_Screen 1;
BA_ "GenSigSendType" SG_ 2654552148 M_Current_THA_State_On_Zync 1;
BA_ "GenSigSendType" SG_ 2654552148 M_Requested_THA_State 1;
BA_ "GenSigStartValue" SG_ 2654552147 MePRX_b_TRSCPresence 1;
BA_ "GenSigSendType" SG_ 2654552147 MePRX_b_TRSCPresence 1;
BA_ "GenSigStartValue" SG_ 2654552147 MePRX_b_TRGPresence 1;
BA_ "GenSigSendType" SG_ 2654552147 MePRX_b_TRGPresence 1;
BA_ "GenSigStartValue" SG_ 2654552147 MePRX_b_CanNode27 1;
BA_ "GenSigSendType" SG_ 2654552147 MePRX_b_CanNode27 1;
BA_ "GenSigStartValue" SG_ 2654552147 MePRX_b_CANNode95 1;
BA_ "GenSigSendType" SG_ 2654552147 MePRX_b_CANNode95 1;
BA_ "GenSigStartValue" SG_ 2654552147 MePRX_b_AuxTrlrCam 1;
BA_ "GenSigSendType" SG_ 2654552147 MePRX_b_AuxTrlrCam 1;
BA_ "GenSigStartValue" SG_ 2654552147 MePRX_b_FrwFacingCam 1;
BA_ "GenSigSendType" SG_ 2654552147 MePRX_b_FrwFacingCam 1;
BA_ "GenSigStartValue" SG_ 2654552147 MePRX_b_SurroundViewCamera 1;
BA_ "GenSigSendType" SG_ 2654552147 MePRX_b_SurroundViewCamera 1;
BA_ "GenSigSendType" SG_ 2654552147 MePRX_e_AutonomyLvl 1;
BA_ "GenSigSendType" SG_ 2654552147 MePRX_e_PAMTunSet 1;
BA_ "GenSigSendType" SG_ 2654552147 MePRX_e_MirrorType 1;
BA_ "GenSigSendType" SG_ 2654552147 MePRX_e_RadDispType 1;
BA_ "GenSigSendType" SG_ 2654552147 MePRX_e_SteerRatRackPinionType 1;
BA_ "GenSigSendType" SG_ 2654552147 MePRX_e_Wheelbase 1;
BA_ "GenSigSendType" SG_ 2654552147 MePRX_e_VehLineCfg 1;
BA_ "GenSigSendType" SG_ 2654552147 MePRX_e_VariantID 1;
BA_ "GenSigStartValue" SG_ 2654552146 MePRX_b_TRSCPresence 1;
BA_ "GenSigSendType" SG_ 2654552146 MePRX_b_TRSCPresence 1;
BA_ "GenSigStartValue" SG_ 2654552146 MePRX_b_TRGPresence 1;
BA_ "GenSigSendType" SG_ 2654552146 MePRX_b_TRGPresence 1;
BA_ "GenSigStartValue" SG_ 2654552146 MePRX_b_CanNode27 1;
BA_ "GenSigSendType" SG_ 2654552146 MePRX_b_CanNode27 1;
BA_ "GenSigStartValue" SG_ 2654552146 MePRX_b_CANNode95 1;
BA_ "GenSigSendType" SG_ 2654552146 MePRX_b_CANNode95 1;
BA_ "GenSigStartValue" SG_ 2654552146 MePRX_b_AuxTrlrCam 1;
BA_ "GenSigSendType" SG_ 2654552146 MePRX_b_AuxTrlrCam 1;
BA_ "GenSigStartValue" SG_ 2654552146 MePRX_b_FrwFacingCam 1;
BA_ "GenSigSendType" SG_ 2654552146 MePRX_b_FrwFacingCam 1;
BA_ "GenSigStartValue" SG_ 2654552146 MePRX_b_SurroundViewCamera 1;
BA_ "GenSigSendType" SG_ 2654552146 MePRX_b_SurroundViewCamera 1;
BA_ "GenSigSendType" SG_ 2654552146 MePRX_e_AutonomyLvl 1;
BA_ "GenSigSendType" SG_ 2654552146 MePRX_e_PAMTunSet 1;
BA_ "GenSigSendType" SG_ 2654552146 MePRX_e_MirrorType 1;
BA_ "GenSigSendType" SG_ 2654552146 MePRX_e_RadDispType 1;
BA_ "GenSigSendType" SG_ 2654552146 MePRX_e_SteerRatRackPinionType 1;
BA_ "GenSigSendType" SG_ 2654552146 MePRX_e_Wheelbase 1;
BA_ "GenSigSendType" SG_ 2654552146 MePRX_e_VehLineCfg 1;
BA_ "GenSigSendType" SG_ 2654552146 MePRX_e_VariantID 1;
BA_ "GenSigSendType" SG_ 2654552145 Frameset1AndTopFrontText_b 1;
BA_ "GenSigSendType" SG_ 2654552145 Frameset1AndTopRearText_b 1;
BA_ "GenSigSendType" SG_ 2654552145 Frameset2AndFrontCrossText_b 1;
BA_ "GenSigSendType" SG_ 2654552145 Frameset2AndRearCrossText_b 1;
BA_ "GenSigSendType" SG_ 2654552145 MoreCamsIconFullScreenNoSelect_b 1;
BA_ "GenSigSendType" SG_ 2654552145 TopRearButtonNoSelect_b 1;
BA_ "GenSigSendType" SG_ 2654552145 TopRearButtonSelect_b 1;
BA_ "GenSigSendType" SG_ 2654552145 RearCrossButtonNoSelect_b 1;
BA_ "GenSigSendType" SG_ 2654552145 RearCrossButtonSelect_b 1;
BA_ "GenSigSendType" SG_ 2654552145 FrontCrossButtonNoSelect_b 1;
BA_ "GenSigSendType" SG_ 2654552145 FrontCrossButtonSelect_b 1;
BA_ "GenSigSendType" SG_ 2654552145 TopFrontButtonSelect_b 1;
BA_ "GenSigSendType" SG_ 2654552145 TopFrontButtonNoSelect_b 1;
BA_ "GenSigSendType" SG_ 2654552145 BackupRearCamButtonSelect_b 1;
BA_ "GenSigSendType" SG_ 2654552145 BackupRearCamButtonNoSelect_b 1;
BA_ "GenSigSendType" SG_ 2654552145 FrontFaceCamButtonSelect_b 1;
BA_ "GenSigSendType" SG_ 2654552145 FrontFaceCamButtonNoSelect_b 1;
BA_ "GenSigSendType" SG_ 2654552145 FrontTireTracks_b 1;
BA_ "GenSigSendType" SG_ 2654552145 AuxCamButton1Select_b 1;
BA_ "GenSigSendType" SG_ 2654552145 AuxCamButton1NoSelect_b 1;
BA_ "GenSigSendType" SG_ 2654552145 AuxCamButton2Select_b 1;
BA_ "GenSigSendType" SG_ 2654552145 AuxCamButton2NoSelect_b 1;
BA_ "GenSigSendType" SG_ 2654552145 MoreCamsButton1Select_b 1;
BA_ "GenSigSendType" SG_ 2654552145 MoreCamsButton1NoSelect_b 1;
BA_ "GenSigSendType" SG_ 2654552145 MoreCamsButton2Select_b 1;
BA_ "GenSigSendType" SG_ 2654552145 MoreCamsButton2NoSelect_b 1;
BA_ "GenSigSendType" SG_ 2654552145 RearViewDynamics_b 1;
BA_ "GenSigSendType" SG_ 2654552145 TopViewRearDynamics_b 1;
BA_ "GenSigSendType" SG_ 2654552145 FrontViewDynamics_b 1;
BA_ "GenSigSendType" SG_ 2654552145 TopViewFrontDynamics_b 1;
BA_ "GenSigSendType" SG_ 2654552145 XIcon_b 1;
BA_ "GenSigSendType" SG_ 2654552145 ZoomButtonDisable_b 1;
BA_ "GenSigSendType" SG_ 2654552145 ZoomMinusIcon_b 1;
BA_ "GenSigSendType" SG_ 2654552145 ZoomPlusIcon_b 1;
BA_ "GenSigSendType" SG_ 2654552145 LeftDoorFrontOpen_Icon_b 1;
BA_ "GenSigSendType" SG_ 2654552145 LeftDoorRearOpen_Icon_b 1;
BA_ "GenSigSendType" SG_ 2654552145 RightDoorFrontOpen_Icon_b 1;
BA_ "GenSigSendType" SG_ 2654552145 RightDoorRearOpen_Icon_b 1;
BA_ "GenSigSendType" SG_ 2654552145 BackDoorOpen_Icon_b 1;
BA_ "GenSigSendType" SG_ 2654552145 FrontCam_NA_b 1;
BA_ "GenSigSendType" SG_ 2654552145 LeftCam_NA_b 1;
BA_ "GenSigSendType" SG_ 2654552145 BackCam_NA_b 1;
BA_ "GenSigSendType" SG_ 2654552145 RightCam_NA_b 1;
BA_ "GenSigSendType" SG_ 2654552145 TopViewBlack_b 1;
BA_ "GenSigSendType" SG_ 2654552145 LeftDoorFrontClose_Icon_b 1;
BA_ "GenSigSendType" SG_ 2654552145 LeftDoorRearClose_Icon_b 1;
BA_ "GenSigSendType" SG_ 2654552145 RightDoorFrontClose_Icon_b 1;
BA_ "GenSigSendType" SG_ 2654552145 RightDoorRearClose_Icon_b 1;
BA_ "GenSigSendType" SG_ 2654552145 Reserved13_b 1;
BA_ "GenSigSendType" SG_ 2654552145 PDC_RearCenter_Yellow_b 1;
BA_ "GenSigSendType" SG_ 2654552145 PDC_RearCenter_Red_b 1;
BA_ "GenSigSendType" SG_ 2654552145 Reserved12_b 1;
BA_ "GenSigSendType" SG_ 2654552145 PDC_RearRight_Yellow_b 1;
BA_ "GenSigSendType" SG_ 2654552145 PDC_RearRight_Red_b 1;
BA_ "GenSigSendType" SG_ 2654552145 Reserved11_b 1;
BA_ "GenSigSendType" SG_ 2654552145 PDC_FrontLeft_Yellow_b 1;
BA_ "GenSigSendType" SG_ 2654552145 PDC_FrontLeft_Red_b 1;
BA_ "GenSigSendType" SG_ 2654552145 Reserved10_b 1;
BA_ "GenSigSendType" SG_ 2654552145 PDC_FrontCenter_Yellow_b 1;
BA_ "GenSigSendType" SG_ 2654552145 PDC_FrontCenter_Red_b 1;
BA_ "GenSigSendType" SG_ 2654552145 Reserved09_b 1;
BA_ "GenSigSendType" SG_ 2654552145 PDC_FrontRight_Yellow_b 1;
BA_ "GenSigSendType" SG_ 2654552145 PDC_FrontRight_Red_b 1;
BA_ "GenSigSendType" SG_ 2654552145 Reserved08_b 1;
BA_ "GenSigSendType" SG_ 2654552145 PDC_RearLeft_Yellow_b 1;
BA_ "GenSigSendType" SG_ 2654552145 PDC_RearLeft_Red_b 1;
BA_ "GenSigSendType" SG_ 2654552145 SrvLayout_b 1;
BA_ "GenSigSendType" SG_ 2654552145 SrvStAngIndOk_b 1;
BA_ "GenSigSendType" SG_ 2654552145 SrvStAngIndNok_b 1;
BA_ "GenSigSendType" SG_ 2654552145 SrvSpOmIndOk_b 1;
BA_ "GenSigSendType" SG_ 2654552145 SrvSpOmIndNok_b 1;
BA_ "GenSigSendType" SG_ 2654552145 SrvChkIndRun_b 1;
BA_ "GenSigSendType" SG_ 2654552145 SrvChkIndOk_b 1;
BA_ "GenSigSendType" SG_ 2654552145 SrvChkIndNok_b 1;
BA_ "GenSigSendType" SG_ 2654552145 SrvChkIndCondNok_b 1;
BA_ "GenSigSendType" SG_ 2654552145 SrvCamIndFrOk_b 1;
BA_ "GenSigSendType" SG_ 2654552145 SrvCamIndFrNok_b 1;
BA_ "GenSigSendType" SG_ 2654552145 SrvCamIndFrPend_b 1;
BA_ "GenSigSendType" SG_ 2654552145 SrvCamIndFrNone_b 1;
BA_ "GenSigSendType" SG_ 2654552145 SrvCamIndLeOk_b 1;
BA_ "GenSigSendType" SG_ 2654552145 SrvCamIndLeNok_b 1;
BA_ "GenSigSendType" SG_ 2654552145 SrvCamIndLePend_b 1;
BA_ "GenSigSendType" SG_ 2654552145 SrvCamIndLeNone_b 1;
BA_ "GenSigSendType" SG_ 2654552145 SrvCamIndBaOk_b 1;
BA_ "GenSigSendType" SG_ 2654552145 SrvCamIndBaNok_b 1;
BA_ "GenSigSendType" SG_ 2654552145 SrvCamIndBaPend_b 1;
BA_ "GenSigSendType" SG_ 2654552145 SrvCamIndBaNone_b 1;
BA_ "GenSigSendType" SG_ 2654552145 SrvCamIndRiOk_b 1;
BA_ "GenSigSendType" SG_ 2654552145 SrvCamIndRiNok_b 1;
BA_ "GenSigSendType" SG_ 2654552145 SrvCamIndRiPend_b 1;
BA_ "GenSigSendType" SG_ 2654552145 SrvCamIndRiNone_b 1;
BA_ "GenSigSendType" SG_ 2654552145 SrvPrgBar0Per_b 1;
BA_ "GenSigSendType" SG_ 2654552145 SrvPrgBar20Per_b 1;
BA_ "GenSigSendType" SG_ 2654552145 SrvPrgBar40Per_b 1;
BA_ "GenSigSendType" SG_ 2654552145 SrvPrgBar60Per_b 1;
BA_ "GenSigSendType" SG_ 2654552145 SrvPrgBar80Per_b 1;
BA_ "GenSigSendType" SG_ 2654552145 SrvPrgBar100Per_b 1;
BA_ "GenSigSendType" SG_ 2654552145 TrscOvl 1;
BA_ "GenSigSendType" SG_ 2654552145 TrscJackKnifeOrange 1;
BA_ "GenSigSendType" SG_ 2654552145 TrscJackKnifeRed 1;
BA_ "GenSigSendType" SG_ 2654552145 TrscTrailerRed 1;
BA_ "GenSigSendType" SG_ 2654552145 THATriangleOverlay 1;
BA_ "GenSigSendType" SG_ 2654552145 THACouplerBulletIcon 1;
BA_ "GenSigSendType" SG_ 2654552145 THAButtonGrey 1;
BA_ "GenSigSendType" SG_ 2654552145 THAButtonSelectable 1;
BA_ "GenSigSendType" SG_ 2654552145 THAConfirmButton 1;
BA_ "GenSigSendType" SG_ 2654552145 THAStartButton 1;
BA_ "GenSigSendType" SG_ 2654552145 THAProgressBar 1;
BA_ "GenSigSendType" SG_ 2654552145 Reserved3_b 1;
BA_ "GenSigSendType" SG_ 2654552145 Reserved2_b 1;
BA_ "GenSigSendType" SG_ 2654552145 Reserved1_b 1;
BA_ "GenSigSendType" SG_ 2654552145 Reserved0_b 1;
BA_ "GenSigSendType" SG_ 2654552144 Frameset1AndTopFrontText_b 1;
BA_ "GenSigSendType" SG_ 2654552144 Frameset1AndTopRearText_b 1;
BA_ "GenSigSendType" SG_ 2654552144 Frameset2AndFrontCrossText_b 1;
BA_ "GenSigSendType" SG_ 2654552144 Frameset2AndRearCrossText_b 1;
BA_ "GenSigSendType" SG_ 2654552144 MoreCamsIconFullScreenNoSelect_b 1;
BA_ "GenSigSendType" SG_ 2654552144 TopRearButtonNoSelect_b 1;
BA_ "GenSigSendType" SG_ 2654552144 TopRearButtonSelect_b 1;
BA_ "GenSigSendType" SG_ 2654552144 RearCrossButtonNoSelect_b 1;
BA_ "GenSigSendType" SG_ 2654552144 RearCrossButtonSelect_b 1;
BA_ "GenSigSendType" SG_ 2654552144 FrontCrossButtonNoSelect_b 1;
BA_ "GenSigSendType" SG_ 2654552144 FrontCrossButtonSelect_b 1;
BA_ "GenSigSendType" SG_ 2654552144 TopFrontButtonSelect_b 1;
BA_ "GenSigSendType" SG_ 2654552144 TopFrontButtonNoSelect_b 1;
BA_ "GenSigSendType" SG_ 2654552144 BackupRearCamButtonSelect_b 1;
BA_ "GenSigSendType" SG_ 2654552144 BackupRearCamButtonNoSelect_b 1;
BA_ "GenSigSendType" SG_ 2654552144 FrontFaceCamButtonSelect_b 1;
BA_ "GenSigSendType" SG_ 2654552144 FrontFaceCamButtonNoSelect_b 1;
BA_ "GenSigSendType" SG_ 2654552144 FrontTireTracks_b 1;
BA_ "GenSigSendType" SG_ 2654552144 AuxCamButton1Select_b 1;
BA_ "GenSigSendType" SG_ 2654552144 AuxCamButton1NoSelect_b 1;
BA_ "GenSigSendType" SG_ 2654552144 AuxCamButton2Select_b 1;
BA_ "GenSigSendType" SG_ 2654552144 AuxCamButton2NoSelect_b 1;
BA_ "GenSigSendType" SG_ 2654552144 MoreCamsButton1Select_b 1;
BA_ "GenSigSendType" SG_ 2654552144 MoreCamsButton1NoSelect_b 1;
BA_ "GenSigSendType" SG_ 2654552144 MoreCamsButton2Select_b 1;
BA_ "GenSigSendType" SG_ 2654552144 MoreCamsButton2NoSelect_b 1;
BA_ "GenSigSendType" SG_ 2654552144 RearViewDynamics_b 1;
BA_ "GenSigSendType" SG_ 2654552144 TopViewRearDynamics_b 1;
BA_ "GenSigSendType" SG_ 2654552144 FrontViewDynamics_b 1;
BA_ "GenSigSendType" SG_ 2654552144 TopViewFrontDynamics_b 1;
BA_ "GenSigSendType" SG_ 2654552144 XIcon_b 1;
BA_ "GenSigSendType" SG_ 2654552144 ZoomButtonDisable_b 1;
BA_ "GenSigSendType" SG_ 2654552144 ZoomMinusIcon_b 1;
BA_ "GenSigSendType" SG_ 2654552144 ZoomPlusIcon_b 1;
BA_ "GenSigSendType" SG_ 2654552144 LeftDoorFrontOpen_Icon_b 1;
BA_ "GenSigSendType" SG_ 2654552144 LeftDoorRearOpen_Icon_b 1;
BA_ "GenSigSendType" SG_ 2654552144 RightDoorFrontOpen_Icon_b 1;
BA_ "GenSigSendType" SG_ 2654552144 RightDoorRearOpen_Icon_b 1;
BA_ "GenSigSendType" SG_ 2654552144 BackDoorOpen_Icon_b 1;
BA_ "GenSigSendType" SG_ 2654552144 FrontCam_NA_b 1;
BA_ "GenSigSendType" SG_ 2654552144 LeftCam_NA_b 1;
BA_ "GenSigSendType" SG_ 2654552144 BackCam_NA_b 1;
BA_ "GenSigSendType" SG_ 2654552144 RightCam_NA_b 1;
BA_ "GenSigSendType" SG_ 2654552144 TopViewBlack_b 1;
BA_ "GenSigSendType" SG_ 2654552144 LeftDoorFrontClose_Icon_b 1;
BA_ "GenSigSendType" SG_ 2654552144 LeftDoorRearClose_Icon_b 1;
BA_ "GenSigSendType" SG_ 2654552144 RightDoorFrontClose_Icon_b 1;
BA_ "GenSigSendType" SG_ 2654552144 RightDoorRearClose_Icon_b 1;
BA_ "GenSigSendType" SG_ 2654552144 Reserved13_b 1;
BA_ "GenSigSendType" SG_ 2654552144 PDC_RearCenter_Yellow_b 1;
BA_ "GenSigSendType" SG_ 2654552144 PDC_RearCenter_Red_b 1;
BA_ "GenSigSendType" SG_ 2654552144 Reserved12_b 1;
BA_ "GenSigSendType" SG_ 2654552144 PDC_RearRight_Yellow_b 1;
BA_ "GenSigSendType" SG_ 2654552144 PDC_RearRight_Red_b 1;
BA_ "GenSigSendType" SG_ 2654552144 Reserved11_b 1;
BA_ "GenSigSendType" SG_ 2654552144 PDC_FrontLeft_Yellow_b 1;
BA_ "GenSigSendType" SG_ 2654552144 PDC_FrontLeft_Red_b 1;
BA_ "GenSigSendType" SG_ 2654552144 Reserved10_b 1;
BA_ "GenSigSendType" SG_ 2654552144 PDC_FrontCenter_Yellow_b 1;
BA_ "GenSigSendType" SG_ 2654552144 PDC_FrontCenter_Red_b 1;
BA_ "GenSigSendType" SG_ 2654552144 Reserved09_b 1;
BA_ "GenSigSendType" SG_ 2654552144 PDC_FrontRight_Yellow_b 1;
BA_ "GenSigSendType" SG_ 2654552144 PDC_FrontRight_Red_b 1;
BA_ "GenSigSendType" SG_ 2654552144 Reserved08_b 1;
BA_ "GenSigSendType" SG_ 2654552144 PDC_RearLeft_Yellow_b 1;
BA_ "GenSigSendType" SG_ 2654552144 PDC_RearLeft_Red_b 1;
BA_ "GenSigSendType" SG_ 2654552144 SrvLayout_b 1;
BA_ "GenSigSendType" SG_ 2654552144 SrvStAngIndOk_b 1;
BA_ "GenSigSendType" SG_ 2654552144 SrvStAngIndNok_b 1;
BA_ "GenSigSendType" SG_ 2654552144 SrvSpOmIndOk_b 1;
BA_ "GenSigSendType" SG_ 2654552144 SrvSpOmIndNok_b 1;
BA_ "GenSigSendType" SG_ 2654552144 SrvChkIndRun_b 1;
BA_ "GenSigSendType" SG_ 2654552144 SrvChkIndOk_b 1;
BA_ "GenSigSendType" SG_ 2654552144 SrvChkIndNok_b 1;
BA_ "GenSigSendType" SG_ 2654552144 SrvChkIndCondNok_b 1;
BA_ "GenSigSendType" SG_ 2654552144 SrvCamIndFrOk_b 1;
BA_ "GenSigSendType" SG_ 2654552144 SrvCamIndFrNok_b 1;
BA_ "GenSigSendType" SG_ 2654552144 SrvCamIndFrPend_b 1;
BA_ "GenSigSendType" SG_ 2654552144 SrvCamIndFrNone_b 1;
BA_ "GenSigSendType" SG_ 2654552144 SrvCamIndLeOk_b 1;
BA_ "GenSigSendType" SG_ 2654552144 SrvCamIndLeNok_b 1;
BA_ "GenSigSendType" SG_ 2654552144 SrvCamIndLePend_b 1;
BA_ "GenSigSendType" SG_ 2654552144 SrvCamIndLeNone_b 1;
BA_ "GenSigSendType" SG_ 2654552144 SrvCamIndBaOk_b 1;
BA_ "GenSigSendType" SG_ 2654552144 SrvCamIndBaNok_b 1;
BA_ "GenSigSendType" SG_ 2654552144 SrvCamIndBaPend_b 1;
BA_ "GenSigSendType" SG_ 2654552144 SrvCamIndBaNone_b 1;
BA_ "GenSigSendType" SG_ 2654552144 SrvCamIndRiOk_b 1;
BA_ "GenSigSendType" SG_ 2654552144 SrvCamIndRiNok_b 1;
BA_ "GenSigSendType" SG_ 2654552144 SrvCamIndRiPend_b 1;
BA_ "GenSigSendType" SG_ 2654552144 SrvCamIndRiNone_b 1;
BA_ "GenSigSendType" SG_ 2654552144 SrvPrgBar0Per_b 1;
BA_ "GenSigSendType" SG_ 2654552144 SrvPrgBar20Per_b 1;
BA_ "GenSigSendType" SG_ 2654552144 SrvPrgBar40Per_b 1;
BA_ "GenSigSendType" SG_ 2654552144 SrvPrgBar60Per_b 1;
BA_ "GenSigSendType" SG_ 2654552144 SrvPrgBar80Per_b 1;
BA_ "GenSigSendType" SG_ 2654552144 SrvPrgBar100Per_b 1;
BA_ "GenSigSendType" SG_ 2654552144 TrscOvl 1;
BA_ "GenSigSendType" SG_ 2654552144 TrscJackKnifeOrange 1;
BA_ "GenSigSendType" SG_ 2654552144 TrscJackKnifeRed 1;
BA_ "GenSigSendType" SG_ 2654552144 TrscTrailerRed 1;
BA_ "GenSigSendType" SG_ 2654552144 THATriangleOverlay 1;
BA_ "GenSigSendType" SG_ 2654552144 THACouplerBulletIcon 1;
BA_ "GenSigSendType" SG_ 2654552144 THAButtonGrey 1;
BA_ "GenSigSendType" SG_ 2654552144 THAButtonSelectable 1;
BA_ "GenSigSendType" SG_ 2654552144 THAConfirmButton 1;
BA_ "GenSigSendType" SG_ 2654552144 THAStartButton 1;
BA_ "GenSigSendType" SG_ 2654552144 THAProgressBar 1;
BA_ "GenSigSendType" SG_ 2654552144 Reserved3_b 1;
BA_ "GenSigSendType" SG_ 2654552144 Reserved2_b 1;
BA_ "GenSigSendType" SG_ 2654552144 Reserved1_b 1;
BA_ "GenSigSendType" SG_ 2654552144 Reserved0_b 1;
BA_ "GenSigSendType" SG_ 2654814240 Debug_Signal_6 1;
BA_ "GenSigSendType" SG_ 2654814240 Debug_Signal_8 1;
BA_ "GenSigSendType" SG_ 2654814240 Debug_Signal_7 1;
BA_ "GenSigSendType" SG_ 2654814240 Debug_Signal_5 1;
BA_ "GenSigSendType" SG_ 2654814238 Debug_Signal_4 1;
BA_ "GenSigSendType" SG_ 2654814238 Debug_Signal_3 1;
BA_ "GenSigSendType" SG_ 2654814238 Debug_Signal_2 1;
BA_ "GenSigSendType" SG_ 2654814238 Debug_Signal_1 1;
BA_ "GenSigSendType" SG_ 2654814241 Snr_EEPROM_Fail 1;
BA_ "GenSigSendType" SG_ 2654814241 Snr_High_Voltage 1;
BA_ "GenSigSendType" SG_ 2654814241 Snr_Low_Voltage 1;
BA_ "GenSigSendType" SG_ 2654814241 Snr_RAM_Fail 1;
BA_ "GenSigSendType" SG_ 2654814242 Disturbance_Detected 1;
BA_ "GenSigSendType" SG_ 2654814242 FW_Inconsistant_Snr 1;
BA_ "GenSigSendType" SG_ 2654814242 ECU_EEPROM_Fail 1;
BA_ "GenSigSendType" SG_ 2654814242 ECU_Low_Voltage 1;
BA_ "GenSigSendType" SG_ 2654814242 ECU_High_Voltage 1;
BA_ "GenSigSendType" SG_ 2654814242 Comm_Snr_Error 1;
BA_ "GenSigSendType" SG_ 2654814242 Snr_Transducer_Error 1;
BA_ "GenSigSendType" SG_ 2654814242 Snr_Abnormal 1;
BA_ "GenSigSendType" SG_ 2654814242 Snr_Blockage 1;
BA_ "GenSigSendType" SG_ 2654814242 Snr_Disconnect 1;
BA_ "GenSigSendType" SG_ 2654814243 TimeStamp_SystemStatus 1;
BA_ "GenSigSendType" SG_ 2654814243 SystemMode 1;
BA_ "GenSigSendType" SG_ 2654814243 SystemStatus 1;
BA_ "GenSigSendType" SG_ 2654814243 BumberStatus_Right_Side 1;
BA_ "GenSigSendType" SG_ 2654814243 BumberStatus_Left_Side 1;
BA_ "GenSigSendType" SG_ 2654814243 BumberStatus_Rear 1;
BA_ "GenSigSendType" SG_ 2654814243 BumberStatus_Front 1;
BA_ "GenSigSendType" SG_ 2654552136 UssParkingModeSignal 1;
BA_ "GenSigSendType" SG_ 2654814246 Tstr_SD_0_SystemStatus_Msg2 1;
BA_ "GenSigSendType" SG_ 2654814246 Tstr_SD_1_SensorBlkgClrCounter 1;
BA_ "GenSigSendType" SG_ 2654814246 Tstr_SD_2_SensorBlkgClrCounter 1;
BA_ "GenSigSendType" SG_ 2654814246 Tstr_SD_3_SensorBlkgClrCounter 1;
BA_ "GenSigSendType" SG_ 2654814246 Tstr_SD_4_SensorBlkgClrCounter 1;
BA_ "GenSigSendType" SG_ 2654814246 Tstr_SD_5_SensorBlkgClrCounter 1;
BA_ "GenSigSendType" SG_ 2654814246 Tstr_SD_6_SensorBlkgClrCounter 1;
BA_ "GenSigSendType" SG_ 2654814246 Tstr_SD_7_SensorBlkgClrCounter 1;
BA_ "GenSigSendType" SG_ 2654814246 Tstr_SD_8_SensorBlkgClrCounter 1;
BA_ "GenSigSendType" SG_ 2654814246 Tstr_SD_9_SensorBlkgClrCounter 1;
BA_ "GenSigSendType" SG_ 2654814246 Tstr_SD_10_SensorBlkgClrCounter 1;
BA_ "GenSigSendType" SG_ 2654814246 Tstr_SD_11_SensorBlkgClrCounter 1;
BA_ "GenSigSendType" SG_ 2654814246 Tstr_SD_12_SensorBlkgClrCounter 1;
BA_ "GenSigSendType" SG_ 2654814246 Tstr_SD_13_SensorBlkgClrCounter 1;
BA_ "GenSigSendType" SG_ 2654814246 Tstr_SD_14_SensorBlkgClrCounter 1;
BA_ "GenSigSendType" SG_ 2654814246 Tstr_SD_15_SensorBlkgClrCounter 1;
BA_ "GenSigSendType" SG_ 2654814246 Tstr_SD_16_SensorBlkgClrCounter 1;
BA_ "GenSigSendType" SG_ 2654814246 Tstr_SD_1_SensorBlkgSetCounter 1;
BA_ "GenSigSendType" SG_ 2654814246 Tstr_SD_2_SensorBlkgSetCounter 1;
BA_ "GenSigSendType" SG_ 2654814246 Tstr_SD_3_SensorBlkgSetCounter 1;
BA_ "GenSigSendType" SG_ 2654814246 Tstr_SD_4_SensorBlkgSetCounter 1;
BA_ "GenSigSendType" SG_ 2654814246 Tstr_SD_5_SensorBlkgSetCounter 1;
BA_ "GenSigSendType" SG_ 2654814246 Tstr_SD_6_SensorBlkgSetCounter 1;
BA_ "GenSigSendType" SG_ 2654814246 Tstr_SD_7_SensorBlkgSetCounter 1;
BA_ "GenSigSendType" SG_ 2654814246 Tstr_SD_8_SensorBlkgSetCounter 1;
BA_ "GenSigSendType" SG_ 2654814246 Tstr_SD_9_SensorBlkgSetCounter 1;
BA_ "GenSigSendType" SG_ 2654814246 Tstr_SD_10_SensorBlkgSetCounter 1;
BA_ "GenSigSendType" SG_ 2654814246 Tstr_SD_11_SensorBlkgSetCounter 1;
BA_ "GenSigSendType" SG_ 2654814246 Tstr_SD_12_SensorBlkgSetCounter 1;
BA_ "GenSigSendType" SG_ 2654814246 Tstr_SD_13_SensorBlkgSetCounter 1;
BA_ "GenSigSendType" SG_ 2654814246 Tstr_SD_14_SensorBlkgSetCounter 1;
BA_ "GenSigSendType" SG_ 2654814246 Tstr_SD_15_SensorBlkgSetCounter 1;
BA_ "GenSigSendType" SG_ 2654814246 Tstr_SD_16_SensorBlkgSetCounter 1;
BA_ "GenSigSendType" SG_ 2654814246 Tstr_SD_16_SensorID 1;
BA_ "GenSigSendType" SG_ 2654814246 Tstr_SD_15_SensorID 1;
BA_ "GenSigSendType" SG_ 2654814246 Tstr_SD_14_SensorID 1;
BA_ "GenSigSendType" SG_ 2654814246 Tstr_SD_13_SensorID 1;
BA_ "GenSigSendType" SG_ 2654814246 Tstr_SD_1_SensorID 1;
BA_ "GenSigSendType" SG_ 2654814246 Tstr_SD_2_SensorID 1;
BA_ "GenSigSendType" SG_ 2654814246 Tstr_SD_3_SensorID 1;
BA_ "GenSigSendType" SG_ 2654814246 Tstr_SD_4_SensorID 1;
BA_ "GenSigSendType" SG_ 2654814246 Tstr_SD_5_SensorID 1;
BA_ "GenSigSendType" SG_ 2654814246 Tstr_SD_6_SensorID 1;
BA_ "GenSigSendType" SG_ 2654814246 Tstr_SD_7_SensorID 1;
BA_ "GenSigSendType" SG_ 2654814246 Tstr_SD_8_SensorID 1;
BA_ "GenSigSendType" SG_ 2654814246 Tstr_SD_9_SensorID 1;
BA_ "GenSigSendType" SG_ 2654814246 Tstr_SD_10_SensorID 1;
BA_ "GenSigSendType" SG_ 2654814246 Tstr_SD_11_SensorID 1;
BA_ "GenSigSendType" SG_ 2654814246 Tstr_SD_12_SensorID 1;
BA_ "GenSigSendType" SG_ 2654814246 Tstr_SD_16_SensorTemperature 1;
BA_ "GenSigSendType" SG_ 2654814246 Tstr_SD_15_SensorTemperature 1;
BA_ "GenSigSendType" SG_ 2654814246 Tstr_SD_14_SensorTemperature 1;
BA_ "GenSigSendType" SG_ 2654814246 Tstr_SD_13_SensorTemperature 1;
BA_ "GenSigSendType" SG_ 2654814246 Tstr_SD_7_SensorTemperature 1;
BA_ "GenSigSendType" SG_ 2654814246 Tstr_SD_1_SensorTemperature 1;
BA_ "GenSigSendType" SG_ 2654814246 Tstr_SD_2_SensorTemperature 1;
BA_ "GenSigSendType" SG_ 2654814246 Tstr_SD_3_SensorTemperature 1;
BA_ "GenSigSendType" SG_ 2654814246 Tstr_SD_4_SensorTemperature 1;
BA_ "GenSigSendType" SG_ 2654814246 Tstr_SD_5_SensorTemperature 1;
BA_ "GenSigSendType" SG_ 2654814246 Tstr_SD_6_SensorTemperature 1;
BA_ "GenSigSendType" SG_ 2654814246 Tstr_SD_8_SensorTemperature 1;
BA_ "GenSigSendType" SG_ 2654814246 Tstr_SD_9_SensorTemperature 1;
BA_ "GenSigSendType" SG_ 2654814246 Tstr_SD_10_SensorTemperature 1;
BA_ "GenSigSendType" SG_ 2654814246 Tstr_SD_11_SensorTemperature 1;
BA_ "GenSigSendType" SG_ 2654814246 Tstr_SD_12_SensorTemperature 1;
BA_ "GenSigSendType" SG_ 2654814246 Tstr_SD_DataIndex_Msg2 1;
VAL_ 2654814208 BOR_Blockage 3 "SNA" 2 "Not_Active_failure" 1 "Not_Active_blocked" 0 "Active" ;
VAL_ 2654814208 AOR_Blockage 3 "SNA" 2 "Not_Active_failure" 1 "Not_Active_blocked" 0 "Active" ;
VAL_ 2654814208 BOL_Blockage 3 "SNA" 2 "Not_Active_failure" 1 "Not_Active_blocked" 0 "Active" ;
VAL_ 2654814208 AOL_Blockage 3 "SNA" 2 "Not_Active_failure" 1 "Not_Active_blocked" 0 "Active" ;
VAL_ 2654814208 RSL_Blockage 3 "SNA" 2 "Not_Active_failure" 1 "Not_Active_blocked" 0 "Active" ;
VAL_ 2654814208 ROL_Blockage 3 "SNA" 2 "Not_Active_failure" 1 "Not_Active_blocked" 0 "Active" ;
VAL_ 2654814208 RIL_Blockage 3 "SNA" 2 "Not_Active_failure" 1 "Not_Active_blocked" 0 "Active" ;
VAL_ 2654814208 RIR_Blockage 3 "SNA" 2 "Not_Active_failure" 1 "Not_Active_blocked" 0 "Active" ;
VAL_ 2654814208 ROR_Blockage 3 "SNA" 2 "Not_Active_failure" 1 "Not_Active_blocked" 0 "Active" ;
VAL_ 2654814208 RSR_Blockage 3 "SNA" 2 "Not_Active_failure" 1 "Not_Active_blocked" 0 "Active" ;
VAL_ 2654814208 FSL_Blockage 3 "SNA" 2 "Not_Active_failure" 1 "Not_Active_blocked" 0 "Active" ;
VAL_ 2654814208 FOL_Blockage 3 "SNA" 2 "Not_Active_failure" 1 "Not_Active_blocked" 0 "Active" ;
VAL_ 2654814208 FIL_Blockage 3 "SNA" 2 "Not_Active_failure" 1 "Not_Active_blocked" 0 "Active" ;
VAL_ 2654814208 FIR_Blockage 3 "SNA" 2 "Not_Active_failure" 1 "Not_Active_blocked" 0 "Active" ;
VAL_ 2654814208 FOR_Blockage 3 "SNA" 2 "Not_Active_failure" 1 "Not_Active_blocked" 0 "Active" ;
VAL_ 2654814208 FSR_Blockage 3 "SNA" 2 "Not_Active_failure" 1 "Not_Active_blocked" 0 "Active" ;
VAL_ 2654552193 objConf_e 3 "Conf_High" 2 "Conf_Med" 1 "Conf_Low" 0 "Conf_None" ;
VAL_ 2654552193 FrontSensorDetHealth_e 3 "SNA" 2 "Not_Active_failure" 1 "Not_Active_blocked" 0 "Active" ;
VAL_ 2654552178 perpParkDirectionSel 2 "Front_In" 1 "Rear_In" 0 "None" ;
VAL_ 2654552178 parkExtSideSel 2 "Right" 1 "Left" 0 "None" ;
VAL_ 2654552178 slotSide 2 "SLOT_RIGHT" 1 "SLOT_LEFT" 0 "SLOT_NULL" ;
VAL_ 2654552178 parkingDirection 2 "REAR_IN_OUT" 1 "FRONT_IN_OUT" 0 "CAR_NULL" ;
VAL_ 2654552178 parkingSlotType 7 "PW_DIAGONAL_LINE" 6 "PW_PARALLEL_LINE" 5 "PW_PERPENDICULAR_LINE" 4 "PW_FISHBONE" 3 "PW_DIAGONAL" 2 "PW_PARALLEL" 1 "PW_PERPENDICULAR" 0 "PW_NODIR" ;
VAL_ 2654552169 IeAutoPark_e_AlgoState 4 "Handshake" 3 "Park_Out" 2 "Park_In" 1 "Scanning" 0 "Idle" ;
VAL_ 2654552169 IeAP_e_AutoParkStatus 6 "Complete" 5 "Abort" 4 "Fault" 3 "Active" 2 "Standby" 1 "Initialize" 0 "Off" ;
VAL_ 2654552169 MeAP_e_ParkAssistStatus 4 "Sensor_Fault" 3 "Active" 2 "Standby" 1 "Initialize" 0 "Off" ;
VAL_ 2654552167 TrailerAngleSign 2 "None" 1 "Anticlockwise" 0 "Clockwise" ;
VAL_ 2654552166 MeTRSC_e_TrlrPrsntInfoCAN 2 "TRLR_PRSNT" 1 "NO_TRLR" 0 "UNKNOWN" ;
VAL_ 2654552166 MeSVS_e_DispView2Info 15 "VIEW_15" 14 "VIEW_14" 13 "VIEW_13" 12 "VIEW_12" 11 "VIEW_11" 10 "VIEW_10" 9 "VIEW_9" 8 "VIEW_8" 7 "VIEW_7" 6 "VIEW_6" 5 "VIEW_5" 4 "VIEW_4" 3 "VIEW_3" 2 "VIEW_2" 1 "VIEW_1" 0 "OFF" ;
VAL_ 2654552165 IeTRSC_e_TRSCAbortReas 21 "SNA" 20 "Fail Not Present" 19 "Invalid PROXI/veh configmismatch" 18 "Veh speed > spped req by CVADAS" 17 "Trailer angle too steep" 16 "ECU Voltage too low/high" 15 "No/Invalid response from TRSKM" 14 "TRSC butt pressed on TRSKM/Radio" 13 "No user feedback for 600s" 12 "Driver steering override" 11 "trlr image Cameraview lost inFOV" 10 "Forward direction speed > 25mph" 9 "Driver Door Open" 8 "Engine Status signal = OFF" 7 "Rear Tailgate Open" 6 "Ignition not in RUN" 5 "No/invalid response from Radio" 4 "No/invalid response ORC" 3 "No/invalid response Trans Cont." 2 "No/invalid response EPSM" 1 "No/invalid response BSM" 0 "No/Invalid rspnsEngineController" ;
VAL_ 2654552165 MeTRSC_e_TRSCStat 6 "Fault" 5 "ActiveHoldOvr" 4 "Active" 3 "PreActive" 2 "Calibrating" 1 "Standby" 0 "Off" ;
VAL_ 2654552165 IeTRSC_e_TrlrAngGrapOverSts 2 "SNA" 1 "Active" 0 "Inactive" ;
VAL_ 2654552165 IeTRSC_e_TRSCUnavailReas 20 "SNA" 19 "Fail Not Present" 18 "Invalid PROXI/Veh Conf. Mismatch" 17 "ECU in Plant Mode" 16 "ECU Voltage too low/high" 15 "No/invalid response TRSKM" 14 "Trailer Calibration Failure" 13 "trailer angle too steep" 12 "Trailer not detected by system" 11 "Camera calibration is unknown" 10 "Vehicle not in 'P'" 9 "Driver door open" 8 "Engine status signal = OFF" 7 "Rear tailgate open" 6 "Ignition not in RUN" 5 "No/invalid response Radio" 4 "No/invalid response ORC" 3 "No/invalid response TC" 2 "No/invalid response EPSM" 1 "No/invalid response BSM" 0 "No/invalid rspnsEngineController" ;
VAL_ 2654552165 IeTRSC_e_CamBlockSts 3 "SNA" 2 "Low light" 1 "Camera clear" 0 "Camera blocked" ;
VAL_ 2654552165 IeTRSC_e_TrlrRecogInfo 3 "SNA" 2 "No trailer detected" 1 "Unknown Trailer" 0 "Known Trailer" ;
VAL_ 2654552165 IeTRSC_e_TRSKMSts 2 "SNA" 1 "Not Enabled" 0 "Enabled" ;
VAL_ 2654552165 IeTRSC_e_TRSKMCenBtnSts 3 "SNA" 2 "Struck" 1 "Not Pressed" 0 "Pressed" ;
VAL_ 2654552165 IeTRSC_e_TRSKMBtnSts 3 "SNA" 2 "Stuck" 1 "Not Pressed" 0 "Pressed" ;
VAL_ 2654552165 IeTRSC_e_TrailerID 5 "Trailer_Absent" 4 "Trailer_ID5" 3 "Trailer_ID4" 2 "Trailer_ID3" 1 "Trailer_ID2" 0 "Trailer_ID1" ;
VAL_ 2654552165 IeTRSC_e_GearShiftSts 7 "SNA" 6 "S" 5 "M" 4 "L" 3 "D" 2 "N" 1 "R" 0 "P" ;
VAL_ 2654552165 IeTRSC_e_TrlrPrsntSts 2 "SNA" 1 "Detected" 0 "Not Detected" ;
VAL_ 2654552165 IeTRSC_e_TrlrPrsntFailReas 2 "SNA" 1 "None" 0 "Camera Occlusion/Lowlight Status" ;
VAL_ 2654552165 IeTRSC_e_TrlrCalibSts 2 "SNA" 1 "Not Calibrated" 0 "Calibrated" ;
VAL_ 2654552165 IeTRSC_e_TrlrCalibManState 3 "SNA" 2 "None" 1 "Intersection turn left or right" 0 "Drive straight" ;
VAL_ 2654552165 IeTRSC_e_TrlrCalibFailReas 4 "SNA" 3 "None" 2 "Camera Occlusion/Lowlight Status" 1 "Require more straight driving" 0 "Need more turn radius/arc length" ;
VAL_ 2654552151 MeTRSC_e_TrlrAngSign 2 "None" 1 "Anticlockwise" 0 "Clockwise" ;
VAL_ 2654552151 MeTRSC_e_TrlrPrsntInfo 2 "TRLR_PRSNT" 1 "NO_TRLR" 0 "UNKNOWN" ;
VAL_ 2654552151 MeTRSC_e_TrlrRecogInfo 1 "Known" 0 "Unknown" ;
VAL_ 2654552151 MeTRSC_e_TrlrCalInfo 2 "Undefined" 1 "Calibrated" 0 "Not Calibrated" ;
VAL_ 2654552151 MeTRSC_e_TrailerID 6 "Trailer_MAX" 5 "Trailer_Absent" 4 "Trailer_ID5" 3 "Trailer_ID4" 2 "Trailer_ID3" 1 "Trailer_ID2" 0 "Trailer_ID1" ;
VAL_ 2654552151 MeTRSC_e_CalFail 2 "More Turn Needed" 1 "Camera Blocked" 0 "No Failure" ;
VAL_ 2654552151 MeTRSC_e_TADCalibrationSubstate 2 "Wait" 1 "TurnLeftOrRight" 0 "DriveStraight" ;
VAL_ 2654552151 MeTRSC_e_TurnAroundSubState 2 "Wait" 1 "TurnLeftOrRight" 0 "DriveStraight" ;
VAL_ 2654552151 MeTRSC_e_TADState 7 "Trackinglost" 6 "AngleDetection" 5 "Turnaround" 4 "ScanningForTrailer" 3 "Calibration" 2 "TrailerRecognition" 1 "TrailerDetection" 0 "Idle" ;
VAL_ 2654552150 LastViewBeforeTestPattern_e 37 "ViewCount          " 36 "BlindRight" 35 "BlindLeft" 34 "THAZoomRearView2   " 33 "THAZoomRearView1   " 32 "THANormalRearView  " 31 "TRGRightCurbView   " 30 "TRGLeftCurbView   " 29 "FrontWithTiretracks" 28 "TRGRightZoomView   " 27 "TRGRightView  " 26 "TRGLeftZoomView " 25 "TRGLeftView        " 24 "TRG34L14RZoomView  " 23 "TRG34L14RView      " 22 "TRG14L34RZoomView  " 21 "TRG14L34RView      " 20 "TRG5050ZoomView   " 19 "TRG5050View        " 18 "CHMSL_ZoomView     " 17 "CHMSL_NormalView " 16 "BUZRV      " 15 "BUNRV       " 14 "RVCOnlyZoomView    " 13 "RVCOnlyNormalView  " 12 "NonViewRequested   " 11 "QuadView   " 10 "RAW_ECU   " 9 "RAW_5th       " 8 "RAW_Right       " 7 "RAW_Rear           " 6 "RAW_Left   " 5 "RAW_Front  " 4 "RearCrossView      " 3 "FrontCrossView     " 2 "RearTopView        " 1 "FrontTopView       " 0 "NoView             " ;
VAL_ 2654552150 Prev_DisplayedViewByAcore_e 37 "ViewCount          " 36 "BlindRight" 35 "BlindLeft" 34 "THAZoomRearView2   " 33 "THAZoomRearView1   " 32 "THANormalRearView  " 31 "TRGRightCurbView   " 30 "TRGLeftCurbView   " 29 "FrontWithTiretracks" 28 "TRGRightZoomView   " 27 "TRGRightView  " 26 "TRGLeftZoomView " 25 "TRGLeftView        " 24 "TRG34L14RZoomView  " 23 "TRG34L14RView      " 22 "TRG14L34RZoomView  " 21 "TRG14L34RView      " 20 "TRG5050ZoomView   " 19 "TRG5050View        " 18 "CHMSL_ZoomView     " 17 "CHMSL_NormalView " 16 "BUZRV      " 15 "BUNRV       " 14 "RVCOnlyZoomView    " 13 "RVCOnlyNormalView  " 12 "NonViewRequested   " 11 "QuadView   " 10 "RAW_ECU   " 9 "RAW_5th       " 8 "RAW_Right       " 7 "RAW_Rear           " 6 "RAW_Left   " 5 "RAW_Front  " 4 "RearCrossView      " 3 "FrontCrossView     " 2 "RearTopView        " 1 "FrontTopView       " 0 "NoView             " ;
VAL_ 2654552150 Curr_DisplayedViewByAcore_e 37 "ViewCount          " 36 "BlindRight" 35 "BlindLeft" 34 "THAZoomRearView2   " 33 "THAZoomRearView1   " 32 "THANormalRearView  " 31 "TRGRightCurbView   " 30 "TRGLeftCurbView   " 29 "FrontWithTiretracks" 28 "TRGRightZoomView   " 27 "TRGRightView  " 26 "TRGLeftZoomView " 25 "TRGLeftView        " 24 "TRG34L14RZoomView  " 23 "TRG34L14RView      " 22 "TRG14L34RZoomView  " 21 "TRG14L34RView      " 20 "TRG5050ZoomView   " 19 "TRG5050View        " 18 "CHMSL_ZoomView     " 17 "CHMSL_NormalView " 16 "BUZRV      " 15 "BUNRV       " 14 "RVCOnlyZoomView    " 13 "RVCOnlyNormalView  " 12 "NonViewRequested   " 11 "QuadView   " 10 "RAW_ECU   " 9 "RAW_5th       " 8 "RAW_Right       " 7 "RAW_Rear           " 6 "RAW_Left   " 5 "RAW_Front  " 4 "RearCrossView      " 3 "FrontCrossView     " 2 "RearTopView        " 1 "FrontTopView       " 0 "NoView             " ;
VAL_ 2654552150 Prev_RequestedViewByHmiM_e 37 "ViewCount          " 36 "BlindRight" 35 "BlindLeft" 34 "THAZoomRearView2   " 33 "THAZoomRearView1   " 32 "THANormalRearView  " 31 "TRGRightCurbView   " 30 "TRGLeftCurbView   " 29 "FrontWithTiretracks" 28 "TRGRightZoomView   " 27 "TRGRightView  " 26 "TRGLeftZoomView " 25 "TRGLeftView        " 24 "TRG34L14RZoomView  " 23 "TRG34L14RView      " 22 "TRG14L34RZoomView  " 21 "TRG14L34RView      " 20 "TRG5050ZoomView   " 19 "TRG5050View        " 18 "CHMSL_ZoomView     " 17 "CHMSL_NormalView " 16 "BUZRV      " 15 "BUNRV       " 14 "RVCOnlyZoomView    " 13 "RVCOnlyNormalView  " 12 "NonViewRequested   " 11 "QuadView   " 10 "RAW_ECU   " 9 "RAW_5th       " 8 "RAW_Right       " 7 "RAW_Rear           " 6 "RAW_Left   " 5 "RAW_Front  " 4 "RearCrossView      " 3 "FrontCrossView     " 2 "RearTopView        " 1 "FrontTopView       " 0 "NoView             " ;
VAL_ 2654552150 Curr_RequestedViewByHmiM_e 37 "ViewCount          " 36 "BlindRight" 35 "BlindLeft" 34 "THAZoomRearView2   " 33 "THAZoomRearView1   " 32 "THANormalRearView  " 31 "TRGRightCurbView   " 30 "TRGLeftCurbView   " 29 "FrontWithTiretracks" 28 "TRGRightZoomView   " 27 "TRGRightView  " 26 "TRGLeftZoomView " 25 "TRGLeftView        " 24 "TRG34L14RZoomView  " 23 "TRG34L14RView      " 22 "TRG14L34RZoomView  " 21 "TRG14L34RView      " 20 "TRG5050ZoomView   " 19 "TRG5050View        " 18 "CHMSL_ZoomView     " 17 "CHMSL_NormalView " 16 "BUZRV      " 15 "BUNRV       " 14 "RVCOnlyZoomView    " 13 "RVCOnlyNormalView  " 12 "NonViewRequested   " 11 "QuadView   " 10 "RAW_ECU   " 9 "RAW_5th       " 8 "RAW_Right       " 7 "RAW_Rear           " 6 "RAW_Left   " 5 "RAW_Front  " 4 "RearCrossView      " 3 "FrontCrossView     " 2 "RearTopView        " 1 "FrontTopView       " 0 "NoView             " ;
VAL_ 2654552150 Prev_SystemState_e 2 "RVC_Only" 1 "SystemONVideoON" 0 "SystemONVideoOFF" ;
VAL_ 2654552150 Curr_SystemState_e 2 "RVC_Only" 1 "SystemONVideoON" 0 "SystemONVideoOFF" ;
VAL_ 2654552150 M_FFClatch_e 1 "M_FFClatch_Set" 0 "M_FFClatch_NotSet" ;
VAL_ 2654552150 M_BURV_Memory_e 1 "M_ZoomLevel_Zoom" 0 "M_ZoomLevel_Normal" ;
VAL_ 2654552149 tchScrnStatus_e 7 "CM_TCH_STAT_SNA" 6 "TCH_CFG_MAX    " 5 "TCH_CFG_OFFSET " 4 "TCH_CFG_RES    " 2 "TCH_PS_CAN     " 1 "TCH_PSD     " 0 "TCH_NOT_PSD    " ;
VAL_ 2654552149 View_Error_e 1 "View_NoError" 0 "View_ForceDEFAULT" ;
VAL_ 2654552149 DynOvl_Error_e 1 "DynOvl_NoError" 0 "DynOvl_ForceOFF" ;
VAL_ 2654552149 SoftBtn_Error_e 1 "SoftBtns_Functional" 0 "SoftBtns_NotFunctional" ;
VAL_ 2654552149 ImageDefeat_Error_e 2 "ImageDefeat_NoError " 1 "ImageDefeat_ForceON " 0 "ImageDefeat_ForceOFF" ;
VAL_ 2654552149 tgwDispStatus_e 21 "TGW_DISP_STAT_SNA    " 7 "DISP_SVS_MORECAMS_POPUP" 6 "DISP_WIRLESS_CAMERA  " 5 "TGW_DISP_STAT_SNA    " 4 "DISP_REAR_CAMERA     " 0 "DISP_OFF     " ;
VAL_ 2654552149 CameraDisplaySts2_e 14 "CameraDisplaySts2_View14" 13 "CameraDisplaySts2_View13" 12 "CameraDisplaySts2_View12" 11 "CameraDisplaySts2_View11" 10 "CameraDisplaySts2_View10" 9 "CameraDisplaySts2_View9" 8 "CameraDisplaySts2_View8" 7 "CameraDisplaySts2_View7" 6 "CameraDisplaySts2_View6" 5 "CameraDisplaySts2_View5" 4 "CameraDisplaySts2_View4" 3 "CameraDisplaySts2_View3" 2 "CameraDisplaySts2_View2   " 1 "CameraDisplaySts2_View1   " 0 "CameraDisplaySts2_OFF     " -1 "CameraDisplaySts2_Enforcer" ;
VAL_ 2654552149 prndStatus_e 21 "PRND_STAT_SNA  " 16 "PRND_STAT_UNDEF" 5 "PRND_STAT_NOT_R" 4 "PRND_STAT_D    " 3 "PRND_STAT_N    " 2 "PRND_STAT_R    " 1 "PRND_STAT_P    " 0 "PRND_STAT_NA   " ;
VAL_ 2654552149 transEquipped_e 2 "TRANS_SNA      " 1 "TRANS_MANUAL   " 0 "TRANS_AUTOMATIC" ;
VAL_ 2654552149 ignitionStatus_e 7 "IGN_SNA    " 5 "IGN_START  " 4 "IGN_RUN    " 3 "IGN_OFF_ACC" 2 "IGN_ACC    " 1 "IGN_OFF    " 0 "IGN_LK     " ;
VAL_ 2654552149 trscStat_e 597 "TRSC_INVALID    " 7 "TRSC_SNA        " 4 "TRSC_ACTIVE     " 3 "TRSC_PRE_ACTIVE " 2 "TRSC_CALIBRATING" 1 "TRSC_STANDBY    " 0 "TRSC_OFF        " ;
VAL_ 2654552149 NetCfg_TRSCM_e 2 "TRSCM_Prsnt_SNA  " 1 "TRSCM_Prsnt_TRUE " 0 "TRSCM_Prsnt_FALSE" ;
VAL_ 2654552149 revGear_e 2 "REV_GEAR_SNA" 1 "REV_GEAR_ENGAGED" 0 "REV_GEAR_NOT_ENGAGED" ;
VAL_ 2654552149 lrwsST_e 4 "LRWS_ST_SNA    " 3 "LRWS_ST_ERR_INI" 2 "LRWS_ST_ERR    " 1 "LRWS_ST_INI    " 0 "LRWS_ST_OK     " ;
VAL_ 2654552148 TrailerCalibrationStatus 2 "TeTRSC_e_TrlrCalInfo_Undefined" 1 "TeTRSC_e_TrlrCalInfo_Calibrated" 0 "TrlrCalInfo_NotCalibrated" -1 "TeTRSC_e_TrlrCalInfo_MAX" ;
VAL_ 2654552148 TrscStatus 7 "TeTRSC_e_TRSCStat_SNA" 6 "TeTRSC_e_TRSCStat_Fault" 5 "TeTRSC_e_TRSCStat_ActiveHoldOvr" 4 "TeTRSC_e_TRSCStat_Active" 3 "TeTRSC_e_TRSCStat_PreActive" 2 "TeTRSC_e_TRSCStat_Calibrating" 1 "TeTRSC_e_TRSCStat_Standby" 0 "TeTRSC_e_TRSCStat_Off      " -1 "TeTRSC_e_TRSCStat_MAX" ;
VAL_ 2654552148 TrailerAngleSign 1 "Anticlockwise" 0 "Clockwise" ;
VAL_ 2654552148 Prev_TRG_Stat 3 "TRG_STAT_SNA" 2 "TRG_MANU_PAN" 1 "TRG_AUTO_PAN" 0 "TRG_INACTIVE" ;
VAL_ 2654552148 Curr_TRG_Stat 3 "TRG_STAT_SNA" 2 "TRG_MANU_PAN" 1 "TRG_AUTO_PAN" 0 "TRG_INACTIVE" ;
SIG_VALTYPE_ 2654552193 obj_Pos_Longi : 1;
SIG_VALTYPE_ 2654552193 obj_Pos_Lat : 1;
SIG_VALTYPE_ 2654552192 MeTHA_deg_CplrAng : 1;
SIG_VALTYPE_ 2654552185 MeTHA_deg_RoadWhlAng : 1;
SIG_VALTYPE_ 2654552184 LMD_m_Line_2_End_Range : 1;
SIG_VALTYPE_ 2654552184 LMD_m_Line_2_Start_Range : 1;
SIG_VALTYPE_ 2654552184 LMD_rad_Line_2_Heading : 1;
SIG_VALTYPE_ 2654552184 LMD_m_Line_2_Offset : 1;
SIG_VALTYPE_ 2654552184 LMD_pct_Line_2_Confidence : 1;
SIG_VALTYPE_ 2654552184 LMD_px_Line_2_Curvature : 1;
SIG_VALTYPE_ 2654552184 LMD_m_Line_1_End_Range : 1;
SIG_VALTYPE_ 2654552184 LMD_m_Line_1_Start_Range : 1;
SIG_VALTYPE_ 2654552184 LMD_rad_Line_1_Heading : 1;
SIG_VALTYPE_ 2654552184 LMD_m_Line_1_Offset : 1;
SIG_VALTYPE_ 2654552184 LMD_px_Line_1_Curvature : 1;
SIG_VALTYPE_ 2654552184 LMD_pct_Line_1_Confidence : 1;
SIG_VALTYPE_ 2654552183 MOT_ObjectDimensions_1_9 : 1;
SIG_VALTYPE_ 2654552183 MOT_ObjectDimensions_0_9 : 1;
SIG_VALTYPE_ 2654552183 MOT_ObjVelY_9 : 1;
SIG_VALTYPE_ 2654552183 MOT_ObjVelX_9 : 1;
SIG_VALTYPE_ 2654552183 MOT_ClosestPntDist_1_9 : 1;
SIG_VALTYPE_ 2654552183 MOT_ClosestPntDist_0_9 : 1;
SIG_VALTYPE_ 2654552183 MOT_ObjectDimensions_1_8 : 1;
SIG_VALTYPE_ 2654552183 MOT_ObjectDimensions_0_8 : 1;
SIG_VALTYPE_ 2654552183 MOT_ObjVelY_8 : 1;
SIG_VALTYPE_ 2654552183 MOT_ObjVelX_8 : 1;
SIG_VALTYPE_ 2654552183 MOT_ClosestPntDist_1_8 : 1;
SIG_VALTYPE_ 2654552183 MOT_ClosestPntDist_0_8 : 1;
SIG_VALTYPE_ 2654552182 MOT_ObjectDimensions_1_7 : 1;
SIG_VALTYPE_ 2654552182 MOT_ObjectDimensions_0_7 : 1;
SIG_VALTYPE_ 2654552182 MOT_ObjVelY_7 : 1;
SIG_VALTYPE_ 2654552182 MOT_ObjVelX_7 : 1;
SIG_VALTYPE_ 2654552182 MOT_ClosestPntDist_1_7 : 1;
SIG_VALTYPE_ 2654552182 MOT_ClosestPntDist_0_7 : 1;
SIG_VALTYPE_ 2654552182 MOT_ObjectDimensions_1_6 : 1;
SIG_VALTYPE_ 2654552182 MOT_ObjectDimensions_0_6 : 1;
SIG_VALTYPE_ 2654552182 MOT_ObjVelY_6 : 1;
SIG_VALTYPE_ 2654552182 MOT_ObjVelX_6 : 1;
SIG_VALTYPE_ 2654552182 MOT_ClosestPntDist_1_6 : 1;
SIG_VALTYPE_ 2654552182 MOT_ClosestPntDist_0_6 : 1;
SIG_VALTYPE_ 2654552181 MOT_ObjectDimensions_1_5 : 1;
SIG_VALTYPE_ 2654552181 MOT_ObjectDimensions_0_5 : 1;
SIG_VALTYPE_ 2654552181 MOT_ObjVelY_5 : 1;
SIG_VALTYPE_ 2654552181 MOT_ObjVelX_5 : 1;
SIG_VALTYPE_ 2654552181 MOT_ClosestPntDist_1_5 : 1;
SIG_VALTYPE_ 2654552181 MOT_ClosestPntDist_0_5 : 1;
SIG_VALTYPE_ 2654552181 MOT_ObjectDimensions_1_4 : 1;
SIG_VALTYPE_ 2654552181 MOT_ObjectDimensions_0_4 : 1;
SIG_VALTYPE_ 2654552181 MOT_ObjVelY_4 : 1;
SIG_VALTYPE_ 2654552181 MOT_ObjVelX_4 : 1;
SIG_VALTYPE_ 2654552181 MOT_ClosestPntDist_1_4 : 1;
SIG_VALTYPE_ 2654552181 MOT_ClosestPntDist_0_4 : 1;
SIG_VALTYPE_ 2654552180 MOT_ObjectDimensions_1_3 : 1;
SIG_VALTYPE_ 2654552180 MOT_ObjectDimensions_0_3 : 1;
SIG_VALTYPE_ 2654552180 MOT_ObjVelY_3 : 1;
SIG_VALTYPE_ 2654552180 MOT_ObjVelX_3 : 1;
SIG_VALTYPE_ 2654552180 MOT_ClosestPntDist_1_3 : 1;
SIG_VALTYPE_ 2654552180 MOT_ClosestPntDist_0_3 : 1;
SIG_VALTYPE_ 2654552180 MOT_ObjectDimensions_1_2 : 1;
SIG_VALTYPE_ 2654552180 MOT_ObjectDimensions_0_2 : 1;
SIG_VALTYPE_ 2654552180 MOT_ObjVelY_2 : 1;
SIG_VALTYPE_ 2654552180 MOT_ObjVelX_2 : 1;
SIG_VALTYPE_ 2654552180 MOT_ClosestPntDist_1_2 : 1;
SIG_VALTYPE_ 2654552180 MOT_ClosestPntDist_0_2 : 1;
SIG_VALTYPE_ 2654552179 MOT_ObjectDimensions_1_1 : 1;
SIG_VALTYPE_ 2654552179 MOT_ObjectDimensions_0_1 : 1;
SIG_VALTYPE_ 2654552179 MOT_ObjVelY_1 : 1;
SIG_VALTYPE_ 2654552179 MOT_ObjVelX_1 : 1;
SIG_VALTYPE_ 2654552179 MOT_ClosestPntDist_1_1 : 1;
SIG_VALTYPE_ 2654552179 MOT_ClosestPntDist_0_1 : 1;
SIG_VALTYPE_ 2654552179 MOT_ObjectDimensions_1_0 : 1;
SIG_VALTYPE_ 2654552179 MOT_ObjectDimensions_0_0 : 1;
SIG_VALTYPE_ 2654552179 MOT_ObjVelY_0 : 1;
SIG_VALTYPE_ 2654552179 MOT_ObjVelX_0 : 1;
SIG_VALTYPE_ 2654552179 MOT_ClosestPntDist_1_0 : 1;
SIG_VALTYPE_ 2654552179 MOT_ClosestPntDist_0_0 : 1;
SIG_VALTYPE_ 2654552178 MaAP_m_ParkSpot4RearStreetY : 1;
SIG_VALTYPE_ 2654552178 MaAP_m_ParkSpot4RearStreetX : 1;
SIG_VALTYPE_ 2654552178 MaAP_m_ParkSpot3RearBorderY : 1;
SIG_VALTYPE_ 2654552178 MaAP_m_ParkSpot3RearBorderX : 1;
SIG_VALTYPE_ 2654552178 MaAP_m_ParkSpot2FrntBorderY : 1;
SIG_VALTYPE_ 2654552178 MaAP_m_ParkSpot2FrntBorderX : 1;
SIG_VALTYPE_ 2654552178 MaAP_m_ParkSpot1FrntStreetY : 1;
SIG_VALTYPE_ 2654552178 MaAP_m_ParkSpot1FrntStreetX : 1;
SIG_VALTYPE_ 2654552177 IeVBII_nfcd_MinDisToCollisionObj : 1;
SIG_VALTYPE_ 2654552177 NFCD_DistanceToClosestPoint_1_9 : 1;
SIG_VALTYPE_ 2654552177 NFCD_DistanceToClosestPoint_0_9 : 1;
SIG_VALTYPE_ 2654552177 NFCD_DistanceToClosestPoint_1_8 : 1;
SIG_VALTYPE_ 2654552177 NFCD_DistanceToClosestPoint_0_8 : 1;
SIG_VALTYPE_ 2654552177 NFCD_DistanceToClosestPoint_1_7 : 1;
SIG_VALTYPE_ 2654552177 NFCD_DistanceToClosestPoint_0_7 : 1;
SIG_VALTYPE_ 2654552177 NFCD_DistanceToClosestPoint_1_6 : 1;
SIG_VALTYPE_ 2654552177 NFCD_DistanceToClosestPoint_0_6 : 1;
SIG_VALTYPE_ 2654552177 NFCD_DistanceToClosestPoint_1_5 : 1;
SIG_VALTYPE_ 2654552177 NFCD_DistanceToClosestPoint_0_5 : 1;
SIG_VALTYPE_ 2654552176 NFCD_DistanceToClosestPoint_1_4 : 1;
SIG_VALTYPE_ 2654552176 NFCD_DistanceToClosestPoint_0_4 : 1;
SIG_VALTYPE_ 2654552176 NFCD_DistanceToClosestPoint_1_3 : 1;
SIG_VALTYPE_ 2654552176 NFCD_DistanceToClosestPoint_0_3 : 1;
SIG_VALTYPE_ 2654552176 NFCD_DistanceToClosestPoint_1_2 : 1;
SIG_VALTYPE_ 2654552176 NFCD_DistanceToClosestPoint_0_2 : 1;
SIG_VALTYPE_ 2654552176 NFCD_DistanceToClosestPoint_1_1 : 1;
SIG_VALTYPE_ 2654552176 NFCD_DistanceToClosestPoint_0_1 : 1;
SIG_VALTYPE_ 2654552176 NFCD_DistanceToClosestPoint_1_0 : 1;
SIG_VALTYPE_ 2654552176 NFCD_DistanceToClosestPoint_0_0 : 1;
SIG_VALTYPE_ 2654552169 MeAP_e_Park_state : 1;
SIG_VALTYPE_ 2654552169 MeAP_a_ThrtlCmd : 1;
SIG_VALTYPE_ 2654552169 MeAP_a_BrkCmd : 1;
SIG_VALTYPE_ 2654552169 MeAP_deg_StrCmd : 1;
SIG_VALTYPE_ 2654552167 Trailer_tracking_confidence : 1;
SIG_VALTYPE_ 2654552167 Trailer_Recognition_Confidence : 1;
SIG_VALTYPE_ 2654552167 JackknifeThrAngle : 1;
SIG_VALTYPE_ 2654552167 JackknifeAngle : 1;
SIG_VALTYPE_ 2654552167 hitchLength : 1;
SIG_VALTYPE_ 2654552167 TADAngleRate : 1;
SIG_VALTYPE_ 2654552167 trailerAngle : 1;
SIG_VALTYPE_ 2654552166 ReservedSignal2 : 1;
SIG_VALTYPE_ 2654552166 ReservedSignal1 : 1;
SIG_VALTYPE_ 2654552166 MeTRSC_deg_TADAngleSMVC : 1;
SIG_VALTYPE_ 2654552166 MeTRSC_M_SteeringTorqInfo : 1;
SIG_VALTYPE_ 2654552166 MeTRSC_deg_KnobAngle : 1;
SIG_VALTYPE_ 2654552166 MeTRSC_deg_DetJackKnifeAngle : 1;
SIG_VALTYPE_ 2654552166 MeTRSC_m_DetTrailerBeamLen : 1;
SIG_VALTYPE_ 2654552166 MeTRSC_deg_DetJackknifeThrAngle : 1;
SIG_VALTYPE_ 2654552165 IeTRSC_kph_VehSpeedVSOSig : 1;
SIG_VALTYPE_ 2654552165 IeTRSC_M_TRSCStrTrq : 1;
SIG_VALTYPE_ 2654552165 IeTRSC_deg_JackknifeThrAngle : 1;
SIG_VALTYPE_ 2654552165 IeTRSC_deg_TADAngle : 1;
SIG_VALTYPE_ 2654552165 IeTRSC_deg_TrlrAngKnob : 1;
SIG_VALTYPE_ 2654552165 IeTRSC_deg_FrntWhlAng : 1;
SIG_VALTYPE_ 2654552164 Roll_f32_EOL_Right : 1;
SIG_VALTYPE_ 2654552164 Pitch_f32_EOL_Right : 1;
SIG_VALTYPE_ 2654552164 Yaw_f32_EOL_Right : 1;
SIG_VALTYPE_ 2654552164 Z_f32_EOL_Right : 1;
SIG_VALTYPE_ 2654552164 Y_f32_EOL_Right : 1;
SIG_VALTYPE_ 2654552164 X_f32_EOL_Right : 1;
SIG_VALTYPE_ 2654552164 Pitch_f32_EOL_Rear : 1;
SIG_VALTYPE_ 2654552164 Roll_f32_EOL_Rear : 1;
SIG_VALTYPE_ 2654552164 Yaw_f32_EOL_Rear : 1;
SIG_VALTYPE_ 2654552164 Z_f32_EOL_Rear : 1;
SIG_VALTYPE_ 2654552164 Y_f32_EOL_Rear : 1;
SIG_VALTYPE_ 2654552164 X_f32_EOL_Rear : 1;
SIG_VALTYPE_ 2654552163 Z_f32_Current_Right : 1;
SIG_VALTYPE_ 2654552163 Z_f32_Current_Rear : 1;
SIG_VALTYPE_ 2654552163 Pitch_f32_Current_Right : 1;
SIG_VALTYPE_ 2654552163 Pitch_f32_Current_Rear : 1;
SIG_VALTYPE_ 2654552163 Roll_f32_Current_Right : 1;
SIG_VALTYPE_ 2654552163 Roll_f32_Current_Rear : 1;
SIG_VALTYPE_ 2654552163 Yaw_f32_Current_Right : 1;
SIG_VALTYPE_ 2654552163 Yaw_f32_Current_Rear : 1;
SIG_VALTYPE_ 2654552163 Y_f32_Current_Right : 1;
SIG_VALTYPE_ 2654552163 Y_f32_Current_Rear : 1;
SIG_VALTYPE_ 2654552163 X_f32_Current_Right : 1;
SIG_VALTYPE_ 2654552163 X_f32_Current_Rear : 1;
SIG_VALTYPE_ 2654552160 Z_f32_Current_Rear : 1;
SIG_VALTYPE_ 2654552160 Y_f32_Current_Rear : 1;
SIG_VALTYPE_ 2654552160 X_f32_Current_Rear : 1;
SIG_VALTYPE_ 2654552160 Pitch_f32_OC_Right : 1;
SIG_VALTYPE_ 2654552160 Roll_f32_OC_Right : 1;
SIG_VALTYPE_ 2654552160 Yaw_f32_OC_Right : 1;
SIG_VALTYPE_ 2654552160 Pitch_f32_OC_Rear : 1;
SIG_VALTYPE_ 2654552160 Roll_f32_OC_Rear : 1;
SIG_VALTYPE_ 2654552160 Yaw_f32_OC_Rear : 1;
SIG_VALTYPE_ 2654552160 Pitch_f32_OC_Left : 1;
SIG_VALTYPE_ 2654552160 Roll_f32_OC_Left : 1;
SIG_VALTYPE_ 2654552160 Yaw_f32_OC_Left : 1;
SIG_VALTYPE_ 2654552160 Pitch_f32_OC_Front : 1;
SIG_VALTYPE_ 2654552160 Roll_f32_OC_Front : 1;
SIG_VALTYPE_ 2654552160 Yaw_f32_OC_Front : 1;
SIG_VALTYPE_ 2654552153 Pitch_f32_SC_Right : 1;
SIG_VALTYPE_ 2654552153 Roll_f32_SC_Right : 1;
SIG_VALTYPE_ 2654552153 Yaw_f32_SC_Right : 1;
SIG_VALTYPE_ 2654552153 Pitch_f32_SC_Rear : 1;
SIG_VALTYPE_ 2654552153 Roll_f32_SC_Rear : 1;
SIG_VALTYPE_ 2654552153 Yaw_f32_SC_Rear : 1;
SIG_VALTYPE_ 2654552153 Pitch_f32_SC_Left : 1;
SIG_VALTYPE_ 2654552153 Roll_f32_SC_Left : 1;
SIG_VALTYPE_ 2654552153 Yaw_f32_SC_Left : 1;
SIG_VALTYPE_ 2654552153 Pitch_f32_SC_Front : 1;
SIG_VALTYPE_ 2654552153 Roll_f32_SC_Front : 1;
SIG_VALTYPE_ 2654552153 Yaw_f32_SC_Front : 1;
SIG_VALTYPE_ 2654552152 Pitch_f32_EOL_Left : 1;
SIG_VALTYPE_ 2654552152 Roll_f32_EOL_Left : 1;
SIG_VALTYPE_ 2654552152 Yaw_f32_EOL_Left : 1;
SIG_VALTYPE_ 2654552152 Z_f32_EOL_Left : 1;
SIG_VALTYPE_ 2654552152 Y_f32_EOL_Left : 1;
SIG_VALTYPE_ 2654552152 X_f32_EOL_Left : 1;
SIG_VALTYPE_ 2654552152 Pitch_f32_EOL_Front : 1;
SIG_VALTYPE_ 2654552152 Roll_f32_EOL_Front : 1;
SIG_VALTYPE_ 2654552152 Yaw_f32_EOL_Front : 1;
SIG_VALTYPE_ 2654552152 Z_f32_EOL_Front : 1;
SIG_VALTYPE_ 2654552152 Y_f32_EOL_Front : 1;
SIG_VALTYPE_ 2654552152 X_f32_EOL_Front : 1;
SIG_VALTYPE_ 2654552151 ReservedTRSCSig2 : 1;
SIG_VALTYPE_ 2654552151 ReservedTRSCSig1 : 1;
SIG_VALTYPE_ 2654552151 IeTRSC_pct_TrlrRecogConf : 1;
SIG_VALTYPE_ 2654552151 IeTRSC_pct_TrlrTrackConf : 1;
SIG_VALTYPE_ 2654552151 MeTRSC_m_HitchLength : 1;
SIG_VALTYPE_ 2654552151 IeTRSC_m_TrlrWhlBaseEff : 1;
SIG_VALTYPE_ 2654552151 IeTRSC_pct_TrlrDetConf : 1;
SIG_VALTYPE_ 2654552151 MeTRSC_deg_JackKnifeAngle : 1;
SIG_VALTYPE_ 2654552151 MeTRSC_m_TrailerBeamLen : 1;
SIG_VALTYPE_ 2654552151 MeTRSC_deg_JackknifeThrAngle : 1;
SIG_VALTYPE_ 2654552151 MeTRSC_deg_TADAngleRate : 1;
SIG_VALTYPE_ 2654552151 MeTRSC_deg_MaxAllowedTADAngle : 1;
SIG_VALTYPE_ 2654552151 MeTRSC_deg_TADAngle : 1;
SIG_VALTYPE_ 2654552149 vehicleSpeed_f32 : 1;
SIG_VALTYPE_ 2654552149 steeringWheelAngle_f32 : 1;
SIG_VALTYPE_ 2654552148 JackKnifeAngle : 1;
SIG_VALTYPE_ 2654552148 KnobAngle : 1;
SIG_VALTYPE_ 2654552148 MaxTadAngle : 1;
SIG_VALTYPE_ 2654552148 TadAngle : 1;
